VERSION ""

NS_ :

BS_:

BU_: ETH

BO_ 832 VCFRONT_alertMatrix: 8 Vector__XXX
 SG_ VCFRONT_matrixIndex M : 0|4@1+ (1,0) [0|0] "" Vector__XXX
 SG_ VCFRONT_a001_WatchdogReset m0 : 4|1@1+ (1,0) [0|0] "" Vector__XXX
 SG_ VCFRONT_a061_XCPConnected m1 : 4|1@1+ (1,0) [0|0] "" Vector__XXX
 SG_ VCFRONT_a121_pumpBatICLatchFault m2 : 4|1@1+ (1,0) [0|0] "" Vector__XXX
 SG_ VCFRONT_a181_homelinkMIA m3 : 4|1@1+ (1,0) [0|0] "" Vector__XXX
 SG_ VCFRONT_a301_wipersFactoryDisabled m5 : 4|1@1+ (1,0) [0|0] "" Vector__XXX
 SG_ VCFRONT_a361_washerFluidLowMomentary m6 : 4|1@1+ (1,0) [0|0] "" Vector__XXX
 SG_ VCFRONT_a421_leftHeadlampUartCondition m7 : 4|1@1+ (1,0) [0|0] "" Vector__XXX
 SG_ VCFRONT_a481_vnf1048SelfTestFailure m8 : 4|1@1+ (1,0) [0|0] "" Vector__XXX
 SG_ VCFRONT_a541_LVBatteryChargeOCLevel1 m9 : 4|1@1+ (1,0) [0|0] "" Vector__XXX
 SG_ VCFRONT_a601_autopilotAirPurgeLimitReached m10 : 4|1@1+ (1,0) [0|0] "" Vector__XXX
 SG_ VCFRONT_a661_mculessLeftHeadlampCurrentAlertDbg m11 : 4|1@1+ (1,0) [0|0] "" Vector__XXX
 SG_ VCFRONT_a002_PowerLossReset m0 : 5|1@1+ (1,0) [0|0] "" Vector__XXX
 SG_ VCFRONT_a062_XCPWasConnected m1 : 5|1@1+ (1,0) [0|0] "" Vector__XXX
 SG_ VCFRONT_a122_pumpBatICWarning m2 : 5|1@1+ (1,0) [0|0] "" Vector__XXX
 SG_ VCFRONT_a182_replaceLVBattery m3 : 5|1@1+ (1,0) [0|0] "" Vector__XXX
 SG_ VCFRONT_a242_drveBlckdVltgeTooLow m4 : 5|1@1+ (1,0) [0|0] "" Vector__XXX
 SG_ VCFRONT_a302_wiperCommError m5 : 5|1@1+ (1,0) [0|0] "" Vector__XXX
 SG_ VCFRONT_a362_TLVBMS_AllSocCorrectionTimeout m6 : 5|1@1+ (1,0) [0|0] "" Vector__XXX
 SG_ VCFRONT_a482_rightHeadlampMigrationDebug m8 : 5|1@1+ (1,0) [0|0] "" Vector__XXX
 SG_ VCFRONT_a542_refrigerantReclaim m9 : 5|1@1+ (1,0) [0|0] "" Vector__XXX
 SG_ VCFRONT_a662_mculessRightHeadlampCurrentAlertDbg m11 : 5|1@1+ (1,0) [0|0] "" Vector__XXX
 SG_ VCFRONT_a003_SWAssertion m0 : 6|1@1+ (1,0) [0|0] "" Vector__XXX
 SG_ VCFRONT_a063_SwitchFault m1 : 6|1@1+ (1,0) [0|0] "" Vector__XXX
 SG_ VCFRONT_a123_pumpPtICLatchFault m2 : 6|1@1+ (1,0) [0|0] "" Vector__XXX
 SG_ VCFRONT_a183_replaceLVBattery2 m3 : 6|1@1+ (1,0) [0|0] "" Vector__XXX
 SG_ VCFRONT_a243_LVOverchargeInstc m4 : 6|1@1+ (1,0) [0|0] "" Vector__XXX
 SG_ VCFRONT_a303_frunkAccessPostActive m5 : 6|1@1+ (1,0) [0|0] "" Vector__XXX
 SG_ VCFRONT_a363_TLVBMS_BleedBasedWeakShort m6 : 6|1@1+ (1,0) [0|0] "" Vector__XXX
 SG_ VCFRONT_a423_TLVBMS_BrickUnderVoltageFault m7 : 6|1@1+ (1,0) [0|0] "" Vector__XXX
 SG_ VCFRONT_a483_leftHeadlampStepperMotorFault m8 : 6|1@1+ (1,0) [0|0] "" Vector__XXX
 SG_ VCFRONT_a543_compressorLowFlowDeliveryDetected m9 : 6|1@1+ (1,0) [0|0] "" Vector__XXX
 SG_ VCFRONT_a663_leftHeadlampUartWaterMarkWarning m11 : 6|1@1+ (1,0) [0|0] "" Vector__XXX
 SG_ VCFRONT_a004_adaptiveHeadlightsUnavailable m0 : 7|1@1+ (1,0) [0|0] "" Vector__XXX
 SG_ VCFRONT_a064_busSleepReqTimeout m1 : 7|1@1+ (1,0) [0|0] "" Vector__XXX
 SG_ VCFRONT_a124_pumpPtICWarning m2 : 7|1@1+ (1,0) [0|0] "" Vector__XXX
 SG_ VCFRONT_a184_cabinCoolingPerformanceAbnormal m3 : 7|1@1+ (1,0) [0|0] "" Vector__XXX
 SG_ VCFRONT_a244_sleepBypassFault m4 : 7|1@1+ (1,0) [0|0] "" Vector__XXX
 SG_ VCFRONT_a304_frunkReleaseFailed m5 : 7|1@1+ (1,0) [0|0] "" Vector__XXX
 SG_ VCFRONT_a364_heaterTypeEstimationChanged m6 : 7|1@1+ (1,0) [0|0] "" Vector__XXX
 SG_ VCFRONT_a424_TLVBMS_BrickUnderVoltageOcv m7 : 7|1@1+ (1,0) [0|0] "" Vector__XXX
 SG_ VCFRONT_a484_headlampLevelingRideHeightDebug m8 : 7|1@1+ (1,0) [0|0] "" Vector__XXX
 SG_ VCFRONT_a544_LVBatteryCommsBusTurnedOff m9 : 7|1@1+ (1,0) [0|0] "" Vector__XXX
 SG_ VCFRONT_a664_rightHeadlampUartWaterMarkWarning m11 : 7|1@1+ (1,0) [0|0] "" Vector__XXX
 SG_ VCFRONT_a005_CANTXError m0 : 8|1@1+ (1,0) [0|0] "" Vector__XXX
 SG_ VCFRONT_a125_thmlFanICLatchFault m2 : 8|1@1+ (1,0) [0|0] "" Vector__XXX
 SG_ VCFRONT_a185_washerFluidLow m3 : 8|1@1+ (1,0) [0|0] "" Vector__XXX
 SG_ VCFRONT_a245_pump1EFuseFault m4 : 8|1@1+ (1,0) [0|0] "" Vector__XXX
 SG_ VCFRONT_a305_frunkPriOverCurrent m5 : 8|1@1+ (1,0) [0|0] "" Vector__XXX
 SG_ VCFRONT_a365_burnInRoutineEntered m6 : 8|1@1+ (1,0) [0|0] "" Vector__XXX
 SG_ VCFRONT_a425_TLVBMS_BusVoltageTooHigh m7 : 8|1@1+ (1,0) [0|0] "" Vector__XXX
 SG_ VCFRONT_a485_leftHeadlampMigrationDebug m8 : 8|1@1+ (1,0) [0|0] "" Vector__XXX
 SG_ VCFRONT_a545_LVBatteryTypeUnknown m9 : 8|1@1+ (1,0) [0|0] "" Vector__XXX
 SG_ VCFRONT_a605_sleepBypassPowerOff m10 : 8|1@1+ (1,0) [0|0] "" Vector__XXX
 SG_ VCFRONT_a665_leftHeadlampRetryInfo m11 : 8|1@1+ (1,0) [0|0] "" Vector__XXX
 SG_ VCFRONT_a006_CANTX_cyclicError m0 : 9|1@1+ (1,0) [0|0] "" Vector__XXX
 SG_ VCFRONT_a126_thmlFanICWarning m2 : 9|1@1+ (1,0) [0|0] "" Vector__XXX
 SG_ VCFRONT_a186_noDriveChgCableCon m3 : 9|1@1+ (1,0) [0|0] "" Vector__XXX
 SG_ VCFRONT_a246_pump2EFuseFault m4 : 9|1@1+ (1,0) [0|0] "" Vector__XXX
 SG_ VCFRONT_a306_frunkPriUnderCurrent m5 : 9|1@1+ (1,0) [0|0] "" Vector__XXX
 SG_ VCFRONT_a366_burnInRoutineExited m6 : 9|1@1+ (1,0) [0|0] "" Vector__XXX
 SG_ VCFRONT_a426_TLVBMS_BusVoltageTooLow m7 : 9|1@1+ (1,0) [0|0] "" Vector__XXX
 SG_ VCFRONT_a486_mcuGraphicsEFuseFault m8 : 9|1@1+ (1,0) [0|0] "" Vector__XXX
 SG_ VCFRONT_a546_leftLowOrHighBeamLightCondition m9 : 9|1@1+ (1,0) [0|0] "" Vector__XXX
 SG_ VCFRONT_a606_chillerBattHeatingExit m10 : 9|1@1+ (1,0) [0|0] "" Vector__XXX
 SG_ VCFRONT_a666_rightHeadlampRetryInfo m11 : 9|1@1+ (1,0) [0|0] "" Vector__XXX
 SG_ VCFRONT_a127_vcleftEFuseTrip m2 : 10|1@1+ (1,0) [0|0] "" Vector__XXX
 SG_ VCFRONT_a187_busesNotSleeping m3 : 10|1@1+ (1,0) [0|0] "" Vector__XXX
 SG_ VCFRONT_a247_evapSolenoidFault m4 : 10|1@1+ (1,0) [0|0] "" Vector__XXX
 SG_ VCFRONT_a307_frunkSecOverCurrent m5 : 10|1@1+ (1,0) [0|0] "" Vector__XXX
 SG_ VCFRONT_a367_dischargeRoutineEntered m6 : 10|1@1+ (1,0) [0|0] "" Vector__XXX
 SG_ VCFRONT_a427_TLVBMS_CacChange m7 : 10|1@1+ (1,0) [0|0] "" Vector__XXX
 SG_ VCFRONT_a487_leftHeadlampLastPositionUpdate m8 : 10|1@1+ (1,0) [0|0] "" Vector__XXX
 SG_ VCFRONT_a547_postCrashLoadShed m9 : 10|1@1+ (1,0) [0|0] "" Vector__XXX
 SG_ VCFRONT_a607_sleepPowerDebug m10 : 10|1@1+ (1,0) [0|0] "" Vector__XXX
 SG_ VCFRONT_a667_leftHeadlampRegionOrSideMismatch m11 : 10|1@1+ (1,0) [0|0] "" Vector__XXX
 SG_ VCFRONT_a008_adaptiveHeadlightsUnavailableStalk m0 : 11|1@1+ (1,0) [0|0] "" Vector__XXX
 SG_ VCFRONT_a128_vcrightEFuseTrip m2 : 11|1@1+ (1,0) [0|0] "" Vector__XXX
 SG_ VCFRONT_a188_sleepFailed m3 : 11|1@1+ (1,0) [0|0] "" Vector__XXX
 SG_ VCFRONT_a248_voltageOutOfSpec m4 : 11|1@1+ (1,0) [0|0] "" Vector__XXX
 SG_ VCFRONT_a308_frunkSecUnderCurrent m5 : 11|1@1+ (1,0) [0|0] "" Vector__XXX
 SG_ VCFRONT_a368_dischargeRoutineExited m6 : 11|1@1+ (1,0) [0|0] "" Vector__XXX
 SG_ VCFRONT_a428_TLVBMS_CacImbalance m7 : 11|1@1+ (1,0) [0|0] "" Vector__XXX
 SG_ VCFRONT_a488_rightHeadlampStepperMotorFault m8 : 11|1@1+ (1,0) [0|0] "" Vector__XXX
 SG_ VCFRONT_a548_HVFaultLoadShed m9 : 11|1@1+ (1,0) [0|0] "" Vector__XXX
 SG_ VCFRONT_a608_TLVBMS_BleedFetFailure m10 : 11|1@1+ (1,0) [0|0] "" Vector__XXX
 SG_ VCFRONT_a668_rightHeadlampRegionOrSideMismatch m11 : 11|1@1+ (1,0) [0|0] "" Vector__XXX
 SG_ VCFRONT_a009_LCCPurgeAttempted m0 : 12|1@1+ (1,0) [0|0] "" Vector__XXX
 SG_ VCFRONT_a129_pcsEFuseTrip m2 : 12|1@1+ (1,0) [0|0] "" Vector__XXX
 SG_ VCFRONT_a189_IBSMIA m3 : 12|1@1+ (1,0) [0|0] "" Vector__XXX
 SG_ VCFRONT_a249_coolantValveBadMode m4 : 12|1@1+ (1,0) [0|0] "" Vector__XXX
 SG_ VCFRONT_a309_frunkEmergencyReleasePressed m5 : 12|1@1+ (1,0) [0|0] "" Vector__XXX
 SG_ VCFRONT_a369_reducedPowerDischarge m6 : 12|1@1+ (1,0) [0|0] "" Vector__XXX
 SG_ VCFRONT_a429_TLVBMS_CapacityTestResults m7 : 12|1@1+ (1,0) [0|0] "" Vector__XXX
 SG_ VCFRONT_a489_ValveStuckFlagged m8 : 12|1@1+ (1,0) [0|0] "" Vector__XXX
 SG_ VCFRONT_a609_autopilotDriveNotAuthed m10 : 12|1@1+ (1,0) [0|0] "" Vector__XXX
 SG_ VCFRONT_a669_thermalHVPowerBudgetActive m11 : 12|1@1+ (1,0) [0|0] "" Vector__XXX
 SG_ VCFRONT_a010_ExtSupplyVoltError m0 : 13|1@1+ (1,0) [0|0] "" Vector__XXX
 SG_ VCFRONT_a130_epas3pEFuseTrip m2 : 13|1@1+ (1,0) [0|0] "" Vector__XXX
 SG_ VCFRONT_a190_linSchedulingInfo m3 : 13|1@1+ (1,0) [0|0] "" Vector__XXX
 SG_ VCFRONT_a250_headlampsNotAimed m4 : 13|1@1+ (1,0) [0|0] "" Vector__XXX
 SG_ VCFRONT_a310_vcleftOvertempSlope m5 : 13|1@1+ (1,0) [0|0] "" Vector__XXX
 SG_ VCFRONT_a370_noLVSupportSocTooLow m6 : 13|1@1+ (1,0) [0|0] "" Vector__XXX
 SG_ VCFRONT_a430_TLVBMS_ChargeCurrentLimitExceeded m7 : 13|1@1+ (1,0) [0|0] "" Vector__XXX
 SG_ VCFRONT_a490_coolantPumpsNotIdentified m8 : 13|1@1+ (1,0) [0|0] "" Vector__XXX
 SG_ VCFRONT_a610_frunkOpenFailureMetricSet m10 : 13|1@1+ (1,0) [0|0] "" Vector__XXX
 SG_ VCFRONT_a670_TLVBMS_EfuseStateIrrational m11 : 13|1@1+ (1,0) [0|0] "" Vector__XXX
 SG_ VCFRONT_a131_epas3sEFuseTrip m2 : 14|1@1+ (1,0) [0|0] "" Vector__XXX
 SG_ VCFRONT_a191_exitDriveLowLVBusVoltage m3 : 14|1@1+ (1,0) [0|0] "" Vector__XXX
 SG_ VCFRONT_a251_UIWakeupTrigger m4 : 14|1@1+ (1,0) [0|0] "" Vector__XXX
 SG_ VCFRONT_a311_vcrightOvertempSlope m5 : 14|1@1+ (1,0) [0|0] "" Vector__XXX
 SG_ VCFRONT_a371_failureToPrechargeRisk m6 : 14|1@1+ (1,0) [0|0] "" Vector__XXX
 SG_ VCFRONT_a431_TLVBMS_ChargeOverCurrent m7 : 14|1@1+ (1,0) [0|0] "" Vector__XXX
 SG_ VCFRONT_a491_rightHeadlampLastPositionUpdate m8 : 14|1@1+ (1,0) [0|0] "" Vector__XXX
 SG_ VCFRONT_a551_leftHeadlampSoftShort m9 : 14|1@1+ (1,0) [0|0] "" Vector__XXX
 SG_ VCFRONT_a611_poorRadiatorHeatRejection m10 : 14|1@1+ (1,0) [0|0] "" Vector__XXX
 SG_ VCFRONT_a012_CPUReset m0 : 15|1@1+ (1,0) [0|0] "" Vector__XXX
 SG_ VCFRONT_a132_iBoosterEFuseTrip m2 : 15|1@1+ (1,0) [0|0] "" Vector__XXX
 SG_ VCFRONT_a192_vehicleLoadShed m3 : 15|1@1+ (1,0) [0|0] "" Vector__XXX
 SG_ VCFRONT_a252_controllerWakeup m4 : 15|1@1+ (1,0) [0|0] "" Vector__XXX
 SG_ VCFRONT_a312_pcsOvertempSlope m5 : 15|1@1+ (1,0) [0|0] "" Vector__XXX
 SG_ VCFRONT_a372_TLVBMS_BmbHwOverVoltageFault m6 : 15|1@1+ (1,0) [0|0] "" Vector__XXX
 SG_ VCFRONT_a432_TLVBMS_ChargeRegulationFault m7 : 15|1@1+ (1,0) [0|0] "" Vector__XXX
 SG_ VCFRONT_a492_TLVBMS_SocImbalance m8 : 15|1@1+ (1,0) [0|0] "" Vector__XXX
 SG_ VCFRONT_a552_eFuseSelfTestFailure m9 : 15|1@1+ (1,0) [0|0] "" Vector__XXX
 SG_ VCFRONT_a612_LVUnhealthyLoadShed m10 : 15|1@1+ (1,0) [0|0] "" Vector__XXX
 SG_ VCFRONT_a013_AlertManagerFault m0 : 16|1@1+ (1,0) [0|0] "" Vector__XXX
 SG_ VCFRONT_a133_espEFuseTrip m2 : 16|1@1+ (1,0) [0|0] "" Vector__XXX
 SG_ VCFRONT_a193_mcuAudioRetry m3 : 16|1@1+ (1,0) [0|0] "" Vector__XXX
 SG_ VCFRONT_a253_maxChrgeSssionTmeout m4 : 16|1@1+ (1,0) [0|0] "" Vector__XXX
 SG_ VCFRONT_a313_epas3pOvertempSlope m5 : 16|1@1+ (1,0) [0|0] "" Vector__XXX
 SG_ VCFRONT_a373_chillerControlFlooding m6 : 16|1@1+ (1,0) [0|0] "" Vector__XXX
 SG_ VCFRONT_a433_TLVBMS_ConfigFromBmbModIdFailed m7 : 16|1@1+ (1,0) [0|0] "" Vector__XXX
 SG_ VCFRONT_a493_TLVBMS_SocImbalanceWarning m8 : 16|1@1+ (1,0) [0|0] "" Vector__XXX
 SG_ VCFRONT_a553_rightHeadlampSoftShort m9 : 16|1@1+ (1,0) [0|0] "" Vector__XXX
 SG_ VCFRONT_a613_selfTestsBlockingDrive m10 : 16|1@1+ (1,0) [0|0] "" Vector__XXX
 SG_ VCFRONT_a134_fusedHighEFuseTrip m2 : 17|1@1+ (1,0) [0|0] "" Vector__XXX
 SG_ VCFRONT_a194_iBoosterRetry m3 : 17|1@1+ (1,0) [0|0] "" Vector__XXX
 SG_ VCFRONT_a254_pumpBatStopped m4 : 17|1@1+ (1,0) [0|0] "" Vector__XXX
 SG_ VCFRONT_a314_epas3sOvertempSlope m5 : 17|1@1+ (1,0) [0|0] "" Vector__XXX
 SG_ VCFRONT_a374_lccInletSolenoidFault m6 : 17|1@1+ (1,0) [0|0] "" Vector__XXX
 SG_ VCFRONT_a434_TLVBMS_ConfigInitFailed m7 : 17|1@1+ (1,0) [0|0] "" Vector__XXX
 SG_ VCFRONT_a494_LVBatteryTempBlockingOTA m8 : 17|1@1+ (1,0) [0|0] "" Vector__XXX
 SG_ VCFRONT_a614_coolantSysDriverlessSelfTest m10 : 17|1@1+ (1,0) [0|0] "" Vector__XXX
 SG_ VCFRONT_a015_NVMMError m0 : 18|1@1+ (1,0) [0|0] "" Vector__XXX
 SG_ VCFRONT_a135_coolantLevelLow m2 : 18|1@1+ (1,0) [0|0] "" Vector__XXX
 SG_ VCFRONT_a195_drveBlckdVltgeTooHgh m3 : 18|1@1+ (1,0) [0|0] "" Vector__XXX
 SG_ VCFRONT_a255_pumpPtStopped m4 : 18|1@1+ (1,0) [0|0] "" Vector__XXX
 SG_ VCFRONT_a315_iboosterOvertempSlope m5 : 18|1@1+ (1,0) [0|0] "" Vector__XXX
 SG_ VCFRONT_a375_refVoltageOutOfSpec m6 : 18|1@1+ (1,0) [0|0] "" Vector__XXX
 SG_ VCFRONT_a435_TLVBMS_DchgCurrentLimitExceeded m7 : 18|1@1+ (1,0) [0|0] "" Vector__XXX
 SG_ VCFRONT_a495_LVBatteryRecoveryBlocked m8 : 18|1@1+ (1,0) [0|0] "" Vector__XXX
 SG_ VCFRONT_a555_LVBatteryCellRebalancing m9 : 18|1@1+ (1,0) [0|0] "" Vector__XXX
 SG_ VCFRONT_a615_TLVBMS_BatteryHeaterFault m10 : 18|1@1+ (1,0) [0|0] "" Vector__XXX
 SG_ VCFRONT_a016_NVMMRecordError m0 : 19|1@1+ (1,0) [0|0] "" Vector__XXX
 SG_ VCFRONT_a136_refrigDischTempSns m2 : 19|1@1+ (1,0) [0|0] "" Vector__XXX
 SG_ VCFRONT_a196_discnctdLVBattery m3 : 19|1@1+ (1,0) [0|0] "" Vector__XXX
 SG_ VCFRONT_a256_compTornShaftSeal m4 : 19|1@1+ (1,0) [0|0] "" Vector__XXX
 SG_ VCFRONT_a316_espOvertempSlope m5 : 19|1@1+ (1,0) [0|0] "" Vector__XXX
 SG_ VCFRONT_a376_controllerWakeupDebug m6 : 19|1@1+ (1,0) [0|0] "" Vector__XXX
 SG_ VCFRONT_a436_TLVBMS_DischargeOverCurrent m7 : 19|1@1+ (1,0) [0|0] "" Vector__XXX
 SG_ VCFRONT_a496_LVBatteryExitDriveWarning m8 : 19|1@1+ (1,0) [0|0] "" Vector__XXX
 SG_ VCFRONT_a556_falseTriggerOfDiscnctdBatteryTest m9 : 19|1@1+ (1,0) [0|0] "" Vector__XXX
 SG_ VCFRONT_a017_NVMMStatusDbg m0 : 20|1@1+ (1,0) [0|0] "" Vector__XXX
 SG_ VCFRONT_a137_refrigDischPresSns m2 : 20|1@1+ (1,0) [0|0] "" Vector__XXX
 SG_ VCFRONT_a197_prechargeDCRData3 m3 : 20|1@1+ (1,0) [0|0] "" Vector__XXX
 SG_ VCFRONT_a257_portExpanderVOR m4 : 20|1@1+ (1,0) [0|0] "" Vector__XXX
 SG_ VCFRONT_a317_vbatFusedOvertempSlope m5 : 20|1@1+ (1,0) [0|0] "" Vector__XXX
 SG_ VCFRONT_a377_wiperParkFault m6 : 20|1@1+ (1,0) [0|0] "" Vector__XXX
 SG_ VCFRONT_a437_TLVBMS_NvmRegistrationError m7 : 20|1@1+ (1,0) [0|0] "" Vector__XXX
 SG_ VCFRONT_a497_LVBatteryWarnDisconnect m8 : 20|1@1+ (1,0) [0|0] "" Vector__XXX
 SG_ VCFRONT_a138_refrigSuctTempSns m2 : 21|1@1+ (1,0) [0|0] "" Vector__XXX
 SG_ VCFRONT_a198_PRVCANOverterminate m3 : 21|1@1+ (1,0) [0|0] "" Vector__XXX
 SG_ VCFRONT_a258_resistanceEstimationRun m4 : 21|1@1+ (1,0) [0|0] "" Vector__XXX
 SG_ VCFRONT_a318_vcleftOvertempMax m5 : 21|1@1+ (1,0) [0|0] "" Vector__XXX
 SG_ VCFRONT_a378_wiperECUDebug m6 : 21|1@1+ (1,0) [0|0] "" Vector__XXX
 SG_ VCFRONT_a438_TLVBMS_PackOverTemperatureFault m7 : 21|1@1+ (1,0) [0|0] "" Vector__XXX
 SG_ VCFRONT_a498_TLVBMS_ImpedanceTestResults m8 : 21|1@1+ (1,0) [0|0] "" Vector__XXX
 SG_ VCFRONT_a558_rightHeadlampAimingDebug m9 : 21|1@1+ (1,0) [0|0] "" Vector__XXX
 SG_ VCFRONT_a618_cabinCoolingCapacityLimited m10 : 21|1@1+ (1,0) [0|0] "" Vector__XXX
 SG_ VCFRONT_a139_refrigSuctPresSns m2 : 22|1@1+ (1,0) [0|0] "" Vector__XXX
 SG_ VCFRONT_a199_PRVCANUndertrminate m3 : 22|1@1+ (1,0) [0|0] "" Vector__XXX
 SG_ VCFRONT_a259_LVVoltageDropOnHighLoadCurrent m4 : 22|1@1+ (1,0) [0|0] "" Vector__XXX
 SG_ VCFRONT_a319_vcrightOvertempMax m5 : 22|1@1+ (1,0) [0|0] "" Vector__XXX
 SG_ VCFRONT_a379_shortedCellTestRunDebug m6 : 22|1@1+ (1,0) [0|0] "" Vector__XXX
 SG_ VCFRONT_a439_TLVBMS_PackOverTemperatureWarning m7 : 22|1@1+ (1,0) [0|0] "" Vector__XXX
 SG_ VCFRONT_a499_loadShedPumpFlowRequest m8 : 22|1@1+ (1,0) [0|0] "" Vector__XXX
 SG_ VCFRONT_a559_LVBatteryLowSOC m9 : 22|1@1+ (1,0) [0|0] "" Vector__XXX
 SG_ VCFRONT_a619_frunkSwitchReleaseTimeDBG m10 : 22|1@1+ (1,0) [0|0] "" Vector__XXX
 SG_ VCFRONT_a140_coolantTempPtSns m2 : 23|1@1+ (1,0) [0|0] "" Vector__XXX
 SG_ VCFRONT_a200_vcleftSelfTestFail m3 : 23|1@1+ (1,0) [0|0] "" Vector__XXX
 SG_ VCFRONT_a260_deadLVBattery m4 : 23|1@1+ (1,0) [0|0] "" Vector__XXX
 SG_ VCFRONT_a320_pcsOvertempMax m5 : 23|1@1+ (1,0) [0|0] "" Vector__XXX
 SG_ VCFRONT_a380_chillerExvWarning m6 : 23|1@1+ (1,0) [0|0] "" Vector__XXX
 SG_ VCFRONT_a440_TLVBMS_PackSNInvalidForNvm m7 : 23|1@1+ (1,0) [0|0] "" Vector__XXX
 SG_ VCFRONT_a500_eFuseASICStateMismatch m8 : 23|1@1+ (1,0) [0|0] "" Vector__XXX
 SG_ VCFRONT_a560_compressorHighSuperheat m9 : 23|1@1+ (1,0) [0|0] "" Vector__XXX
 SG_ VCFRONT_a021_TaskSchedulerError m0 : 24|1@1+ (1,0) [0|0] "" Vector__XXX
 SG_ VCFRONT_a141_coolantTempBatSns m2 : 24|1@1+ (1,0) [0|0] "" Vector__XXX
 SG_ VCFRONT_a201_vcrightSelfTestFail m3 : 24|1@1+ (1,0) [0|0] "" Vector__XXX
 SG_ VCFRONT_a261_vcleftVoltageMismatch m4 : 24|1@1+ (1,0) [0|0] "" Vector__XXX
 SG_ VCFRONT_a321_epas3pOvertempMax m5 : 24|1@1+ (1,0) [0|0] "" Vector__XXX
 SG_ VCFRONT_a381_evaporatorExvWarning m6 : 24|1@1+ (1,0) [0|0] "" Vector__XXX
 SG_ VCFRONT_a441_TLVBMS_ResetNeededForNvmPackSwap m7 : 24|1@1+ (1,0) [0|0] "" Vector__XXX
 SG_ VCFRONT_a501_vnf1048ConfigurationMismatch m8 : 24|1@1+ (1,0) [0|0] "" Vector__XXX
 SG_ VCFRONT_a561_LVBMSEFuseOvertemperature m9 : 24|1@1+ (1,0) [0|0] "" Vector__XXX
 SG_ VCFRONT_a022_TaskInitError m0 : 25|1@1+ (1,0) [0|0] "" Vector__XXX
 SG_ VCFRONT_a082_VCRIGHT_IPC_MIA m1 : 25|1@1+ (1,0) [0|0] "" Vector__XXX
 SG_ VCFRONT_a142_exvMotorFault m2 : 25|1@1+ (1,0) [0|0] "" Vector__XXX
 SG_ VCFRONT_a202_pcsSelfTestFail m3 : 25|1@1+ (1,0) [0|0] "" Vector__XXX
 SG_ VCFRONT_a262_vcrightVoltageMismatch m4 : 25|1@1+ (1,0) [0|0] "" Vector__XXX
 SG_ VCFRONT_a322_epas3sOvertempMax m5 : 25|1@1+ (1,0) [0|0] "" Vector__XXX
 SG_ VCFRONT_a382_recircExvWarning m6 : 25|1@1+ (1,0) [0|0] "" Vector__XXX
 SG_ VCFRONT_a442_TLVBMS_SocChange m7 : 25|1@1+ (1,0) [0|0] "" Vector__XXX
 SG_ VCFRONT_a502_TLVBMS_WeakShortImpedance m8 : 25|1@1+ (1,0) [0|0] "" Vector__XXX
 SG_ VCFRONT_a562_LVBMSModuleOvertemperature m9 : 25|1@1+ (1,0) [0|0] "" Vector__XXX
 SG_ VCFRONT_a083_VCLEFT_IPC_MIA m1 : 26|1@1+ (1,0) [0|0] "" Vector__XXX
 SG_ VCFRONT_a143_pumpBatICTransFault m2 : 26|1@1+ (1,0) [0|0] "" Vector__XXX
 SG_ VCFRONT_a203_epas3pSelfTestFail m3 : 26|1@1+ (1,0) [0|0] "" Vector__XXX
 SG_ VCFRONT_a263_pcsVoltageMismatch m4 : 26|1@1+ (1,0) [0|0] "" Vector__XXX
 SG_ VCFRONT_a323_iboosterOvertempMax m5 : 26|1@1+ (1,0) [0|0] "" Vector__XXX
 SG_ VCFRONT_a383_lccExvWarning m6 : 26|1@1+ (1,0) [0|0] "" Vector__XXX
 SG_ VCFRONT_a443_TLVBMS_BmbDieOverTemperature m7 : 26|1@1+ (1,0) [0|0] "" Vector__XXX
 SG_ VCFRONT_a503_TLVBMS_BrickExtendedOvFault m8 : 26|1@1+ (1,0) [0|0] "" Vector__XXX
 SG_ VCFRONT_a563_chargePortDoorOpenBlockedByBrake m9 : 26|1@1+ (1,0) [0|0] "" Vector__XXX
 SG_ VCFRONT_a623_LVUnhealthy m10 : 26|1@1+ (1,0) [0|0] "" Vector__XXX
 SG_ VCFRONT_a084_TPMS_MIA m1 : 27|1@1+ (1,0) [0|0] "" Vector__XXX
 SG_ VCFRONT_a144_pumpPtICTransFault m2 : 27|1@1+ (1,0) [0|0] "" Vector__XXX
 SG_ VCFRONT_a204_epas3sSelfTestFail m3 : 27|1@1+ (1,0) [0|0] "" Vector__XXX
 SG_ VCFRONT_a264_iBoosterVoltageMismatch m4 : 27|1@1+ (1,0) [0|0] "" Vector__XXX
 SG_ VCFRONT_a324_espOvertempMax m5 : 27|1@1+ (1,0) [0|0] "" Vector__XXX
 SG_ VCFRONT_a384_ccLeftExvWarning m6 : 27|1@1+ (1,0) [0|0] "" Vector__XXX
 SG_ VCFRONT_a444_drv8703Fault m7 : 27|1@1+ (1,0) [0|0] "" Vector__XXX
 SG_ VCFRONT_a504_airInRefrigerantDetected m8 : 27|1@1+ (1,0) [0|0] "" Vector__XXX
 SG_ VCFRONT_a564_leftHeadlampAimingDebug m9 : 27|1@1+ (1,0) [0|0] "" Vector__XXX
 SG_ VCFRONT_a085_CCCM_MIA m1 : 28|1@1+ (1,0) [0|0] "" Vector__XXX
 SG_ VCFRONT_a145_thmlFanICTransFault m2 : 28|1@1+ (1,0) [0|0] "" Vector__XXX
 SG_ VCFRONT_a205_iBoosterSelfTestFail m3 : 28|1@1+ (1,0) [0|0] "" Vector__XXX
 SG_ VCFRONT_a265_ESPVoltageMismatch m4 : 28|1@1+ (1,0) [0|0] "" Vector__XXX
 SG_ VCFRONT_a325_vbatFusedOvertempMax m5 : 28|1@1+ (1,0) [0|0] "" Vector__XXX
 SG_ VCFRONT_a385_ccRightExvWarning m6 : 28|1@1+ (1,0) [0|0] "" Vector__XXX
 SG_ VCFRONT_a445_drv8703SpiFaultDBG m7 : 28|1@1+ (1,0) [0|0] "" Vector__XXX
 SG_ VCFRONT_a505_BLEFrontUnderVoltage m8 : 28|1@1+ (1,0) [0|0] "" Vector__XXX
 SG_ VCFRONT_a565_userPresenceDisplayStateMismatch m9 : 28|1@1+ (1,0) [0|0] "" Vector__XXX
 SG_ VCFRONT_a086_VCBATT_MIA m1 : 29|1@1+ (1,0) [0|0] "" Vector__XXX
 SG_ VCFRONT_a146_pumpBatSoftStall m2 : 29|1@1+ (1,0) [0|0] "" Vector__XXX
 SG_ VCFRONT_a206_espSelfTestFail m3 : 29|1@1+ (1,0) [0|0] "" Vector__XXX
 SG_ VCFRONT_a266_EPAS3pVoltageMismatch m4 : 29|1@1+ (1,0) [0|0] "" Vector__XXX
 SG_ VCFRONT_a326_vcleftSlowTripOC m5 : 29|1@1+ (1,0) [0|0] "" Vector__XXX
 SG_ VCFRONT_a386_exvMotorWarning m6 : 29|1@1+ (1,0) [0|0] "" Vector__XXX
 SG_ VCFRONT_a446_cabinHVACUnavailableContext m7 : 29|1@1+ (1,0) [0|0] "" Vector__XXX
 SG_ VCFRONT_a506_invalidRefrigerantSystemConfig m8 : 29|1@1+ (1,0) [0|0] "" Vector__XXX
 SG_ VCFRONT_a566_leftFrontTurnLightFault m9 : 29|1@1+ (1,0) [0|0] "" Vector__XXX
 SG_ VCFRONT_a626_LVBatteryResistanceIncrease m10 : 29|1@1+ (1,0) [0|0] "" Vector__XXX
 SG_ VCFRONT_a087_DIREL_MIA m1 : 30|1@1+ (1,0) [0|0] "" Vector__XXX
 SG_ VCFRONT_a147_pumpPtSoftStall m2 : 30|1@1+ (1,0) [0|0] "" Vector__XXX
 SG_ VCFRONT_a207_vbatFusdSelfTestFail m3 : 30|1@1+ (1,0) [0|0] "" Vector__XXX
 SG_ VCFRONT_a267_EPAS3sVoltageMismatch m4 : 30|1@1+ (1,0) [0|0] "" Vector__XXX
 SG_ VCFRONT_a327_vcrightSlowTripOC m5 : 30|1@1+ (1,0) [0|0] "" Vector__XXX
 SG_ VCFRONT_a387_shortedCellInstc m6 : 30|1@1+ (1,0) [0|0] "" Vector__XXX
 SG_ VCFRONT_a447_cabinHVACUnavailable m7 : 30|1@1+ (1,0) [0|0] "" Vector__XXX
 SG_ VCFRONT_a507_leftHeadlampAimingFault m8 : 30|1@1+ (1,0) [0|0] "" Vector__XXX
 SG_ VCFRONT_a567_rightFrontTurnLightFault m9 : 30|1@1+ (1,0) [0|0] "" Vector__XXX
 SG_ VCFRONT_a627_LVBatteryUnrecoverableByAnyDevice m10 : 30|1@1+ (1,0) [0|0] "" Vector__XXX
 SG_ VCFRONT_a088_DIRER_MIA m1 : 31|1@1+ (1,0) [0|0] "" Vector__XXX
 SG_ VCFRONT_a148_thmlFanSoftStall m2 : 31|1@1+ (1,0) [0|0] "" Vector__XXX
 SG_ VCFRONT_a208_brakeFluidLow m3 : 31|1@1+ (1,0) [0|0] "" Vector__XXX
 SG_ VCFRONT_a268_vbatFusedVoltageMismatch m4 : 31|1@1+ (1,0) [0|0] "" Vector__XXX
 SG_ VCFRONT_a328_pcsSlowTripOC m5 : 31|1@1+ (1,0) [0|0] "" Vector__XXX
 SG_ VCFRONT_a388_shortedCell m6 : 31|1@1+ (1,0) [0|0] "" Vector__XXX
 SG_ VCFRONT_a448_gtwSteeringBtnReset m7 : 31|1@1+ (1,0) [0|0] "" Vector__XXX
 SG_ VCFRONT_a508_TLVBMS_ImpedanceGrowth m8 : 31|1@1+ (1,0) [0|0] "" Vector__XXX
 SG_ VCFRONT_a568_leftDaytimeRunningLightFault m9 : 31|1@1+ (1,0) [0|0] "" Vector__XXX
 SG_ VCFRONT_a628_TLVBMS_BmbThermistorFault m10 : 31|1@1+ (1,0) [0|0] "" Vector__XXX
 SG_ VCFRONT_a029_CoreDump m0 : 32|1@1+ (1,0) [0|0] "" Vector__XXX
 SG_ VCFRONT_a089_IBST_MIA m1 : 32|1@1+ (1,0) [0|0] "" Vector__XXX
 SG_ VCFRONT_a149_BLEFrontPowerCycled m2 : 32|1@1+ (1,0) [0|0] "" Vector__XXX
 SG_ VCFRONT_a209_brakeFluidSNA m3 : 32|1@1+ (1,0) [0|0] "" Vector__XXX
 SG_ VCFRONT_a269_drveBlckdVltgeTooLow2 m4 : 32|1@1+ (1,0) [0|0] "" Vector__XXX
 SG_ VCFRONT_a329_epas3pSlowTripOC m5 : 32|1@1+ (1,0) [0|0] "" Vector__XXX
 SG_ VCFRONT_a389_frunkInhibitingReleaseAtSpeed m6 : 32|1@1+ (1,0) [0|0] "" Vector__XXX
 SG_ VCFRONT_a449_hornSwitchStuckOn m7 : 32|1@1+ (1,0) [0|0] "" Vector__XXX
 SG_ VCFRONT_a509_vcrightEFuseLoadShed m8 : 32|1@1+ (1,0) [0|0] "" Vector__XXX
 SG_ VCFRONT_a569_rightDaytimeRunningLightFault m9 : 32|1@1+ (1,0) [0|0] "" Vector__XXX
 SG_ VCFRONT_a629_TLVBMS_PackTemperatureIrrational m10 : 32|1@1+ (1,0) [0|0] "" Vector__XXX
 SG_ VCFRONT_a030_ECULogUploadRequest m0 : 33|1@1+ (1,0) [0|0] "" Vector__XXX
 SG_ VCFRONT_a090_APS_MIA m1 : 33|1@1+ (1,0) [0|0] "" Vector__XXX
 SG_ VCFRONT_a150_pumpBatLowRPMCBang m2 : 33|1@1+ (1,0) [0|0] "" Vector__XXX
 SG_ VCFRONT_a210_coolantValveCalib m3 : 33|1@1+ (1,0) [0|0] "" Vector__XXX
 SG_ VCFRONT_a330_epas3sSlowTripOC m5 : 33|1@1+ (1,0) [0|0] "" Vector__XXX
 SG_ VCFRONT_a390_heatPumpModeConvergence m6 : 33|1@1+ (1,0) [0|0] "" Vector__XXX
 SG_ VCFRONT_a450_hornSwitchNotPressedFactory m7 : 33|1@1+ (1,0) [0|0] "" Vector__XXX
 SG_ VCFRONT_a510_LVBatteryRecoveryTimeout m8 : 33|1@1+ (1,0) [0|0] "" Vector__XXX
 SG_ VCFRONT_a570_headlampsAdaptedToLeftHandTraffic m9 : 33|1@1+ (1,0) [0|0] "" Vector__XXX
 SG_ VCFRONT_a630_leftHeadlampFactoryFault m10 : 33|1@1+ (1,0) [0|0] "" Vector__XXX
 SG_ VCFRONT_a031_UDSActive m0 : 34|1@1+ (1,0) [0|0] "" Vector__XXX
 SG_ VCFRONT_a091_CMPD_MIA m1 : 34|1@1+ (1,0) [0|0] "" Vector__XXX
 SG_ VCFRONT_a151_pumpPtLowRPMCBang m2 : 34|1@1+ (1,0) [0|0] "" Vector__XXX
 SG_ VCFRONT_a211_I2CFault m3 : 34|1@1+ (1,0) [0|0] "" Vector__XXX
 SG_ VCFRONT_a271_LVBatteryPermSupported m4 : 34|1@1+ (1,0) [0|0] "" Vector__XXX
 SG_ VCFRONT_a331_iboosterSlowTripOC m5 : 34|1@1+ (1,0) [0|0] "" Vector__XXX
 SG_ VCFRONT_a391_frunkLatchSwitchFault m6 : 34|1@1+ (1,0) [0|0] "" Vector__XXX
 SG_ VCFRONT_a451_refrigerantNotCommissioned m7 : 34|1@1+ (1,0) [0|0] "" Vector__XXX
 SG_ VCFRONT_a511_DCDCSaturationLoadShed m8 : 34|1@1+ (1,0) [0|0] "" Vector__XXX
 SG_ VCFRONT_a571_headlampsAdaptedToRightHandTraffic m9 : 34|1@1+ (1,0) [0|0] "" Vector__XXX
 SG_ VCFRONT_a631_rightHeadlampFactoryFault m10 : 34|1@1+ (1,0) [0|0] "" Vector__XXX
 SG_ VCFRONT_a032_ipcWatchdogExpired m0 : 35|1@1+ (1,0) [0|0] "" Vector__XXX
 SG_ VCFRONT_a092_VCSEATD_MIA m1 : 35|1@1+ (1,0) [0|0] "" Vector__XXX
 SG_ VCFRONT_a152_thmlFanLowRPMCBang m2 : 35|1@1+ (1,0) [0|0] "" Vector__XXX
 SG_ VCFRONT_a212_IBSOverTemp m3 : 35|1@1+ (1,0) [0|0] "" Vector__XXX
 SG_ VCFRONT_a332_espSlowTripOC m5 : 35|1@1+ (1,0) [0|0] "" Vector__XXX
 SG_ VCFRONT_a392_TLVBMS_BmbHwUnderVoltageFault m6 : 35|1@1+ (1,0) [0|0] "" Vector__XXX
 SG_ VCFRONT_a452_dischargePresSensIntermittent m7 : 35|1@1+ (1,0) [0|0] "" Vector__XXX
 SG_ VCFRONT_a512_LVBMSFault_MOS_Open_hardwareOC m8 : 35|1@1+ (1,0) [0|0] "" Vector__XXX
 SG_ VCFRONT_a572_hvacCompressorEFuseTrip m9 : 35|1@1+ (1,0) [0|0] "" Vector__XXX
 SG_ VCFRONT_a033_eccNonCorrectableError m0 : 36|1@1+ (1,0) [0|0] "" Vector__XXX
 SG_ VCFRONT_a093_VCSEATP_MIA m1 : 36|1@1+ (1,0) [0|0] "" Vector__XXX
 SG_ VCFRONT_a153_userPresenceDisplayMismatchClrd m2 : 36|1@1+ (1,0) [0|0] "" Vector__XXX
 SG_ VCFRONT_a213_LVOvercharge m3 : 36|1@1+ (1,0) [0|0] "" Vector__XXX
 SG_ VCFRONT_a273_wiperFrictionModelFault m4 : 36|1@1+ (1,0) [0|0] "" Vector__XXX
 SG_ VCFRONT_a333_vbatFusedSlowTripOC m5 : 36|1@1+ (1,0) [0|0] "" Vector__XXX
 SG_ VCFRONT_a393_ambientTempNetworkSna m6 : 36|1@1+ (1,0) [0|0] "" Vector__XXX
 SG_ VCFRONT_a453_dischargeTempSensIntermittent m7 : 36|1@1+ (1,0) [0|0] "" Vector__XXX
 SG_ VCFRONT_a513_LVBMSFault_MOS_Open_chgOC m8 : 36|1@1+ (1,0) [0|0] "" Vector__XXX
 SG_ VCFRONT_a573_radarEFuseTrip m9 : 36|1@1+ (1,0) [0|0] "" Vector__XXX
 SG_ VCFRONT_a094_EPAS3P_MIA m1 : 37|1@1+ (1,0) [0|0] "" Vector__XXX
 SG_ VCFRONT_a154_prechargeDCRData1 m2 : 37|1@1+ (1,0) [0|0] "" Vector__XXX
 SG_ VCFRONT_a274_failureToPrechargeRisk2 m4 : 37|1@1+ (1,0) [0|0] "" Vector__XXX
 SG_ VCFRONT_a334_vcleftFastTripOCMax m5 : 37|1@1+ (1,0) [0|0] "" Vector__XXX
 SG_ VCFRONT_a394_pressureSensorCheckFault m6 : 37|1@1+ (1,0) [0|0] "" Vector__XXX
 SG_ VCFRONT_a454_suctionPresSensIntermittent m7 : 37|1@1+ (1,0) [0|0] "" Vector__XXX
 SG_ VCFRONT_a514_LVBMSFault_MOS_Open_cellUV m8 : 37|1@1+ (1,0) [0|0] "" Vector__XXX
 SG_ VCFRONT_a574_frontDriveInverterEFuseTrip m9 : 37|1@1+ (1,0) [0|0] "" Vector__XXX
 SG_ VCFRONT_a634_indeterminateSwitchTransitionDetectedDbg m10 : 37|1@1+ (1,0) [0|0] "" Vector__XXX
 SG_ VCFRONT_a095_CHG_MIA m1 : 38|1@1+ (1,0) [0|0] "" Vector__XXX
 SG_ VCFRONT_a155_prechargeDCRData2 m2 : 38|1@1+ (1,0) [0|0] "" Vector__XXX
 SG_ VCFRONT_a275_TLVBMS_BmbCommunication m4 : 38|1@1+ (1,0) [0|0] "" Vector__XXX
 SG_ VCFRONT_a335_vcrightFastTripOCMax m5 : 38|1@1+ (1,0) [0|0] "" Vector__XXX
 SG_ VCFRONT_a395_pressureSensorCheckInconclusive m6 : 38|1@1+ (1,0) [0|0] "" Vector__XXX
 SG_ VCFRONT_a455_suctionTempSensIntermittent m7 : 38|1@1+ (1,0) [0|0] "" Vector__XXX
 SG_ VCFRONT_a515_LVBMSFault_MOS_Open_cellOV m8 : 38|1@1+ (1,0) [0|0] "" Vector__XXX
 SG_ VCFRONT_a575_frontOilPumpEFuseTrip m9 : 38|1@1+ (1,0) [0|0] "" Vector__XXX
 SG_ VCFRONT_a635_rtosSleepFailed m10 : 38|1@1+ (1,0) [0|0] "" Vector__XXX
 SG_ VCFRONT_a096_OCS1P_MIA m1 : 39|1@1+ (1,0) [0|0] "" Vector__XXX
 SG_ VCFRONT_a156_louverBlockage m2 : 39|1@1+ (1,0) [0|0] "" Vector__XXX
 SG_ VCFRONT_a216_powerCutoffImminent m3 : 39|1@1+ (1,0) [0|0] "" Vector__XXX
 SG_ VCFRONT_a276_TLVBMS_BmbDataIntegrityLoss m4 : 39|1@1+ (1,0) [0|0] "" Vector__XXX
 SG_ VCFRONT_a336_pcsFastTripOCMax m5 : 39|1@1+ (1,0) [0|0] "" Vector__XXX
 SG_ VCFRONT_a396_coolantLevelLowUserFacing m6 : 39|1@1+ (1,0) [0|0] "" Vector__XXX
 SG_ VCFRONT_a456_liquidPresSensIntermittent m7 : 39|1@1+ (1,0) [0|0] "" Vector__XXX
 SG_ VCFRONT_a516_hibernationActive m8 : 39|1@1+ (1,0) [0|0] "" Vector__XXX
 SG_ VCFRONT_a576_mcuLogicEFuseTrip m9 : 39|1@1+ (1,0) [0|0] "" Vector__XXX
 SG_ VCFRONT_d636_ptCoolantPumpDetectsAirInSystem m10 : 39|1@1+ (1,0) [0|0] "" Vector__XXX
 SG_ VCFRONT_a097_CMP_MIA m1 : 40|1@1+ (1,0) [0|0] "" Vector__XXX
 SG_ VCFRONT_a157_louverBreakage m2 : 40|1@1+ (1,0) [0|0] "" Vector__XXX
 SG_ VCFRONT_a277_TLVBMS_BmbStatusRegError m4 : 40|1@1+ (1,0) [0|0] "" Vector__XXX
 SG_ VCFRONT_a337_epas3pFastTripOCMax m5 : 40|1@1+ (1,0) [0|0] "" Vector__XXX
 SG_ VCFRONT_a397_temperatureSensorCheckFault m6 : 40|1@1+ (1,0) [0|0] "" Vector__XXX
 SG_ VCFRONT_a457_liquidTempSensIntermittent m7 : 40|1@1+ (1,0) [0|0] "" Vector__XXX
 SG_ VCFRONT_a517_hibernationRecovery m8 : 40|1@1+ (1,0) [0|0] "" Vector__XXX
 SG_ VCFRONT_a577_tasEFuseTrip m9 : 40|1@1+ (1,0) [0|0] "" Vector__XXX
 SG_ VCFRONT_a697_leftHeadlampNotAimed m11 : 40|1@1+ (1,0) [0|0] "" Vector__XXX
 SG_ VCFRONT_d637_battCoolantPumpDetectsAirInSystem m10 : 40|1@1+ (1,0) [0|0] "" Vector__XXX
 SG_ VCFRONT_a038_ProtFaultInfo m0 : 41|1@1+ (1,0) [0|0] "" Vector__XXX
 SG_ VCFRONT_a098_DIR_MIA m1 : 41|1@1+ (1,0) [0|0] "" Vector__XXX
 SG_ VCFRONT_a158_louverDisconnected m2 : 41|1@1+ (1,0) [0|0] "" Vector__XXX
 SG_ VCFRONT_a218_socMonitorDetectedThresholdSoc m3 : 41|1@1+ (1,0) [0|0] "" Vector__XXX
 SG_ VCFRONT_a278_TLVBMS_BmbHwOverCurrentFault m4 : 41|1@1+ (1,0) [0|0] "" Vector__XXX
 SG_ VCFRONT_a338_epas3sFastTripOCMax m5 : 41|1@1+ (1,0) [0|0] "" Vector__XXX
 SG_ VCFRONT_a398_tempSensorCheckInconclusive m6 : 41|1@1+ (1,0) [0|0] "" Vector__XXX
 SG_ VCFRONT_a458_grosslyLowRefrigerant m7 : 41|1@1+ (1,0) [0|0] "" Vector__XXX
 SG_ VCFRONT_a518_LVBMSFault_MOS_Open_packOV m8 : 41|1@1+ (1,0) [0|0] "" Vector__XXX
 SG_ VCFRONT_a578_vbatFusedLowCurrentFeedEFuseTrip m9 : 41|1@1+ (1,0) [0|0] "" Vector__XXX
 SG_ VCFRONT_a698_rightHeadlampNotAimed m11 : 41|1@1+ (1,0) [0|0] "" Vector__XXX
 SG_ VCFRONT_d638_ptCoolantTempSensorIssue m10 : 41|1@1+ (1,0) [0|0] "" Vector__XXX
 SG_ VCFRONT_a039_ProtFaultAddress m0 : 42|1@1+ (1,0) [0|0] "" Vector__XXX
 SG_ VCFRONT_a099_PARK_MIA m1 : 42|1@1+ (1,0) [0|0] "" Vector__XXX
 SG_ VCFRONT_a159_coolantValveFault m2 : 42|1@1+ (1,0) [0|0] "" Vector__XXX
 SG_ VCFRONT_a219_LVVoltFloorRchd m3 : 42|1@1+ (1,0) [0|0] "" Vector__XXX
 SG_ VCFRONT_a279_refrigLiquidTempSns m4 : 42|1@1+ (1,0) [0|0] "" Vector__XXX
 SG_ VCFRONT_a339_iboosterFastTripOCMax m5 : 42|1@1+ (1,0) [0|0] "" Vector__XXX
 SG_ VCFRONT_a399_frunkNeverReportedOpen m6 : 42|1@1+ (1,0) [0|0] "" Vector__XXX
 SG_ VCFRONT_a459_thermalFillAndDrive m7 : 42|1@1+ (1,0) [0|0] "" Vector__XXX
 SG_ VCFRONT_a579_leftHeadlightEFuseTrip m9 : 42|1@1+ (1,0) [0|0] "" Vector__XXX
 SG_ VCFRONT_d639_batteryCoolantTempSensorIssue m10 : 42|1@1+ (1,0) [0|0] "" Vector__XXX
 SG_ VCFRONT_a040_Backtrace m0 : 43|1@1+ (1,0) [0|0] "" Vector__XXX
 SG_ VCFRONT_a100_CANbus_MIA m1 : 43|1@1+ (1,0) [0|0] "" Vector__XXX
 SG_ VCFRONT_a160_compressorInhibited m2 : 43|1@1+ (1,0) [0|0] "" Vector__XXX
 SG_ VCFRONT_a220_reverseBatteryFault m3 : 43|1@1+ (1,0) [0|0] "" Vector__XXX
 SG_ VCFRONT_a280_refrigLiquidPresSns m4 : 43|1@1+ (1,0) [0|0] "" Vector__XXX
 SG_ VCFRONT_a340_espFastTripOCMax m5 : 43|1@1+ (1,0) [0|0] "" Vector__XXX
 SG_ VCFRONT_a400_TLVBMS_BmbVrefBad m6 : 43|1@1+ (1,0) [0|0] "" Vector__XXX
 SG_ VCFRONT_a460_hardIsentropicTdFailed m7 : 43|1@1+ (1,0) [0|0] "" Vector__XXX
 SG_ VCFRONT_a580_rightHeadlightEFuseTrip m9 : 43|1@1+ (1,0) [0|0] "" Vector__XXX
 SG_ VCFRONT_d640_firmwareVersionMismatch m10 : 43|1@1+ (1,0) [0|0] "" Vector__XXX
 SG_ VCFRONT_a041_HighCPULoad m0 : 44|1@1+ (1,0) [0|0] "" Vector__XXX
 SG_ VCFRONT_a101_PM_MIA m1 : 44|1@1+ (1,0) [0|0] "" Vector__XXX
 SG_ VCFRONT_a161_compressorSelfFault m2 : 44|1@1+ (1,0) [0|0] "" Vector__XXX
 SG_ VCFRONT_a221_leftTurnLightFault m3 : 44|1@1+ (1,0) [0|0] "" Vector__XXX
 SG_ VCFRONT_a281_alcoholInterlockBlockingDrive m4 : 44|1@1+ (1,0) [0|0] "" Vector__XXX
 SG_ VCFRONT_a341_vbatFusedFastTripOCMax m5 : 44|1@1+ (1,0) [0|0] "" Vector__XXX
 SG_ VCFRONT_a401_deadLVMinimalAhDischarged m6 : 44|1@1+ (1,0) [0|0] "" Vector__XXX
 SG_ VCFRONT_a461_TLVBMS_SocHighAhError m7 : 44|1@1+ (1,0) [0|0] "" Vector__XXX
 SG_ VCFRONT_a521_vcleftEFuseLoadShed m8 : 44|1@1+ (1,0) [0|0] "" Vector__XXX
 SG_ VCFRONT_a581_windshieldWiperEFuseTrip m9 : 44|1@1+ (1,0) [0|0] "" Vector__XXX
 SG_ VCFRONT_d641_ptCoolantPumpCircuitOpen m10 : 44|1@1+ (1,0) [0|0] "" Vector__XXX
 SG_ VCFRONT_a042_HighStackUsage m0 : 45|1@1+ (1,0) [0|0] "" Vector__XXX
 SG_ VCFRONT_a102_PTC_MIA m1 : 45|1@1+ (1,0) [0|0] "" Vector__XXX
 SG_ VCFRONT_a162_compressorInhibitedContext m2 : 45|1@1+ (1,0) [0|0] "" Vector__XXX
 SG_ VCFRONT_a222_rightTurnLightFault m3 : 45|1@1+ (1,0) [0|0] "" Vector__XXX
 SG_ VCFRONT_a282_coolantLevelSensorFault m4 : 45|1@1+ (1,0) [0|0] "" Vector__XXX
 SG_ VCFRONT_a342_vcleftFastTripSlope m5 : 45|1@1+ (1,0) [0|0] "" Vector__XXX
 SG_ VCFRONT_a402_LVBatteryCannotSupportVehicle m6 : 45|1@1+ (1,0) [0|0] "" Vector__XXX
 SG_ VCFRONT_a462_LVBMSFault m7 : 45|1@1+ (1,0) [0|0] "" Vector__XXX
 SG_ VCFRONT_a522_hibernationActiveLogCapture m8 : 45|1@1+ (1,0) [0|0] "" Vector__XXX
 SG_ VCFRONT_a582_goodForPCSPowerCycle m9 : 45|1@1+ (1,0) [0|0] "" Vector__XXX
 SG_ VCFRONT_d642_batteryCoolantPumpCircuitOpen m10 : 45|1@1+ (1,0) [0|0] "" Vector__XXX
 SG_ VCFRONT_a043_Task1msError m0 : 46|1@1+ (1,0) [0|0] "" Vector__XXX
 SG_ VCFRONT_a103_CP_MIA m1 : 46|1@1+ (1,0) [0|0] "" Vector__XXX
 SG_ VCFRONT_a163_compressorDisabledFSR m2 : 46|1@1+ (1,0) [0|0] "" Vector__XXX
 SG_ VCFRONT_a223_12VTempSensDiscnect m3 : 46|1@1+ (1,0) [0|0] "" Vector__XXX
 SG_ VCFRONT_a283_thmlFanLimitedByCurrent m4 : 46|1@1+ (1,0) [0|0] "" Vector__XXX
 SG_ VCFRONT_a343_vcrightFastTripSlope m5 : 46|1@1+ (1,0) [0|0] "" Vector__XXX
 SG_ VCFRONT_a403_chargeExitHardCurrentLimit m6 : 46|1@1+ (1,0) [0|0] "" Vector__XXX
 SG_ VCFRONT_a463_frunkSensorService m7 : 46|1@1+ (1,0) [0|0] "" Vector__XXX
 SG_ VCFRONT_a523_eFuseThresholdsIncorrect m8 : 46|1@1+ (1,0) [0|0] "" Vector__XXX
 SG_ VCFRONT_a583_frunkSwitchGroupDisagreementDebug m9 : 46|1@1+ (1,0) [0|0] "" Vector__XXX
 SG_ VCFRONT_a643_rightHeadlampUartCondition m10 : 46|1@1+ (1,0) [0|0] "" Vector__XXX
 SG_ VCFRONT_a044_Task10msError m0 : 47|1@1+ (1,0) [0|0] "" Vector__XXX
 SG_ VCFRONT_a104_DAS_MIA m1 : 47|1@1+ (1,0) [0|0] "" Vector__XXX
 SG_ VCFRONT_a164_eFuseLckoutMissing m2 : 47|1@1+ (1,0) [0|0] "" Vector__XXX
 SG_ VCFRONT_a224_revBatChrgPmpFault m3 : 47|1@1+ (1,0) [0|0] "" Vector__XXX
 SG_ VCFRONT_a284_chillerExvFault m4 : 47|1@1+ (1,0) [0|0] "" Vector__XXX
 SG_ VCFRONT_a344_pcsFastTripSlope m5 : 47|1@1+ (1,0) [0|0] "" Vector__XXX
 SG_ VCFRONT_a404_resistanceEstimationHardFailure m6 : 47|1@1+ (1,0) [0|0] "" Vector__XXX
 SG_ VCFRONT_a464_highFlowIndexHighSubcoolFlagged m7 : 47|1@1+ (1,0) [0|0] "" Vector__XXX
 SG_ VCFRONT_a524_rightHeadlampAimingFault m8 : 47|1@1+ (1,0) [0|0] "" Vector__XXX
 SG_ VCFRONT_a584_frunkSwitchGroupDebug m9 : 47|1@1+ (1,0) [0|0] "" Vector__XXX
 SG_ VCFRONT_a644_washPumpHealthCalculationDbg0 m10 : 47|1@1+ (1,0) [0|0] "" Vector__XXX
 SG_ VCFRONT_a045_Task100msError m0 : 48|1@1+ (1,0) [0|0] "" Vector__XXX
 SG_ VCFRONT_a105_TAS_MIA m1 : 48|1@1+ (1,0) [0|0] "" Vector__XXX
 SG_ VCFRONT_a165_unxpctdEFuseLckout m2 : 48|1@1+ (1,0) [0|0] "" Vector__XXX
 SG_ VCFRONT_a225_driveBlckdByShowroom m3 : 48|1@1+ (1,0) [0|0] "" Vector__XXX
 SG_ VCFRONT_a285_evaporatorExvFault m4 : 48|1@1+ (1,0) [0|0] "" Vector__XXX
 SG_ VCFRONT_a345_epas3pFastTripSlope m5 : 48|1@1+ (1,0) [0|0] "" Vector__XXX
 SG_ VCFRONT_a405_dcrData1 m6 : 48|1@1+ (1,0) [0|0] "" Vector__XXX
 SG_ VCFRONT_a465_lowFlowIndexHighSubcoolFlagged m7 : 48|1@1+ (1,0) [0|0] "" Vector__XXX
 SG_ VCFRONT_a525_LVBatterySWMisconfiguration m8 : 48|1@1+ (1,0) [0|0] "" Vector__XXX
 SG_ VCFRONT_a585_bothHeadlampsInternalError m9 : 48|1@1+ (1,0) [0|0] "" Vector__XXX
 SG_ VCFRONT_a645_washPumpHealthCalculationDbg1 m10 : 48|1@1+ (1,0) [0|0] "" Vector__XXX
 SG_ VCFRONT_a046_Task1000msError m0 : 49|1@1+ (1,0) [0|0] "" Vector__XXX
 SG_ VCFRONT_a106_PCS_MIA m1 : 49|1@1+ (1,0) [0|0] "" Vector__XXX
 SG_ VCFRONT_a166_rightHCMMIA m2 : 49|1@1+ (1,0) [0|0] "" Vector__XXX
 SG_ VCFRONT_a286_recircExvFault m4 : 49|1@1+ (1,0) [0|0] "" Vector__XXX
 SG_ VCFRONT_a346_epas3sFastTripSlope m5 : 49|1@1+ (1,0) [0|0] "" Vector__XXX
 SG_ VCFRONT_a406_dcrData2 m6 : 49|1@1+ (1,0) [0|0] "" Vector__XXX
 SG_ VCFRONT_a466_highFlowIndexLowSubcoolFlagged m7 : 49|1@1+ (1,0) [0|0] "" Vector__XXX
 SG_ VCFRONT_a586_rightLowOrHighBeamLightCondition m9 : 49|1@1+ (1,0) [0|0] "" Vector__XXX
 SG_ VCFRONT_a646_washPumpHealthCalculationDbg2 m10 : 49|1@1+ (1,0) [0|0] "" Vector__XXX
 SG_ VCFRONT_a047_resetReason m0 : 50|1@1+ (1,0) [0|0] "" Vector__XXX
 SG_ VCFRONT_a107_BMS_MIA m1 : 50|1@1+ (1,0) [0|0] "" Vector__XXX
 SG_ VCFRONT_a167_leftHCMMIA m2 : 50|1@1+ (1,0) [0|0] "" Vector__XXX
 SG_ VCFRONT_a287_lccExvFault m4 : 50|1@1+ (1,0) [0|0] "" Vector__XXX
 SG_ VCFRONT_a347_iboosterFastTripSlope m5 : 50|1@1+ (1,0) [0|0] "" Vector__XXX
 SG_ VCFRONT_a407_dcrMilliOhmsAboveThreshold m6 : 50|1@1+ (1,0) [0|0] "" Vector__XXX
 SG_ VCFRONT_a467_lowPowerIndexFlagged m7 : 50|1@1+ (1,0) [0|0] "" Vector__XXX
 SG_ VCFRONT_a527_LVBatteryCellImbalance m8 : 50|1@1+ (1,0) [0|0] "" Vector__XXX
 SG_ VCFRONT_a587_externalLVPowerSupply m9 : 50|1@1+ (1,0) [0|0] "" Vector__XXX
 SG_ VCFRONT_d647_louverCommLost m10 : 50|1@1+ (1,0) [0|0] "" Vector__XXX
 SG_ VCFRONT_a108_DIF_MIA m1 : 51|1@1+ (1,0) [0|0] "" Vector__XXX
 SG_ VCFRONT_a168_hcmShortToVBAT m2 : 51|1@1+ (1,0) [0|0] "" Vector__XXX
 SG_ VCFRONT_a228_pumpBatFbkSanity m3 : 51|1@1+ (1,0) [0|0] "" Vector__XXX
 SG_ VCFRONT_a288_ccLeftExvFault m4 : 51|1@1+ (1,0) [0|0] "" Vector__XXX
 SG_ VCFRONT_a348_espFastTripSlope m5 : 51|1@1+ (1,0) [0|0] "" Vector__XXX
 SG_ VCFRONT_a408_standbyChargeProfileHardExit m6 : 51|1@1+ (1,0) [0|0] "" Vector__XXX
 SG_ VCFRONT_a468_highPowerIndexFlagged m7 : 51|1@1+ (1,0) [0|0] "" Vector__XXX
 SG_ VCFRONT_a528_LVBatteryCommsDiscnctd m8 : 51|1@1+ (1,0) [0|0] "" Vector__XXX
 SG_ VCFRONT_a588_vcleftPwrRationalityCurve m9 : 51|1@1+ (1,0) [0|0] "" Vector__XXX
 SG_ VCFRONT_d648_louverBlocked m10 : 51|1@1+ (1,0) [0|0] "" Vector__XXX
 SG_ VCFRONT_a109_RCM_MIA m1 : 52|1@1+ (1,0) [0|0] "" Vector__XXX
 SG_ VCFRONT_a169_hcmPhaseEnableFail m2 : 52|1@1+ (1,0) [0|0] "" Vector__XXX
 SG_ VCFRONT_a229_pumpPtFbkSanity m3 : 52|1@1+ (1,0) [0|0] "" Vector__XXX
 SG_ VCFRONT_a289_ccRightExvFault m4 : 52|1@1+ (1,0) [0|0] "" Vector__XXX
 SG_ VCFRONT_a349_vbatFusedFastTripSlope m5 : 52|1@1+ (1,0) [0|0] "" Vector__XXX
 SG_ VCFRONT_a409_invalidConfiguration m6 : 52|1@1+ (1,0) [0|0] "" Vector__XXX
 SG_ VCFRONT_a469_prvPopDetected m7 : 52|1@1+ (1,0) [0|0] "" Vector__XXX
 SG_ VCFRONT_a529_discnctdBatteryStateUnknown m8 : 52|1@1+ (1,0) [0|0] "" Vector__XXX
 SG_ VCFRONT_a589_vcleftFastBlowDetection m9 : 52|1@1+ (1,0) [0|0] "" Vector__XXX
 SG_ VCFRONT_a649_persistAccPortPowerReqOverridden m10 : 52|1@1+ (1,0) [0|0] "" Vector__XXX
 SG_ VCFRONT_a110_GTW_MIA m1 : 53|1@1+ (1,0) [0|0] "" Vector__XXX
 SG_ VCFRONT_a170_hcmUnderVoltage m2 : 53|1@1+ (1,0) [0|0] "" Vector__XXX
 SG_ VCFRONT_a230_thmlFanFbkSanity m3 : 53|1@1+ (1,0) [0|0] "" Vector__XXX
 SG_ VCFRONT_a290_leftFogLightFault m4 : 53|1@1+ (1,0) [0|0] "" Vector__XXX
 SG_ VCFRONT_a350_espValveCurrentSenseSaturated m5 : 53|1@1+ (1,0) [0|0] "" Vector__XXX
 SG_ VCFRONT_a410_LVBatteryDataCollection1 m6 : 53|1@1+ (1,0) [0|0] "" Vector__XXX
 SG_ VCFRONT_a470_implausiblePdPlDetected m7 : 53|1@1+ (1,0) [0|0] "" Vector__XXX
 SG_ VCFRONT_a530_sharpCurrentRise m8 : 53|1@1+ (1,0) [0|0] "" Vector__XXX
 SG_ VCFRONT_a590_vcrightPwrRationalityCurve m9 : 53|1@1+ (1,0) [0|0] "" Vector__XXX
 SG_ VCFRONT_d650_lowCoolantLevel m10 : 53|1@1+ (1,0) [0|0] "" Vector__XXX
 SG_ VCFRONT_a111_EPBR_MIA m1 : 54|1@1+ (1,0) [0|0] "" Vector__XXX
 SG_ VCFRONT_a171_driveBlckdByMsmtch m2 : 54|1@1+ (1,0) [0|0] "" Vector__XXX
 SG_ VCFRONT_a231_12VTempSensShort m3 : 54|1@1+ (1,0) [0|0] "" Vector__XXX
 SG_ VCFRONT_a291_rightFogLightFault m4 : 54|1@1+ (1,0) [0|0] "" Vector__XXX
 SG_ VCFRONT_a351_emergencyFrunkButtonPressIgnored m5 : 54|1@1+ (1,0) [0|0] "" Vector__XXX
 SG_ VCFRONT_a411_LVBatteryDataCollection2 m6 : 54|1@1+ (1,0) [0|0] "" Vector__XXX
 SG_ VCFRONT_a531_lowPowerIndexFlaggedUserFacing m8 : 54|1@1+ (1,0) [0|0] "" Vector__XXX
 SG_ VCFRONT_a591_vcrightFastBlowDetection m9 : 54|1@1+ (1,0) [0|0] "" Vector__XXX
 SG_ VCFRONT_d651_ptCoolantPumpStall m10 : 54|1@1+ (1,0) [0|0] "" Vector__XXX
 SG_ VCFRONT_a112_EPBL_MIA m1 : 55|1@1+ (1,0) [0|0] "" Vector__XXX
 SG_ VCFRONT_a172_wsteHtBlckdByMsmtch m2 : 55|1@1+ (1,0) [0|0] "" Vector__XXX
 SG_ VCFRONT_a232_lowSideControllerHighFdbk m3 : 55|1@1+ (1,0) [0|0] "" Vector__XXX
 SG_ VCFRONT_a292_sideMarkerLightPipeFault m4 : 55|1@1+ (1,0) [0|0] "" Vector__XXX
 SG_ VCFRONT_a352_audioCurrentSpikeData m5 : 55|1@1+ (1,0) [0|0] "" Vector__XXX
 SG_ VCFRONT_a412_dcrData3 m6 : 55|1@1+ (1,0) [0|0] "" Vector__XXX
 SG_ VCFRONT_a472_leftHeadlampRangeUpdate m7 : 55|1@1+ (1,0) [0|0] "" Vector__XXX
 SG_ VCFRONT_a532_gtwMIAInDrive m8 : 55|1@1+ (1,0) [0|0] "" Vector__XXX
 SG_ VCFRONT_a592_vcleftCurvePowerCutoff m9 : 55|1@1+ (1,0) [0|0] "" Vector__XXX
 SG_ VCFRONT_d652_ptCoolantPumpCircuitIssue m10 : 55|1@1+ (1,0) [0|0] "" Vector__XXX
 SG_ VCFRONT_a053_wiperCommErrorUser m0 : 56|1@1+ (1,0) [0|0] "" Vector__XXX
 SG_ VCFRONT_a113_UI_MIA m1 : 56|1@1+ (1,0) [0|0] "" Vector__XXX
 SG_ VCFRONT_a173_HVBlckdByMsmtch m2 : 56|1@1+ (1,0) [0|0] "" Vector__XXX
 SG_ VCFRONT_a233_autopilot1EFuseFault m3 : 56|1@1+ (1,0) [0|0] "" Vector__XXX
 SG_ VCFRONT_a293_interiorFrunkLightFault m4 : 56|1@1+ (1,0) [0|0] "" Vector__XXX
 SG_ VCFRONT_a353_wiperHeaterUndercurrent m5 : 56|1@1+ (1,0) [0|0] "" Vector__XXX
 SG_ VCFRONT_a413_TLVBMS_BmbVrefWarning m6 : 56|1@1+ (1,0) [0|0] "" Vector__XXX
 SG_ VCFRONT_a473_rightHeadlampRangeUpdate m7 : 56|1@1+ (1,0) [0|0] "" Vector__XXX
 SG_ VCFRONT_a533_TLVBMS_MosfetOverTemperatureFault m8 : 56|1@1+ (1,0) [0|0] "" Vector__XXX
 SG_ VCFRONT_a593_vcleftFastBlowPowerCutoff m9 : 56|1@1+ (1,0) [0|0] "" Vector__XXX
 SG_ VCFRONT_d653_ptCoolantPumpCommLost m10 : 56|1@1+ (1,0) [0|0] "" Vector__XXX
 SG_ VCFRONT_a054_compressorLowFlowUserFacing m0 : 57|1@1+ (1,0) [0|0] "" Vector__XXX
 SG_ VCFRONT_a114_ESP_MIA m1 : 57|1@1+ (1,0) [0|0] "" Vector__XXX
 SG_ VCFRONT_a174_driveNotAuthed m2 : 57|1@1+ (1,0) [0|0] "" Vector__XXX
 SG_ VCFRONT_a234_autopilot2EFuseFault m3 : 57|1@1+ (1,0) [0|0] "" Vector__XXX
 SG_ VCFRONT_a294_leftSideRepeaterLightFault m4 : 57|1@1+ (1,0) [0|0] "" Vector__XXX
 SG_ VCFRONT_a354_windshieldCameraHeaterUndercurrent m5 : 57|1@1+ (1,0) [0|0] "" Vector__XXX
 SG_ VCFRONT_a414_prechargeLVLoadReduction m6 : 57|1@1+ (1,0) [0|0] "" Vector__XXX
 SG_ VCFRONT_a474_leftHeadlampInternalError m7 : 57|1@1+ (1,0) [0|0] "" Vector__XXX
 SG_ VCFRONT_a534_chillerExvCalibInitDebug m8 : 57|1@1+ (1,0) [0|0] "" Vector__XXX
 SG_ VCFRONT_a594_virtualPitchConversionDebug m9 : 57|1@1+ (1,0) [0|0] "" Vector__XXX
 SG_ VCFRONT_d654_batteryCoolantPumpStall m10 : 57|1@1+ (1,0) [0|0] "" Vector__XXX
 SG_ VCFRONT_a115_VCSEC_MIA m1 : 58|1@1+ (1,0) [0|0] "" Vector__XXX
 SG_ VCFRONT_a175_ambientTempSns m2 : 58|1@1+ (1,0) [0|0] "" Vector__XXX
 SG_ VCFRONT_a235_ptTempSnsIrrational m3 : 58|1@1+ (1,0) [0|0] "" Vector__XXX
 SG_ VCFRONT_a295_rightSideRepeaterLightFault m4 : 58|1@1+ (1,0) [0|0] "" Vector__XXX
 SG_ VCFRONT_a355_coolantSysLockout m5 : 58|1@1+ (1,0) [0|0] "" Vector__XXX
 SG_ VCFRONT_a415_prechargeLVLoadReduction2 m6 : 58|1@1+ (1,0) [0|0] "" Vector__XXX
 SG_ VCFRONT_a475_rightHeadlampInternalError m7 : 58|1@1+ (1,0) [0|0] "" Vector__XXX
 SG_ VCFRONT_a535_evapExvCalibInitDebug m8 : 58|1@1+ (1,0) [0|0] "" Vector__XXX
 SG_ VCFRONT_a595_voltageSensorMismatch m9 : 58|1@1+ (1,0) [0|0] "" Vector__XXX
 SG_ VCFRONT_d655_batteryCoolantPumpCircuitIssue m10 : 58|1@1+ (1,0) [0|0] "" Vector__XXX
 SG_ VCFRONT_a116_VCRIGHT_MIA m1 : 59|1@1+ (1,0) [0|0] "" Vector__XXX
 SG_ VCFRONT_a176_vehicleInSelfTest m2 : 59|1@1+ (1,0) [0|0] "" Vector__XXX
 SG_ VCFRONT_a236_batTempSnsIrrational m3 : 59|1@1+ (1,0) [0|0] "" Vector__XXX
 SG_ VCFRONT_a296_turnSignalIssue m4 : 59|1@1+ (1,0) [0|0] "" Vector__XXX
 SG_ VCFRONT_a356_refrigSysLockout m5 : 59|1@1+ (1,0) [0|0] "" Vector__XXX
 SG_ VCFRONT_a416_TLVBMS_BrickOverDischarged m6 : 59|1@1+ (1,0) [0|0] "" Vector__XXX
 SG_ VCFRONT_a476_LVBMSMIA m7 : 59|1@1+ (1,0) [0|0] "" Vector__XXX
 SG_ VCFRONT_a536_recircExvCalibInitDebug m8 : 59|1@1+ (1,0) [0|0] "" Vector__XXX
 SG_ VCFRONT_a596_vcrightCurvePowerCutoff m9 : 59|1@1+ (1,0) [0|0] "" Vector__XXX
 SG_ VCFRONT_d656_batteryCoolantPumpCommLost m10 : 59|1@1+ (1,0) [0|0] "" Vector__XXX
 SG_ VCFRONT_a057_HVP_MIA m0 : 60|1@1+ (1,0) [0|0] "" Vector__XXX
 SG_ VCFRONT_a117_VCLEFT_MIA m1 : 60|1@1+ (1,0) [0|0] "" Vector__XXX
 SG_ VCFRONT_a177_mcuAudioEFuseFault m2 : 60|1@1+ (1,0) [0|0] "" Vector__XXX
 SG_ VCFRONT_a237_pumpBatChipComms m3 : 60|1@1+ (1,0) [0|0] "" Vector__XXX
 SG_ VCFRONT_a297_TLVBMS_BmbHwOverTemperatureFault m4 : 60|1@1+ (1,0) [0|0] "" Vector__XXX
 SG_ VCFRONT_a357_hornUndercurrent m5 : 60|1@1+ (1,0) [0|0] "" Vector__XXX
 SG_ VCFRONT_a417_TLVBMS_BrickOverVoltageFault m6 : 60|1@1+ (1,0) [0|0] "" Vector__XXX
 SG_ VCFRONT_a477_LVBatteryUnrecoverableByVehicle m7 : 60|1@1+ (1,0) [0|0] "" Vector__XXX
 SG_ VCFRONT_a537_lccExvCalibInitDebug m8 : 60|1@1+ (1,0) [0|0] "" Vector__XXX
 SG_ VCFRONT_a597_vcrightFastBlowPowerCutoff m9 : 60|1@1+ (1,0) [0|0] "" Vector__XXX
 SG_ VCFRONT_d657_radiatorFanOperationIssue m10 : 60|1@1+ (1,0) [0|0] "" Vector__XXX
 SG_ VCFRONT_a058_inputRHighSyncDebug m0 : 61|1@1+ (1,0) [0|0] "" Vector__XXX
 SG_ VCFRONT_a118_VCFRONT_MIA m1 : 61|1@1+ (1,0) [0|0] "" Vector__XXX
 SG_ VCFRONT_a178_compLiquidPumpOut m2 : 61|1@1+ (1,0) [0|0] "" Vector__XXX
 SG_ VCFRONT_a238_pumpPtChipComms m3 : 61|1@1+ (1,0) [0|0] "" Vector__XXX
 SG_ VCFRONT_a298_radiatorLowAirFlowDetected m4 : 61|1@1+ (1,0) [0|0] "" Vector__XXX
 SG_ VCFRONT_a358_hornOvercurrent m5 : 61|1@1+ (1,0) [0|0] "" Vector__XXX
 SG_ VCFRONT_a418_TLVBMS_BrickOverVoltageWarning m6 : 61|1@1+ (1,0) [0|0] "" Vector__XXX
 SG_ VCFRONT_a478_LVBMS_MOSFET_Open m7 : 61|1@1+ (1,0) [0|0] "" Vector__XXX
 SG_ VCFRONT_a538_cclExvCalibInitDebug m8 : 61|1@1+ (1,0) [0|0] "" Vector__XXX
 SG_ VCFRONT_a598_eFuseSelfTestFailureService m9 : 61|1@1+ (1,0) [0|0] "" Vector__XXX
 SG_ VCFRONT_d658_radiatorFanCircuitIssue m10 : 61|1@1+ (1,0) [0|0] "" Vector__XXX
 SG_ VCFRONT_a059_inputResistanceHigh m0 : 62|1@1+ (1,0) [0|0] "" Vector__XXX
 SG_ VCFRONT_a119_SCCM_MIA m1 : 62|1@1+ (1,0) [0|0] "" Vector__XXX
 SG_ VCFRONT_a179_highLVAmpsIntoPCS m2 : 62|1@1+ (1,0) [0|0] "" Vector__XXX
 SG_ VCFRONT_a239_thmlFanChipComms m3 : 62|1@1+ (1,0) [0|0] "" Vector__XXX
 SG_ VCFRONT_a299_homelinkConfigurationFailed m4 : 62|1@1+ (1,0) [0|0] "" Vector__XXX
 SG_ VCFRONT_a359_postPORExcessiveAh m5 : 62|1@1+ (1,0) [0|0] "" Vector__XXX
 SG_ VCFRONT_a419_TLVBMS_BrickSocLow m6 : 62|1@1+ (1,0) [0|0] "" Vector__XXX
 SG_ VCFRONT_a479_LVBMS_ECPA_NotClosed m7 : 62|1@1+ (1,0) [0|0] "" Vector__XXX
 SG_ VCFRONT_a539_ccrExvCalibInitDebug m8 : 62|1@1+ (1,0) [0|0] "" Vector__XXX
 SG_ VCFRONT_a599_LVBatteryTypeUnsupported m9 : 62|1@1+ (1,0) [0|0] "" Vector__XXX
 SG_ VCFRONT_d659_radiatorFanCommLost m10 : 62|1@1+ (1,0) [0|0] "" Vector__XXX
 SG_ VCFRONT_a060_engineeringBuild m0 : 63|1@1+ (1,0) [0|0] "" Vector__XXX
 SG_ VCFRONT_a120_DI_DRIVE_MIA m1 : 63|1@1+ (1,0) [0|0] "" Vector__XXX
 SG_ VCFRONT_a180_DCDCNotSupportingLVBus m2 : 63|1@1+ (1,0) [0|0] "" Vector__XXX
 SG_ VCFRONT_a240_lowSideCompromised m3 : 63|1@1+ (1,0) [0|0] "" Vector__XXX
 SG_ VCFRONT_a300_louverActuatorSwapDetected m4 : 63|1@1+ (1,0) [0|0] "" Vector__XXX
 SG_ VCFRONT_a360_ungracefulAccPlusExit m5 : 63|1@1+ (1,0) [0|0] "" Vector__XXX
 SG_ VCFRONT_a420_holidayParty m6 : 63|1@1+ (1,0) [0|0] "" Vector__XXX
 SG_ VCFRONT_a480_vnf1048Fault m7 : 63|1@1+ (1,0) [0|0] "" Vector__XXX
 SG_ VCFRONT_a540_radiatorSteamDetected m8 : 63|1@1+ (1,0) [0|0] "" Vector__XXX
 SG_ VCFRONT_a600_currentSensorMismatch m9 : 63|1@1+ (1,0) [0|0] "" Vector__XXX
 SG_ VCFRONT_d660_coolantValveCircuitIssue m10 : 63|1@1+ (1,0) [0|0] "" Vector__XXX

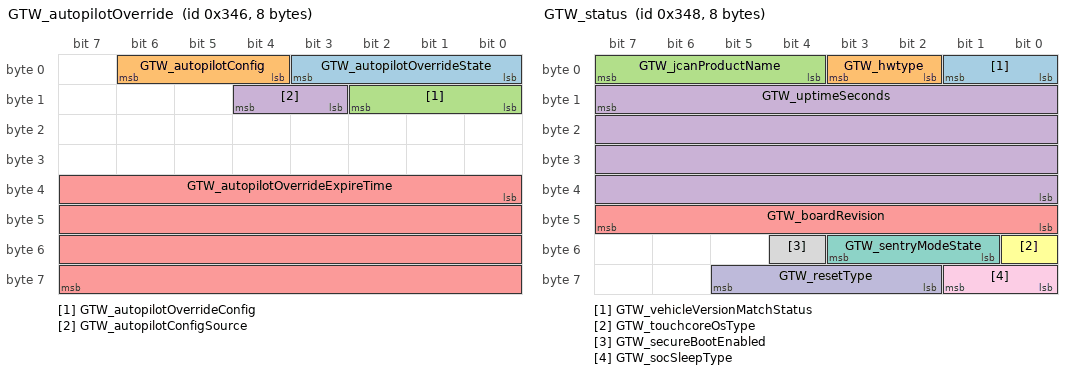
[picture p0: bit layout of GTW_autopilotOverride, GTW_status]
BO_ 838 GTW_autopilotOverride: 8 Vector__XXX
 SG_ GTW_autopilotOverrideState : 0|4@1+ (1,0) [0|0] "" Vector__XXX
 SG_ GTW_autopilotConfig : 4|3@1+ (1,0) [0|0] "" Vector__XXX
 SG_ GTW_autopilotOverrideConfig : 8|3@1+ (1,0) [0|0] "" Vector__XXX
 SG_ GTW_autopilotConfigSource : 11|2@1+ (1,0) [0|0] "" Vector__XXX
 SG_ GTW_autopilotOverrideExpireTime : 32|32@1+ (1,0) [0|0] "" Vector__XXX

BO_ 840 GTW_status: 8 Vector__XXX
 SG_ GTW_vehicleVersionMatchStatus : 0|2@1+ (1,0) [0|0] "" Vector__XXX
 SG_ GTW_hwtype : 2|2@1+ (1,0) [0|0] "" Vector__XXX
 SG_ GTW_jcanProductName : 4|4@1+ (1,0) [0|0] "" Vector__XXX
 SG_ GTW_uptimeSeconds : 15|32@0+ (1,0) [0|0] "" Vector__XXX
 SG_ GTW_boardRevision : 40|8@1+ (1,0) [0|0] "" Vector__XXX
 SG_ GTW_touchcoreOsType : 48|1@1+ (1,0) [0|0] "" Vector__XXX
 SG_ GTW_sentryModeState : 49|3@1+ (1,0) [0|0] "" Vector__XXX
 SG_ GTW_secureBootEnabled : 52|1@1+ (1,0) [0|0] "" Vector__XXX
 SG_ GTW_socSleepType : 56|2@1+ (1,0) [0|0] "" Vector__XXX
 SG_ GTW_resetType : 58|4@1+ (1,0) [0|0] "" Vector__XXX

BO_ 841 DAS_warningMatrix2: 8 Vector__XXX
 SG_ DAS_w129_mainCamExtNotCal : 0|1@1+ (1,0) [0|0] "" Vector__XXX
 SG_ DAS_w130_narrowCamExtNotCal : 1|1@1+ (1,0) [0|0] "" Vector__XXX
 SG_ DAS_w131_mainCamCalSaved : 2|1@1+ (1,0) [0|0] "" Vector__XXX
 SG_ DAS_w132_narrowCamCalSaved : 3|1@1+ (1,0) [0|0] "" Vector__XXX
 SG_ DAS_w133_mainCamInitFault : 4|1@1+ (1,0) [0|0] "" Vector__XXX
 SG_ DAS_w134_narrowCamInitFault : 5|1@1+ (1,0) [0|0] "" Vector__XXX
 SG_ DAS_w135_fisheyeCamInitFault : 6|1@1+ (1,0) [0|0] "" Vector__XXX
 SG_ DAS_w136_lPillarCamInitFault : 7|1@1+ (1,0) [0|0] "" Vector__XXX
 SG_ DAS_w137_rPillarCamInitFault : 8|1@1+ (1,0) [0|0] "" Vector__XXX
 SG_ DAS_w138_lRepeatCamInitFault : 9|1@1+ (1,0) [0|0] "" Vector__XXX
 SG_ DAS_w139_rRepeatCamInitFault : 10|1@1+ (1,0) [0|0] "" Vector__XXX
 SG_ DAS_w140_backupCamInitFault : 11|1@1+ (1,0) [0|0] "" Vector__XXX
 SG_ DAS_w141_ECU_Thermal_Issue : 12|1@1+ (1,0) [0|0] "" Vector__XXX
 SG_ DAS_w142_fwdCamPitchProblem : 13|1@1+ (1,0) [0|0] "" Vector__XXX
 SG_ DAS_w143_IDF_event : 14|1@1+ (1,0) [0|0] "" Vector__XXX
 SG_ DAS_w144_selfieCamInitFault : 15|1@1+ (1,0) [0|0] "" Vector__XXX
 SG_ DAS_w171_fisheyeCamExtNotCal : 42|1@1+ (1,0) [0|0] "" Vector__XXX
 SG_ DAS_w172_lPillarCamExtNotCal : 43|1@1+ (1,0) [0|0] "" Vector__XXX
 SG_ DAS_w173_rPillarCamExtNotCal : 44|1@1+ (1,0) [0|0] "" Vector__XXX
 SG_ DAS_w174_lRepeatCamExtNotCal : 45|1@1+ (1,0) [0|0] "" Vector__XXX
 SG_ DAS_w175_rRepeatCamExtNotCal : 46|1@1+ (1,0) [0|0] "" Vector__XXX
 SG_ DAS_w177_fisheyeCamCalSaved : 48|1@1+ (1,0) [0|0] "" Vector__XXX
 SG_ DAS_w178_lPillarCamCalSaved : 49|1@1+ (1,0) [0|0] "" Vector__XXX
 SG_ DAS_w179_rPillarCamCalSaved : 50|1@1+ (1,0) [0|0] "" Vector__XXX
 SG_ DAS_w180_lRepeatCamCalSaved : 51|1@1+ (1,0) [0|0] "" Vector__XXX
 SG_ DAS_w181_rRepeatCamCalSaved : 52|1@1+ (1,0) [0|0] "" Vector__XXX

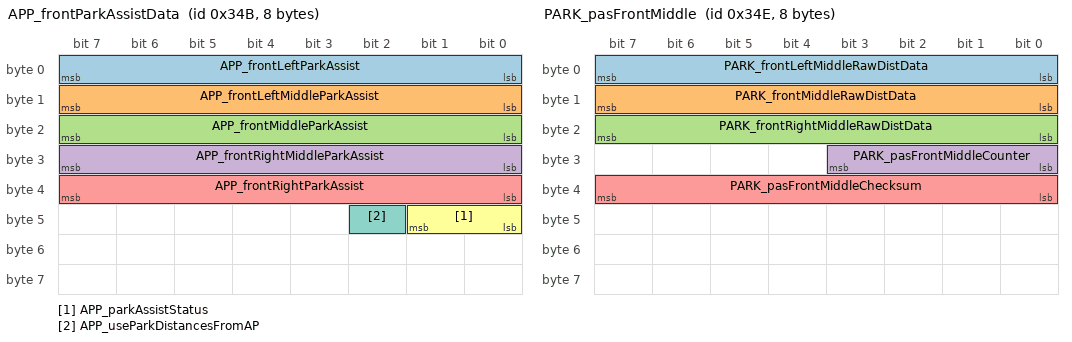
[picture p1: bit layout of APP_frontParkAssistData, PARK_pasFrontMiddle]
BO_ 843 APP_frontParkAssistData: 8 Vector__XXX
 SG_ APP_frontLeftParkAssist : 0|8@1+ (1,0) [0|0] "" Vector__XXX
 SG_ APP_frontLeftMiddleParkAssist : 8|8@1+ (1,0) [0|0] "" Vector__XXX
 SG_ APP_frontMiddleParkAssist : 16|8@1+ (1,0) [0|0] "" Vector__XXX
 SG_ APP_frontRightMiddleParkAssist : 24|8@1+ (1,0) [0|0] "" Vector__XXX
 SG_ APP_frontRightParkAssist : 32|8@1+ (1,0) [0|0] "" Vector__XXX
 SG_ APP_parkAssistStatus : 40|2@1+ (1,0) [0|0] "" Vector__XXX
 SG_ APP_useParkDistancesFromAP : 42|1@1+ (1,0) [0|0] "" Vector__XXX

BO_ 846 PARK_pasFrontMiddle: 8 Vector__XXX
 SG_ PARK_frontLeftMiddleRawDistData : 0|8@1+ (1,0) [0|0] "" Vector__XXX
 SG_ PARK_frontMiddleRawDistData : 8|8@1+ (1,0) [0|0] "" Vector__XXX
 SG_ PARK_frontRightMiddleRawDistData : 16|8@1+ (1,0) [0|0] "" Vector__XXX
 SG_ PARK_pasFrontMiddleCounter : 24|4@1+ (1,0) [0|0] "" Vector__XXX
 SG_ PARK_pasFrontMiddleChecksum : 32|8@1+ (1,0) [0|0] "" Vector__XXX

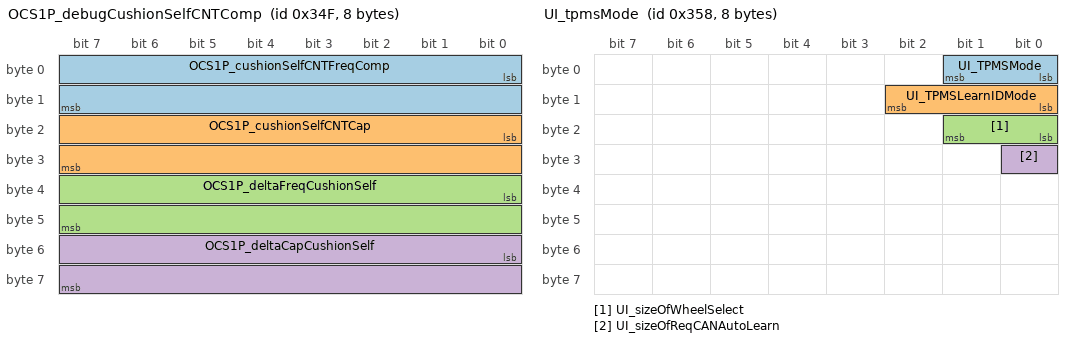
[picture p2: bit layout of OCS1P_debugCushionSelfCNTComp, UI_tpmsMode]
BO_ 847 OCS1P_debugCushionSelfCNTComp: 8 Vector__XXX
 SG_ OCS1P_cushionSelfCNTFreqComp : 0|16@1+ (1,0) [0|0] "" Vector__XXX
 SG_ OCS1P_cushionSelfCNTCap : 16|16@1+ (0.005,0) [0|0] "" Vector__XXX
 SG_ OCS1P_deltaFreqCushionSelf : 32|16@1- (1,0) [0|0] "" Vector__XXX
 SG_ OCS1P_deltaCapCushionSelf : 48|16@1- (0.0025,0) [0|0] "" Vector__XXX

BO_ 848 APS_warningMatrix3: 8 Vector__XXX
 SG_ APS_w193_camWindshieldUnclean : 0|1@1+ (1,0) [0|0] "" Vector__XXX
 SG_ APS_w194_accDriverResumeRqrd : 1|1@1+ (1,0) [0|0] "" Vector__XXX
 SG_ APS_w195_scwUnavailable : 2|1@1+ (1,0) [0|0] "" Vector__XXX
 SG_ APS_w196_stopSignWarning : 3|1@1+ (1,0) [0|0] "" Vector__XXX
 SG_ APS_w197_redLightWarning : 4|1@1+ (1,0) [0|0] "" Vector__XXX
 SG_ APS_w198_tsrUnavailable : 5|1@1+ (1,0) [0|0] "" Vector__XXX
 SG_ APS_w199_apcAbort : 6|1@1+ (1,0) [0|0] "" Vector__XXX
 SG_ APS_w200_lcSlowdown : 7|1@1+ (1,0) [0|0] "" Vector__XXX
 SG_ APS_w201_lcAborting : 8|1@1+ (1,0) [0|0] "" Vector__XXX
 SG_ APS_w202_scwNoisyEnvironment : 9|1@1+ (1,0) [0|0] "" Vector__XXX
 SG_ APS_w203_apcActivation : 10|1@1+ (1,0) [0|0] "" Vector__XXX
 SG_ APS_w204_apcFinalFront : 11|1@1+ (1,0) [0|0] "" Vector__XXX
 SG_ APS_w205_apcFinalRear : 12|1@1+ (1,0) [0|0] "" Vector__XXX
 SG_ APS_w206_autosteerNotEnabled : 13|1@1+ (1,0) [0|0] "" Vector__XXX
 SG_ APS_w207_autosteerUnavailable : 14|1@1+ (1,0) [0|0] "" Vector__XXX
 SG_ APS_w208_rackDetected : 15|1@1+ (1,0) [0|0] "" Vector__XXX
 SG_ APS_w209_autoSummonRequest : 16|1@1+ (1,0) [0|0] "" Vector__XXX
 SG_ APS_w210_camObstrcted : 17|1@1+ (1,0) [0|0] "" Vector__XXX
 SG_ APS_w211_accNoSeatBelt : 18|1@1+ (1,0) [0|0] "" Vector__XXX
 SG_ APS_w212_lcUnavailableStrikeOut : 19|1@1+ (1,0) [0|0] "" Vector__XXX
 SG_ APS_w213_autosteerStruckOut : 20|1@1+ (1,0) [0|0] "" Vector__XXX
 SG_ APS_w214_driverNotIntracting : 21|1@1+ (1,0) [0|0] "" Vector__XXX
 SG_ APS_w215_contDriverNotIntracting : 22|1@1+ (1,0) [0|0] "" Vector__XXX
 SG_ APS_w216_driverOverriding : 23|1@1+ (1,0) [0|0] "" Vector__XXX
 SG_ APS_w217_lcUnavailableSpeeding : 24|1@1+ (1,0) [0|0] "" Vector__XXX
 SG_ APS_w218_lcSpeedExceededLimit : 25|1@1+ (1,0) [0|0] "" Vector__XXX
 SG_ APS_w219_lcTempUnavailableSpeed : 26|1@1+ (1,0) [0|0] "" Vector__XXX
 SG_ APS_w220_lcTempUnavailableRoad : 27|1@1+ (1,0) [0|0] "" Vector__XXX
 SG_ APS_w221_accRadarBlind : 28|1@1+ (1,0) [0|0] "" Vector__XXX
 SG_ APS_w222_accCameraBlind : 29|1@1+ (1,0) [0|0] "" Vector__XXX
 SG_ APS_w223_accObjectInPath : 30|1@1+ (1,0) [0|0] "" Vector__XXX
 SG_ APS_w224_accCameraCalibration : 31|1@1+ (1,0) [0|0] "" Vector__XXX
 SG_ APS_w225_lcDegradedVisSpeedLmt : 32|1@1+ (1,0) [0|0] "" Vector__XXX
 SG_ APS_w226_lcCamCalNeededSpeedLmt : 33|1@1+ (1,0) [0|0] "" Vector__XXX
 SG_ APS_w227_virtualWallBlocked : 34|1@1+ (1,0) [0|0] "" Vector__XXX
 SG_ APS_w228_DEPRECATED : 35|1@1+ (1,0) [0|0] "" Vector__XXX
 SG_ APS_w229_alcUltrasoundDamaged : 36|1@1+ (1,0) [0|0] "" Vector__XXX
 SG_ APS_w230_alcUltrasoundBlocked : 37|1@1+ (1,0) [0|0] "" Vector__XXX
 SG_ APS_w231_idfEvent : 38|1@1+ (1,0) [0|0] "" Vector__XXX
 SG_ APS_w232_laneChangeRequested : 39|1@1+ (1,0) [0|0] "" Vector__XXX
 SG_ APS_w235_a72LoopDetected : 42|1@1+ (1,0) [0|0] "" Vector__XXX
 SG_ APS_w236_canSharedMemError : 43|1@1+ (1,0) [0|0] "" Vector__XXX
 SG_ APS_w237_faultMgrEventDetected : 44|1@1+ (1,0) [0|0] "" Vector__XXX
 SG_ APS_w238_resetReason : 45|1@1+ (1,0) [0|0] "" Vector__XXX
 SG_ APS_w241_ddrInitFailures : 48|1@1+ (1,0) [0|0] "" Vector__XXX
 SG_ APS_w242_tripMBISTFailure : 49|1@1+ (1,0) [0|0] "" Vector__XXX
 SG_ APS_w243_tripHWErrorStatus : 50|1@1+ (1,0) [0|0] "" Vector__XXX
 SG_ APS_w244_gpuHWFaultStatus : 51|1@1+ (1,0) [0|0] "" Vector__XXX
 SG_ APS_w245_eloopRxFromUnexpectedSourceMAC : 52|1@1+ (1,0) [0|0] "" Vector__XXX
 SG_ APS_w246_ethloopSwitchPortLinkDown : 53|1@1+ (1,0) [0|0] "" Vector__XXX
 SG_ APS_w247_ethernetFrameError : 54|1@1+ (1,0) [0|0] "" Vector__XXX
 SG_ APS_w248_ethloopSwitchPoorSqi : 55|1@1+ (1,0) [0|0] "" Vector__XXX
 SG_ APS_w249_ufsFailures : 56|1@1+ (1,0) [0|0] "" Vector__XXX
 SG_ APS_w250_ethloopSwitchMemUsageTooHighPort2 : 57|1@1+ (1,0) [0|0] "" Vector__XXX
 SG_ APS_w251_ethloopSwitchMemUsageTooHighPort3 : 58|1@1+ (1,0) [0|0] "" Vector__XXX
 SG_ APS_w252_ethSwitchPortLinkDown : 59|1@1+ (1,0) [0|0] "" Vector__XXX
 SG_ APS_w253_powerStateTimeout : 60|1@1+ (1,0) [0|0] "" Vector__XXX
 SG_ APS_w254_sleepStateTimeout : 61|1@1+ (1,0) [0|0] "" Vector__XXX
 SG_ APS_w255_bootHealth : 62|1@1+ (1,0) [0|0] "" Vector__XXX

BO_ 849 RCM_info: 8 Vector__XXX
 SG_ RCM_infoIndex M : 0|8@1+ (1,0) [0|0] "" Vector__XXX
 SG_ RCM_infoAlgoCalID m22 : 8|8@1+ (1,0) [0|0] "" Vector__XXX
 SG_ RCM_infoBootUdsProtoVersion m20 : 8|8@1+ (1,0) [0|0] "" Vector__XXX
 SG_ RCM_infoBuildType m10 : 8|8@1+ (1,0) [0|0] "" Vector__XXX
 SG_ RCM_infoPcbaID m11 : 16|8@1+ (1,0) [0|0] "" Vector__XXX
 SG_ RCM_infoAssemblyID m11 : 24|8@1+ (1,0) [0|0] "" Vector__XXX
 SG_ RCM_infoApplicationCRC m13 : 32|32@1+ (1,0) [0|0] "" Vector__XXX
 SG_ RCM_infoBootloaderCRC m20 : 32|32@1+ (1,0) [0|0] "" Vector__XXX
 SG_ RCM_infoUsageID m11 : 32|16@1+ (1,0) [0|0] "" Vector__XXX
 SG_ RCM_infoVariantCRC m22 : 32|32@1+ (1,0) [0|0] "" Vector__XXX
 SG_ RCM_infoComponentID m10 : 48|16@1+ (1,0) [0|0] "" Vector__XXX

BO_ 850 TRCM_info: 8 Vector__XXX
 SG_ TRCM_infoIndex M : 0|8@1+ (1,0) [0|0] "" Vector__XXX
 SG_ TRCM_infoAppCrc m13 : 8|32@1+ (1,0) [0|0] "" Vector__XXX
 SG_ TRCM_infoAppGitHash m17 : 8|56@1+ (1,0) [0|0] "" Vector__XXX
 SG_ TRCM_infoBootGitHash m18 : 8|56@1+ (1,0) [0|0] "" Vector__XXX
 SG_ TRCM_infoBootUdsProtoVersion m20 : 8|8@1+ (1,0) [0|0] "" Vector__XXX
 SG_ TRCM_infoBuildType m10 : 8|8@1+ (1,0) [0|0] "" Vector__XXX
 SG_ TRCM_infoPcbaId m11 : 8|8@1+ (1,0) [0|0] "" Vector__XXX
 SG_ TRCM_infoPlatformType m19 : 8|8@1+ (1,0) [0|0] "" Vector__XXX
 SG_ TRCM_infoAssemblyId m11 : 16|8@1+ (1,0) [0|0] "" Vector__XXX
 SG_ TRCM_infoBuildConfigId m10 : 16|16@1+ (1,0) [0|0] "" Vector__XXX
 SG_ TRCM_infoBootCrc m20 : 24|32@1+ (1,0) [0|0] "" Vector__XXX
 SG_ TRCM_infoUsageId m11 : 24|16@1+ (1,0) [0|0] "" Vector__XXX
 SG_ TRCM_infoHardwareId m10 : 32|16@1+ (1,0) [0|0] "" Vector__XXX
 SG_ TRCM_infoSubUsageId m11 : 40|16@1+ (1,0) [0|0] "" Vector__XXX
 SG_ TRCM_infoComponentId m10 : 48|16@1+ (1,0) [0|0] "" Vector__XXX

BO_ 851 UI_status: 8 Vector__XXX
 SG_ UI_touchActive : 0|1@1+ (1,0) [0|0] "" Vector__XXX
 SG_ UI_audioActive : 1|1@1+ (1,0) [0|0] "" Vector__XXX
 SG_ UI_bluetoothActive : 2|1@1+ (1,0) [0|0] "" Vector__XXX
 SG_ UI_cellActive : 3|1@1+ (1,0) [0|0] "" Vector__XXX
 SG_ UI_displayReady : 4|1@1+ (1,0) [0|0] "" Vector__XXX
 SG_ UI_displayOn : 5|1@1+ (1,0) [0|0] "" Vector__XXX
 SG_ UI_wifiActive : 6|1@1+ (1,0) [0|0] "" Vector__XXX
 SG_ UI_wifiConnected : 7|1@1+ (1,0) [0|0] "" Vector__XXX
 SG_ UI_systemActive : 8|1@1+ (1,0) [0|0] "" Vector__XXX
 SG_ UI_readyForDrive : 9|1@1+ (1,0) [0|0] "" Vector__XXX
 SG_ UI_cellConnected : 10|1@1+ (1,0) [0|0] "" Vector__XXX
 SG_ UI_vpnActive : 11|1@1+ (1,0) [0|0] "" Vector__XXX
 SG_ UI_autopilotTrial : 12|2@1+ (1,0) [0|0] "" Vector__XXX
 SG_ UI_factoryReset : 14|2@1+ (1,0) [0|0] "" Vector__XXX
 SG_ UI_gpsActive : 16|1@1+ (1,0) [0|0] "" Vector__XXX
 SG_ UI_screenshotActive : 17|1@1+ (1,0) [0|0] "" Vector__XXX
 SG_ UI_radioActive : 18|1@1+ (1,0) [0|0] "" Vector__XXX
 SG_ UI_cellNetworkTechnology : 19|4@1+ (1,0) [0|0] "" Vector__XXX
 SG_ UI_cellReceiverPower : 24|8@1+ (1,-128) [0|0] "" Vector__XXX
 SG_ UI_falseTouchCounter : 32|8@1+ (1,0) [0|0] "" Vector__XXX
 SG_ UI_developmentCar : 40|1@1+ (1,0) [0|0] "" Vector__XXX
 SG_ UI_cameraActive : 41|1@1+ (1,0) [0|0] "" Vector__XXX
 SG_ UI_cellSignalBars : 42|3@1+ (1,0) [0|0] "" Vector__XXX
 SG_ UI_trailerModeTelltale : 45|2@1+ (1,0) [0|0] "" Vector__XXX
 SG_ UI_pcbTemperature : 48|8@1- (1,40) [0|0] "" Vector__XXX
 SG_ UI_cpuTemperature : 56|8@1- (1,40) [0|0] "" Vector__XXX

BO_ 852 UI_uiHealthStatus: 8 Vector__XXX
 SG_ UI_centerDisplayRunning : 0|1@1+ (1,0) [0|0] "" Vector__XXX
 SG_ UI_centerDisplaySM : 1|3@1+ (1,0) [0|0] "" Vector__XXX
 SG_ UI_centerDisplayPowerOn : 4|1@1+ (1,0) [0|0] "" Vector__XXX
 SG_ UI_centerDisplayCrtcOk : 5|1@1+ (1,0) [0|0] "" Vector__XXX
 SG_ UI_centerDisplayHardwareOk : 6|1@1+ (1,0) [0|0] "" Vector__XXX
 SG_ UI_centerDisplayWindowManagerOk : 7|1@1+ (1,0) [0|0] "" Vector__XXX
 SG_ UI_centerDisplayCompositorOk : 8|1@1+ (1,0) [0|0] "" Vector__XXX
 SG_ UI_apVisualizationOk : 9|1@1+ (1,0) [0|0] "" Vector__XXX
 SG_ UI_autonomyCenterDispStatus : 10|2@1+ (1,0) [0|0] "" Vector__XXX
 SG_ UI_autonomyRearDispStatus : 12|2@1+ (1,0) [0|0] "" Vector__XXX
 SG_ UI_autonomyConnectivityStatus : 14|2@1+ (1,0) [0|0] "" Vector__XXX
 SG_ UI_autonomyConnectivtyHWOk : 16|1@1+ (1,0) [0|0] "" Vector__XXX
 SG_ UI_autonomyQtCarStatus : 17|2@1+ (1,0) [0|0] "" Vector__XXX
 SG_ UI_autonomyQtCarRearStatus : 19|2@1+ (1,0) [0|0] "" Vector__XXX
 SG_ UI_autonomyDASServerStatus : 21|2@1+ (1,0) [0|0] "" Vector__XXX
 SG_ UI_rearDisplayRunning : 23|1@1+ (1,0) [0|0] "" Vector__XXX
 SG_ UI_rearDisplayPowerOn : 24|1@1+ (1,0) [0|0] "" Vector__XXX
 SG_ UI_rearDisplaySM : 25|3@1+ (1,0) [0|0] "" Vector__XXX
 SG_ UI_rearDisplayCrtcOk : 28|1@1+ (1,0) [0|0] "" Vector__XXX
 SG_ UI_rearDisplayHardwareOk : 29|1@1+ (1,0) [0|0] "" Vector__XXX
 SG_ UI_rearDisplayWindowManagerOk : 30|1@1+ (1,0) [0|0] "" Vector__XXX
 SG_ UI_rearDisplayCompositorOk : 31|1@1+ (1,0) [0|0] "" Vector__XXX

BO_ 856 UI_tpmsMode: 8 Vector__XXX
 SG_ UI_TPMSMode : 0|2@1+ (1,0) [0|0] "" Vector__XXX
 SG_ UI_TPMSLearnIDMode : 8|3@1+ (1,0) [0|0] "" Vector__XXX
 SG_ UI_sizeOfWheelSelect : 16|2@1+ (1,0) [0|0] "" Vector__XXX
 SG_ UI_sizeOfReqCANAutoLearn : 24|1@1+ (1,0) [0|0] "" Vector__XXX

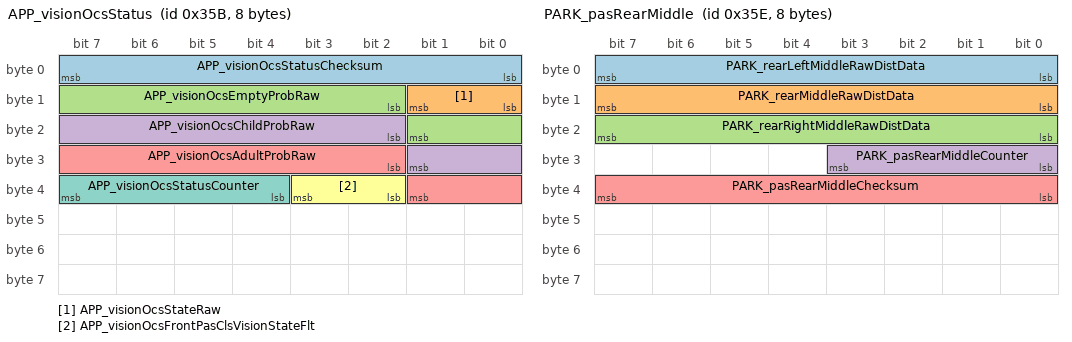
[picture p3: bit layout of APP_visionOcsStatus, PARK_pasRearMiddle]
BO_ 859 APP_visionOcsStatus: 8 Vector__XXX
 SG_ APP_visionOcsStatusChecksum : 0|8@1+ (1,0) [0|0] "" Vector__XXX
 SG_ APP_visionOcsStateRaw : 8|2@1+ (1,0) [0|0] "" Vector__XXX
 SG_ APP_visionOcsEmptyProbRaw : 10|8@1+ (0.004,0) [0|0] "" Vector__XXX
 SG_ APP_visionOcsChildProbRaw : 18|8@1+ (0.004,0) [0|0] "" Vector__XXX
 SG_ APP_visionOcsAdultProbRaw : 26|8@1+ (0.004,0) [0|0] "" Vector__XXX
 SG_ APP_visionOcsFrontPasClsVisionStateFlt : 34|2@1+ (1,0) [0|0] "" Vector__XXX
 SG_ APP_visionOcsStatusCounter : 36|4@1+ (1,0) [0|0] "" Vector__XXX

BO_ 861 IBST_alertMatrix: 8 Vector__XXX
 SG_ IBST_matrixIndex M : 0|4@1+ (1,0) [0|0] "" Vector__XXX
 SG_ IBST_a001_microSupplyError m0 : 4|1@1+ (1,0) [0|0] "" Vector__XXX
 SG_ IBST_a061_AswSystemTimeOut m1 : 4|1@1+ (1,0) [0|0] "" Vector__XXX
 SG_ IBST_a121_RPSVectorRangeLow m2 : 4|1@1+ (1,0) [0|0] "" Vector__XXX
 SG_ IBST_a181_DIchassisControlDLC m3 : 4|1@1+ (1,0) [0|0] "" Vector__XXX
 SG_ IBST_a002_HWBISTError m0 : 5|1@1+ (1,0) [0|0] "" Vector__XXX
 SG_ IBST_a062_MICB6TransferError m1 : 5|1@1+ (1,0) [0|0] "" Vector__XXX
 SG_ IBST_a122_RPSVectorOscillating m2 : 5|1@1+ (1,0) [0|0] "" Vector__XXX
 SG_ IBST_a182_DIchassisControlTimeout m3 : 5|1@1+ (1,0) [0|0] "" Vector__XXX
 SG_ IBST_a003_RAMFault m0 : 6|1@1+ (1,0) [0|0] "" Vector__XXX
 SG_ IBST_a063_tempSens2ShortToSupply m1 : 6|1@1+ (1,0) [0|0] "" Vector__XXX
 SG_ IBST_a123_bridgeDriverUnavail m2 : 6|1@1+ (1,0) [0|0] "" Vector__XXX
 SG_ IBST_a183_DIchassisControlChecksum m3 : 6|1@1+ (1,0) [0|0] "" Vector__XXX
 SG_ IBST_a004_flashFault m0 : 7|1@1+ (1,0) [0|0] "" Vector__XXX
 SG_ IBST_a064_tempSens1ShortToGround m1 : 7|1@1+ (1,0) [0|0] "" Vector__XXX
 SG_ IBST_a124_OBDCurrent1OORHigh m2 : 7|1@1+ (1,0) [0|0] "" Vector__XXX
 SG_ IBST_a184_DIchassisControlCounter m3 : 7|1@1+ (1,0) [0|0] "" Vector__XXX
 SG_ IBST_a005_microSafetyFault m0 : 8|1@1+ (1,0) [0|0] "" Vector__XXX
 SG_ IBST_a065_tempSens2ShortToGround m1 : 8|1@1+ (1,0) [0|0] "" Vector__XXX
 SG_ IBST_a125_OBDCurrent2OORHigh m2 : 8|1@1+ (1,0) [0|0] "" Vector__XXX
 SG_ IBST_a185_rightBusOff m3 : 8|1@1+ (1,0) [0|0] "" Vector__XXX
 SG_ IBST_a006_microSafetyLogicFault m0 : 9|1@1+ (1,0) [0|0] "" Vector__XXX
 SG_ IBST_a066_tempSens1ShortToSupply m1 : 9|1@1+ (1,0) [0|0] "" Vector__XXX
 SG_ IBST_a126_OBDCurrent1OORLow m2 : 9|1@1+ (1,0) [0|0] "" Vector__XXX
 SG_ IBST_a186_rightBusPassive m3 : 9|1@1+ (1,0) [0|0] "" Vector__XXX
 SG_ IBST_a007_RBCPUException m0 : 10|1@1+ (1,0) [0|0] "" Vector__XXX
 SG_ IBST_a067_tempSensImplausVoltage m1 : 10|1@1+ (1,0) [0|0] "" Vector__XXX
 SG_ IBST_a127_OBDCurrent2OORLow m2 : 10|1@1+ (1,0) [0|0] "" Vector__XXX
 SG_ IBST_a187_brakeBusOff m3 : 10|1@1+ (1,0) [0|0] "" Vector__XXX
 SG_ IBST_a008_stackOverUnderFlow m0 : 11|1@1+ (1,0) [0|0] "" Vector__XXX
 SG_ IBST_a068_chargePumpUndervoltage m1 : 11|1@1+ (1,0) [0|0] "" Vector__XXX
 SG_ IBST_a128_BLMMuxerTimeoutError m2 : 11|1@1+ (1,0) [0|0] "" Vector__XXX
 SG_ IBST_a188_brakeBusPassive m3 : 11|1@1+ (1,0) [0|0] "" Vector__XXX
 SG_ IBST_a009_systemErrorHook m0 : 12|1@1+ (1,0) [0|0] "" Vector__XXX
 SG_ IBST_a069_greasingRoutineFault m1 : 12|1@1+ (1,0) [0|0] "" Vector__XXX
 SG_ IBST_a129_loadDumpOnFSLTest m2 : 12|1@1+ (1,0) [0|0] "" Vector__XXX
 SG_ IBST_a189_rightVCLVPowerStateTimeout m3 : 12|1@1+ (1,0) [0|0] "" Vector__XXX
 SG_ IBST_a010_OSErrorHook m0 : 13|1@1+ (1,0) [0|0] "" Vector__XXX
 SG_ IBST_a070_notShutDownNvMWrite m1 : 13|1@1+ (1,0) [0|0] "" Vector__XXX
 SG_ IBST_a130_DTSFunctionalRangeLow m2 : 13|1@1+ (1,0) [0|0] "" Vector__XXX
 SG_ IBST_a190_rightVCLVPowerStateDLC m3 : 13|1@1+ (1,0) [0|0] "" Vector__XXX
 SG_ IBST_a011_systemTaskOverRun m0 : 14|1@1+ (1,0) [0|0] "" Vector__XXX
 SG_ IBST_a071_notShutDownNvMRead m1 : 14|1@1+ (1,0) [0|0] "" Vector__XXX
 SG_ IBST_a131_DTSFunctionalRangeHigh m2 : 14|1@1+ (1,0) [0|0] "" Vector__XXX
 SG_ IBST_a191_rightVCLVPowerStateChecksum m3 : 14|1@1+ (1,0) [0|0] "" Vector__XXX
 SG_ IBST_a012_OSTaskSchemeError m0 : 15|1@1+ (1,0) [0|0] "" Vector__XXX
 SG_ IBST_a072_notShutDownRight m1 : 15|1@1+ (1,0) [0|0] "" Vector__XXX
 SG_ IBST_a132_DTSPlausiCheck1vs2 m2 : 15|1@1+ (1,0) [0|0] "" Vector__XXX
 SG_ IBST_a192_rightVCLVPowerStateCounter m3 : 15|1@1+ (1,0) [0|0] "" Vector__XXX
 SG_ IBST_a013_systemTaskJitter m0 : 16|1@1+ (1,0) [0|0] "" Vector__XXX
 SG_ IBST_a073_jumpInAdjustNvMRead m1 : 16|1@1+ (1,0) [0|0] "" Vector__XXX
 SG_ IBST_a133_DTSOffsetTooLow m2 : 16|1@1+ (1,0) [0|0] "" Vector__XXX
 SG_ IBST_a193_leftVCLVPowerStateTimeout m3 : 16|1@1+ (1,0) [0|0] "" Vector__XXX
 SG_ IBST_a014_DMATransferError m0 : 17|1@1+ (1,0) [0|0] "" Vector__XXX
 SG_ IBST_a074_FindIdleDataNvMWrite m1 : 17|1@1+ (1,0) [0|0] "" Vector__XXX
 SG_ IBST_a134_DTSOffsetTooHigh m2 : 17|1@1+ (1,0) [0|0] "" Vector__XXX
 SG_ IBST_a194_leftVCLVPowerStateChecksum m3 : 17|1@1+ (1,0) [0|0] "" Vector__XXX
 SG_ IBST_a015_asicOscillatorError m0 : 18|1@1+ (1,0) [0|0] "" Vector__XXX
 SG_ IBST_a075_FindIdleRoutineFault m1 : 18|1@1+ (1,0) [0|0] "" Vector__XXX
 SG_ IBST_a135_ESPparty1DLC m2 : 18|1@1+ (1,0) [0|0] "" Vector__XXX
 SG_ IBST_a195_leftVCLVPowerStateDLC m3 : 18|1@1+ (1,0) [0|0] "" Vector__XXX
 SG_ IBST_a016_RBBLMShaftShiftError m0 : 19|1@1+ (1,0) [0|0] "" Vector__XXX
 SG_ IBST_a076_masterCylLengthRead m1 : 19|1@1+ (1,0) [0|0] "" Vector__XXX
 SG_ IBST_a136_ESPparty1Timeout m2 : 19|1@1+ (1,0) [0|0] "" Vector__XXX
 SG_ IBST_a196_leftVCLVPowerStateCounter m3 : 19|1@1+ (1,0) [0|0] "" Vector__XXX
 SG_ IBST_a017_assertionFault m0 : 20|1@1+ (1,0) [0|0] "" Vector__XXX
 SG_ IBST_a077_runOutMotorSaturated m1 : 20|1@1+ (1,0) [0|0] "" Vector__XXX
 SG_ IBST_a137_ESPparty1Checksum m2 : 20|1@1+ (1,0) [0|0] "" Vector__XXX
 SG_ IBST_a197_brakeLatencyReductionActive m3 : 20|1@1+ (1,0) [0|0] "" Vector__XXX
 SG_ IBST_a018_unsupportedHW m0 : 21|1@1+ (1,0) [0|0] "" Vector__XXX
 SG_ IBST_a078_wearOffsetCompNVMRead m1 : 21|1@1+ (1,0) [0|0] "" Vector__XXX
 SG_ IBST_a138_ESPparty1Counter m2 : 21|1@1+ (1,0) [0|0] "" Vector__XXX
 SG_ IBST_a198_aesActive m3 : 21|1@1+ (1,0) [0|0] "" Vector__XXX
 SG_ IBST_a019_supplyASICInitFault m0 : 22|1@1+ (1,0) [0|0] "" Vector__XXX
 SG_ IBST_a079_motorTempHighLevel1 m1 : 22|1@1+ (1,0) [0|0] "" Vector__XXX
 SG_ IBST_a139_ESPparty2DLC m2 : 22|1@1+ (1,0) [0|0] "" Vector__XXX
 SG_ IBST_a199_undefinedAlertDetected m3 : 22|1@1+ (1,0) [0|0] "" Vector__XXX
 SG_ IBST_a020_VPREU5VOutOfRange m0 : 23|1@1+ (1,0) [0|0] "" Vector__XXX
 SG_ IBST_a080_motorTempHighLevel2 m1 : 23|1@1+ (1,0) [0|0] "" Vector__XXX
 SG_ IBST_a140_ESPparty2Timeout m2 : 23|1@1+ (1,0) [0|0] "" Vector__XXX
 SG_ IBST_a200_aesFault m3 : 23|1@1+ (1,0) [0|0] "" Vector__XXX
 SG_ IBST_a021_IREFOutOfRange m0 : 24|1@1+ (1,0) [0|0] "" Vector__XXX
 SG_ IBST_a081_travelDeviation m1 : 24|1@1+ (1,0) [0|0] "" Vector__XXX
 SG_ IBST_a141_ESPparty2Checksum m2 : 24|1@1+ (1,0) [0|0] "" Vector__XXX
 SG_ IBST_a201_EGGREAR1wheelSpeedsRearTimeOut m3 : 24|1@1+ (1,0) [0|0] "" Vector__XXX
 SG_ IBST_a022_U5VTestFault m0 : 25|1@1+ (1,0) [0|0] "" Vector__XXX
 SG_ IBST_a082_motorSpeedDeviation m1 : 25|1@1+ (1,0) [0|0] "" Vector__XXX
 SG_ IBST_a142_ESPparty2Counter m2 : 25|1@1+ (1,0) [0|0] "" Vector__XXX
 SG_ IBST_a202_EGGREAR1wheelSpeedsRearChecksum m3 : 25|1@1+ (1,0) [0|0] "" Vector__XXX
 SG_ IBST_a023_U5VOutOfRange m0 : 26|1@1+ (1,0) [0|0] "" Vector__XXX
 SG_ IBST_a083_spindlePositionTooHigh m1 : 26|1@1+ (1,0) [0|0] "" Vector__XXX
 SG_ IBST_a143_ESPparty3DLC m2 : 26|1@1+ (1,0) [0|0] "" Vector__XXX
 SG_ IBST_a203_EGGREAR1wheelSpeedsRearDLC m3 : 26|1@1+ (1,0) [0|0] "" Vector__XXX
 SG_ IBST_a024_chargePumpFault m0 : 27|1@1+ (1,0) [0|0] "" Vector__XXX
 SG_ IBST_a084_CANTransceiverHWFault m1 : 27|1@1+ (1,0) [0|0] "" Vector__XXX
 SG_ IBST_a144_ESPparty3Timeout m2 : 27|1@1+ (1,0) [0|0] "" Vector__XXX
 SG_ IBST_a204_EGGREAR1wheelSpeedsRearCounter m3 : 27|1@1+ (1,0) [0|0] "" Vector__XXX
 SG_ IBST_a025_ecuClockTestFault m0 : 28|1@1+ (1,0) [0|0] "" Vector__XXX
 SG_ IBST_a085_supplyUndervoltageLvl3 m1 : 28|1@1+ (1,0) [0|0] "" Vector__XXX
 SG_ IBST_a145_ESPparty3Checksum m2 : 28|1@1+ (1,0) [0|0] "" Vector__XXX
 SG_ IBST_a205_EGGRIGHT1wheelSpeedsFrontTimeOut m3 : 28|1@1+ (1,0) [0|0] "" Vector__XXX
 SG_ IBST_a026_ecuBistCmdTestFault m0 : 29|1@1+ (1,0) [0|0] "" Vector__XXX
 SG_ IBST_a086_supplyOvervoltageLvl3 m1 : 29|1@1+ (1,0) [0|0] "" Vector__XXX
 SG_ IBST_a146_ESPparty3Counter m2 : 29|1@1+ (1,0) [0|0] "" Vector__XXX
 SG_ IBST_a206_EGGRIGHT1wheelSpeedsFrontChecksum m3 : 29|1@1+ (1,0) [0|0] "" Vector__XXX
 SG_ IBST_a027_ecuFastWdTestFault m0 : 30|1@1+ (1,0) [0|0] "" Vector__XXX
 SG_ IBST_a087_rotorSinOutOfRangeLow m1 : 30|1@1+ (1,0) [0|0] "" Vector__XXX
 SG_ IBST_a147_PSCMotorSizeReadFault m2 : 30|1@1+ (1,0) [0|0] "" Vector__XXX
 SG_ IBST_a207_EGGRIGHT1wheelSpeedsFrontDLC m3 : 30|1@1+ (1,0) [0|0] "" Vector__XXX
 SG_ IBST_a028_ecuBistFaultCtrFault m0 : 31|1@1+ (1,0) [0|0] "" Vector__XXX
 SG_ IBST_a088_rotorCosOutOfRangeLow m1 : 31|1@1+ (1,0) [0|0] "" Vector__XXX
 SG_ IBST_a148_MLIGainMechReadFault m2 : 31|1@1+ (1,0) [0|0] "" Vector__XXX
 SG_ IBST_a208_EGGRIGHT1wheelSpeedsFrontCounter m3 : 31|1@1+ (1,0) [0|0] "" Vector__XXX
 SG_ IBST_a029_ecuErrpinCounterFault m0 : 32|1@1+ (1,0) [0|0] "" Vector__XXX
 SG_ IBST_a089_rotorSinOutOfRangeHigh m1 : 32|1@1+ (1,0) [0|0] "" Vector__XXX
 SG_ IBST_a149_MLITMCAreaReadFault m2 : 32|1@1+ (1,0) [0|0] "" Vector__XXX
 SG_ IBST_a209_reducedBrakePowerActive m3 : 32|1@1+ (1,0) [0|0] "" Vector__XXX
 SG_ IBST_a030_ecuEnableElLowFault m0 : 33|1@1+ (1,0) [0|0] "" Vector__XXX
 SG_ IBST_a090_rotorCosOutOfRangeHigh m1 : 33|1@1+ (1,0) [0|0] "" Vector__XXX
 SG_ IBST_a150_motorTestFault m2 : 33|1@1+ (1,0) [0|0] "" Vector__XXX
 SG_ IBST_a210_reducedBrakePowerNotAvailable m3 : 33|1@1+ (1,0) [0|0] "" Vector__XXX
 SG_ IBST_a031_decoupleBitTestFault m0 : 34|1@1+ (1,0) [0|0] "" Vector__XXX
 SG_ IBST_a091_SMMOneRequestsInit m1 : 34|1@1+ (1,0) [0|0] "" Vector__XXX
 SG_ IBST_a151_PSCGearRatioReadFault m2 : 34|1@1+ (1,0) [0|0] "" Vector__XXX
 SG_ IBST_a211_DETReportError m3 : 34|1@1+ (1,0) [0|0] "" Vector__XXX
 SG_ IBST_a032_ecuEnableElHighFault m0 : 35|1@1+ (1,0) [0|0] "" Vector__XXX
 SG_ IBST_a092_systemStartTimeOut m1 : 35|1@1+ (1,0) [0|0] "" Vector__XXX
 SG_ IBST_a152_PSCVoltageImplausible m2 : 35|1@1+ (1,0) [0|0] "" Vector__XXX
 SG_ IBST_a212_infoFailureWrongCUBASHandlingDetected m3 : 35|1@1+ (1,0) [0|0] "" Vector__XXX
 SG_ IBST_a033_ecuWdStartuptestFault m0 : 36|1@1+ (1,0) [0|0] "" Vector__XXX
 SG_ IBST_a093_UEXSOvertemperature m1 : 36|1@1+ (1,0) [0|0] "" Vector__XXX
 SG_ IBST_a153_unused m2 : 36|1@1+ (1,0) [0|0] "" Vector__XXX
 SG_ IBST_a213_PDURouterinitializationFailed m3 : 36|1@1+ (1,0) [0|0] "" Vector__XXX
 SG_ IBST_a034_ecuEnableHyHighFault m0 : 37|1@1+ (1,0) [0|0] "" Vector__XXX
 SG_ IBST_a094_XPASSEchoTimeDeviation m1 : 37|1@1+ (1,0) [0|0] "" Vector__XXX
 SG_ IBST_a154_unused m2 : 37|1@1+ (1,0) [0|0] "" Vector__XXX
 SG_ IBST_a214_LossOfPDUInstanceDetected m3 : 37|1@1+ (1,0) [0|0] "" Vector__XXX
 SG_ IBST_a035_ecuEnableHyLowFault m0 : 38|1@1+ (1,0) [0|0] "" Vector__XXX
 SG_ IBST_a095_XPASSTimeOut m1 : 38|1@1+ (1,0) [0|0] "" Vector__XXX
 SG_ IBST_a155_supplyUndervoltageLvl1 m2 : 38|1@1+ (1,0) [0|0] "" Vector__XXX
 SG_ IBST_a215_UnsupportedSeriesHWDetected m3 : 38|1@1+ (1,0) [0|0] "" Vector__XXX
 SG_ IBST_a036_MRGPathTestFault m0 : 39|1@1+ (1,0) [0|0] "" Vector__XXX
 SG_ IBST_a096_bridgeDriverMonError m1 : 39|1@1+ (1,0) [0|0] "" Vector__XXX
 SG_ IBST_a156_supplyOvervoltageLvl1 m2 : 39|1@1+ (1,0) [0|0] "" Vector__XXX
 SG_ IBST_a216_AsicMalfunctionDetected m3 : 39|1@1+ (1,0) [0|0] "" Vector__XXX
 SG_ IBST_a037_ecuWdSContinuousError m0 : 40|1@1+ (1,0) [0|0] "" Vector__XXX
 SG_ IBST_a097_bridgeDriverError m1 : 40|1@1+ (1,0) [0|0] "" Vector__XXX
 SG_ IBST_a157_masterCylPressInvalid m2 : 40|1@1+ (1,0) [0|0] "" Vector__XXX
 SG_ IBST_a217_AsicTrimmingNotCompleted m3 : 40|1@1+ (1,0) [0|0] "" Vector__XXX
 SG_ IBST_a038_ecuEnContinuousError m0 : 41|1@1+ (1,0) [0|0] "" Vector__XXX
 SG_ IBST_a098_bridgeShortedPhase m1 : 41|1@1+ (1,0) [0|0] "" Vector__XXX
 SG_ IBST_a158_DTSOffsHighSuspicious m2 : 41|1@1+ (1,0) [0|0] "" Vector__XXX
 SG_ IBST_a218_uCSafetyNotificationGRAM m3 : 41|1@1+ (1,0) [0|0] "" Vector__XXX
 SG_ IBST_a039_GTMRefFrequencyError m0 : 42|1@1+ (1,0) [0|0] "" Vector__XXX
 SG_ IBST_a099_bridgeSwitchInitError m1 : 42|1@1+ (1,0) [0|0] "" Vector__XXX
 SG_ IBST_a159_FindIdleNvMReadError m2 : 42|1@1+ (1,0) [0|0] "" Vector__XXX
 SG_ IBST_a219_uCSafetyNotification m3 : 42|1@1+ (1,0) [0|0] "" Vector__XXX
 SG_ IBST_a040_GTMTbuMonError m0 : 43|1@1+ (1,0) [0|0] "" Vector__XXX
 SG_ IBST_a100_current2OffsetHigh m1 : 43|1@1+ (1,0) [0|0] "" Vector__XXX
 SG_ IBST_a160_DTSIDTimeOut m2 : 43|1@1+ (1,0) [0|0] "" Vector__XXX
 SG_ IBST_a220_ASICOvercurrentOnGPIO250_2 m3 : 43|1@1+ (1,0) [0|0] "" Vector__XXX
 SG_ IBST_a041_micAsicClkInError m0 : 44|1@1+ (1,0) [0|0] "" Vector__XXX
 SG_ IBST_a101_current2OffsetLow m1 : 44|1@1+ (1,0) [0|0] "" Vector__XXX
 SG_ IBST_a161_powerPackMismatch m2 : 44|1@1+ (1,0) [0|0] "" Vector__XXX
 SG_ IBST_a221_ASICOvercurrentOnGPIO250_1 m3 : 44|1@1+ (1,0) [0|0] "" Vector__XXX
 SG_ IBST_a042_micAsicInitTestError m0 : 45|1@1+ (1,0) [0|0] "" Vector__XXX
 SG_ IBST_a102_current1OffsetHigh m1 : 45|1@1+ (1,0) [0|0] "" Vector__XXX
 SG_ IBST_a162_idlePosNotDetected m2 : 45|1@1+ (1,0) [0|0] "" Vector__XXX
 SG_ IBST_a222_ASICOvercurrentOnGPIO50_4 m3 : 45|1@1+ (1,0) [0|0] "" Vector__XXX
 SG_ IBST_a043_micSpiTransferError m0 : 46|1@1+ (1,0) [0|0] "" Vector__XXX
 SG_ IBST_a103_current1OffsetLow m1 : 46|1@1+ (1,0) [0|0] "" Vector__XXX
 SG_ IBST_a163_ESPpEstMaxInvalid m2 : 46|1@1+ (1,0) [0|0] "" Vector__XXX
 SG_ IBST_a223_ASICOvercurrentOnGPIO50_3 m3 : 46|1@1+ (1,0) [0|0] "" Vector__XXX
 SG_ IBST_a044_NvMEepromWIP m0 : 47|1@1+ (1,0) [0|0] "" Vector__XXX
 SG_ IBST_a104_bridgeDriverShort m1 : 47|1@1+ (1,0) [0|0] "" Vector__XXX
 SG_ IBST_a164_ESPVehicleSpeedInvalid m2 : 47|1@1+ (1,0) [0|0] "" Vector__XXX
 SG_ IBST_a224_ASICOvercurrentOnGPIO50_2 m3 : 47|1@1+ (1,0) [0|0] "" Vector__XXX
 SG_ IBST_a045_WdhAsicWdErrorCntStuck m0 : 48|1@1+ (1,0) [0|0] "" Vector__XXX
 SG_ IBST_a105_LiPSUndervoltage m1 : 48|1@1+ (1,0) [0|0] "" Vector__XXX
 SG_ IBST_a165_ESPpForceBlendInvalid m2 : 48|1@1+ (1,0) [0|0] "" Vector__XXX
 SG_ IBST_a225_ASICOvercurrentOnGPIO50_1 m3 : 48|1@1+ (1,0) [0|0] "" Vector__XXX
 SG_ IBST_a046_WdhAsicWdErrorCntLimit m0 : 49|1@1+ (1,0) [0|0] "" Vector__XXX
 SG_ IBST_a106_LiPS5VSupply m1 : 49|1@1+ (1,0) [0|0] "" Vector__XXX
 SG_ IBST_a166_ESPpMcVirtualInvalid m2 : 49|1@1+ (1,0) [0|0] "" Vector__XXX
 SG_ IBST_a226_ASICOvercurrentOnWRHS m3 : 49|1@1+ (1,0) [0|0] "" Vector__XXX
 SG_ IBST_a047_WdhAsicWdCmdMissing m0 : 50|1@1+ (1,0) [0|0] "" Vector__XXX
 SG_ IBST_a107_LiPS2PwmLineHigh m1 : 50|1@1+ (1,0) [0|0] "" Vector__XXX
 SG_ IBST_a167_ESPqTargetExterInvalid m2 : 50|1@1+ (1,0) [0|0] "" Vector__XXX
 SG_ IBST_a227_wakeRequestMismatchDetected m3 : 50|1@1+ (1,0) [0|0] "" Vector__XXX
 SG_ IBST_a048_WdhSwBistConCnt m0 : 51|1@1+ (1,0) [0|0] "" Vector__XXX
 SG_ IBST_a108_LiPS2PwmLineLow m1 : 51|1@1+ (1,0) [0|0] "" Vector__XXX
 SG_ IBST_a168_CANOvervoltage m2 : 51|1@1+ (1,0) [0|0] "" Vector__XXX
 SG_ IBST_a228_BlockedPedalDetectedDuringHAD m3 : 51|1@1+ (1,0) [0|0] "" Vector__XXX
 SG_ IBST_a049_WdhTaskMonConCnt m0 : 52|1@1+ (1,0) [0|0] "" Vector__XXX
 SG_ IBST_a109_LiPS2PwmTransmission m1 : 52|1@1+ (1,0) [0|0] "" Vector__XXX
 SG_ IBST_a169_CANUndervoltage m2 : 52|1@1+ (1,0) [0|0] "" Vector__XXX
 SG_ IBST_a229_BlockedPedalDetected m3 : 52|1@1+ (1,0) [0|0] "" Vector__XXX
 SG_ IBST_a050_VPreExternalFeeding m0 : 53|1@1+ (1,0) [0|0] "" Vector__XXX
 SG_ IBST_a110_LiPS1SentLineHigh m1 : 53|1@1+ (1,0) [0|0] "" Vector__XXX
 SG_ IBST_a170_LVPowerStateTimeout m2 : 53|1@1+ (1,0) [0|0] "" Vector__XXX
 SG_ IBST_a230_DTS2FunctionalRangeLow m3 : 53|1@1+ (1,0) [0|0] "" Vector__XXX
 SG_ IBST_a051_ecuBandgap m0 : 54|1@1+ (1,0) [0|0] "" Vector__XXX
 SG_ IBST_a111_LiPS1SentLineLow m1 : 54|1@1+ (1,0) [0|0] "" Vector__XXX
 SG_ IBST_a171_LVPowerStateChecksum m2 : 54|1@1+ (1,0) [0|0] "" Vector__XXX
 SG_ IBST_a231_DTS2FunctionalRangeLow m3 : 54|1@1+ (1,0) [0|0] "" Vector__XXX
 SG_ IBST_a052_AdcPinTest m0 : 55|1@1+ (1,0) [0|0] "" Vector__XXX
 SG_ IBST_a112_LiPS1SentTransmission m1 : 55|1@1+ (1,0) [0|0] "" Vector__XXX
 SG_ IBST_a172_LVPowerStateDLC m2 : 55|1@1+ (1,0) [0|0] "" Vector__XXX
 SG_ IBST_a232_PostAssemblyRoutineFailed m3 : 55|1@1+ (1,0) [0|0] "" Vector__XXX
 SG_ IBST_a053_AdcSelftestC5P m0 : 56|1@1+ (1,0) [0|0] "" Vector__XXX
 SG_ IBST_a113_LiPS1SentSensor m1 : 56|1@1+ (1,0) [0|0] "" Vector__XXX
 SG_ IBST_a173_LVPowerStateCounter m2 : 56|1@1+ (1,0) [0|0] "" Vector__XXX
 SG_ IBST_a233_ReferenceRunAbortByECUReset m3 : 56|1@1+ (1,0) [0|0] "" Vector__XXX
 SG_ IBST_a054_AdcPeripheralFault m0 : 57|1@1+ (1,0) [0|0] "" Vector__XXX
 SG_ IBST_a114_partyBusOff m1 : 57|1@1+ (1,0) [0|0] "" Vector__XXX
 SG_ IBST_a174_LVOffStateInvalid m2 : 57|1@1+ (1,0) [0|0] "" Vector__XXX
 SG_ IBST_a234_LiPSOutOfRangeHigh m3 : 57|1@1+ (1,0) [0|0] "" Vector__XXX
 SG_ IBST_a055_UB6SupplyPathFault m0 : 58|1@1+ (1,0) [0|0] "" Vector__XXX
 SG_ IBST_a115_chassisBusOff m1 : 58|1@1+ (1,0) [0|0] "" Vector__XXX
 SG_ IBST_a175_LVGoingDownInvalid m2 : 58|1@1+ (1,0) [0|0] "" Vector__XXX
 SG_ IBST_a235_LiPSOutOfRangeLow m3 : 58|1@1+ (1,0) [0|0] "" Vector__XXX
 SG_ IBST_a056_UB6PlausiMonFault m0 : 59|1@1+ (1,0) [0|0] "" Vector__XXX
 SG_ IBST_a116_supplyUndervoltageLvl2 m1 : 59|1@1+ (1,0) [0|0] "" Vector__XXX
 SG_ IBST_a176_blockedPedalDetected m2 : 59|1@1+ (1,0) [0|0] "" Vector__XXX
 SG_ IBST_a057_microRegisterFault m0 : 60|1@1+ (1,0) [0|0] "" Vector__XXX
 SG_ IBST_a117_supplyOvervoltageLvl2 m1 : 60|1@1+ (1,0) [0|0] "" Vector__XXX
 SG_ IBST_a177_EPBLsystemStatusMIA m2 : 60|1@1+ (1,0) [0|0] "" Vector__XXX
 SG_ IBST_a058_NvMWriteCycleExceed m0 : 61|1@1+ (1,0) [0|0] "" Vector__XXX
 SG_ IBST_a118_RPSNvMReadFault m1 : 61|1@1+ (1,0) [0|0] "" Vector__XXX
 SG_ IBST_a178_EPBRsystemStatusMIA m2 : 61|1@1+ (1,0) [0|0] "" Vector__XXX
 SG_ IBST_a059_NvMEepromSize m0 : 62|1@1+ (1,0) [0|0] "" Vector__XXX
 SG_ IBST_a119_RPSWrongCalibData m1 : 62|1@1+ (1,0) [0|0] "" Vector__XXX
 SG_ IBST_a179_VCLEFTepbmStatusMIA m2 : 62|1@1+ (1,0) [0|0] "" Vector__XXX
 SG_ IBST_a060_NvMMigrationFault m0 : 63|1@1+ (1,0) [0|0] "" Vector__XXX
 SG_ IBST_a120_RPSVectorRangeHigh m1 : 63|1@1+ (1,0) [0|0] "" Vector__XXX
 SG_ IBST_a180_VCRIGHTepbmStatusMIA m2 : 63|1@1+ (1,0) [0|0] "" Vector__XXX

BO_ 862 PARK_pasRearMiddle: 8 Vector__XXX
 SG_ PARK_rearLeftMiddleRawDistData : 0|8@1+ (1,0) [0|0] "" Vector__XXX
 SG_ PARK_rearMiddleRawDistData : 8|8@1+ (1,0) [0|0] "" Vector__XXX
 SG_ PARK_rearRightMiddleRawDistData : 16|8@1+ (1,0) [0|0] "" Vector__XXX
 SG_ PARK_pasRearMiddleCounter : 24|4@1+ (1,0) [0|0] "" Vector__XXX
 SG_ PARK_pasRearMiddleChecksum : 32|8@1+ (1,0) [0|0] "" Vector__XXX

BO_ 873 APP_warningMatrix1: 8 Vector__XXX
 SG_ APP_w065_deserializerOvercurrent : 0|1@1+ (1,0) [0|0] "" Vector__XXX
 SG_ APP_w066_deserializerLockLost : 1|1@1+ (1,0) [0|0] "" Vector__XXX
 SG_ APP_w067_steeringAlignment : 2|1@1+ (1,0) [0|0] "" Vector__XXX
 SG_ APP_w068_vlInconsistency : 3|1@1+ (1,0) [0|0] "" Vector__XXX
 SG_ APP_w069_apcSpaceMasked : 4|1@1+ (1,0) [0|0] "" Vector__XXX
 SG_ APP_w070_apcIncompleteCal : 5|1@1+ (1,0) [0|0] "" Vector__XXX
 SG_ APP_w071_selfparkStarted : 6|1@1+ (1,0) [0|0] "" Vector__XXX
 SG_ APP_w072_selfparkComplete : 7|1@1+ (1,0) [0|0] "" Vector__XXX
 SG_ APP_w073_issueEscalatedLDW : 8|1@1+ (1,0) [0|0] "" Vector__XXX
 SG_ APP_w074_inPathStationaryObst : 9|1@1+ (1,0) [0|0] "" Vector__XXX
 SG_ APP_w075_scMia : 10|1@1+ (1,0) [0|0] "" Vector__XXX
 SG_ APP_w076_mobilEyeSetC : 11|1@1+ (1,0) [0|0] "" Vector__XXX
 SG_ APP_w077_pmmActive : 12|1@1+ (1,0) [0|0] "" Vector__XXX
 SG_ APP_w078_pmmActive2 : 13|1@1+ (1,0) [0|0] "" Vector__XXX
 SG_ APP_w079_edrAvailable : 14|1@1+ (1,0) [0|0] "" Vector__XXX
 SG_ APP_w080_accFailedActivation : 15|1@1+ (1,0) [0|0] "" Vector__XXX
 SG_ APP_w081_pmmActiveBraking : 16|1@1+ (1,0) [0|0] "" Vector__XXX
 SG_ APP_w082_inPathFSviolation : 17|1@1+ (1,0) [0|0] "" Vector__XXX
 SG_ APP_w083_inPathRADObject : 18|1@1+ (1,0) [0|0] "" Vector__XXX
 SG_ APP_w084_pmmIPSO : 19|1@1+ (1,0) [0|0] "" Vector__XXX
 SG_ APP_w085_pmmSteering : 20|1@1+ (1,0) [0|0] "" Vector__XXX
 SG_ APP_w086_robCollision : 21|1@1+ (1,0) [0|0] "" Vector__XXX
 SG_ APP_w087_DEPRECATED : 22|1@1+ (1,0) [0|0] "" Vector__XXX
 SG_ APP_w088_DEPRECATED : 23|1@1+ (1,0) [0|0] "" Vector__XXX
 SG_ APP_w089_DEPRECATED : 24|1@1+ (1,0) [0|0] "" Vector__XXX
 SG_ APP_w090_DEPRECATED : 25|1@1+ (1,0) [0|0] "" Vector__XXX
 SG_ APP_w091_DEPRECATED : 26|1@1+ (1,0) [0|0] "" Vector__XXX
 SG_ APP_w092_DEPRECATED : 27|1@1+ (1,0) [0|0] "" Vector__XXX
 SG_ APP_w093_DEPRECATED : 28|1@1+ (1,0) [0|0] "" Vector__XXX
 SG_ APP_w094_DEPRECATED : 29|1@1+ (1,0) [0|0] "" Vector__XXX
 SG_ APP_w095_DEPRECATED : 30|1@1+ (1,0) [0|0] "" Vector__XXX
 SG_ APP_w096_DEPRECATED : 31|1@1+ (1,0) [0|0] "" Vector__XXX
 SG_ APP_w097_DEPRECATED : 32|1@1+ (1,0) [0|0] "" Vector__XXX
 SG_ APP_w098_DEPRECATED : 33|1@1+ (1,0) [0|0] "" Vector__XXX
 SG_ APP_w099_DEPRECATED : 34|1@1+ (1,0) [0|0] "" Vector__XXX
 SG_ APP_w100_DEPRECATED : 35|1@1+ (1,0) [0|0] "" Vector__XXX
 SG_ APP_w101_DEPRECATED : 36|1@1+ (1,0) [0|0] "" Vector__XXX
 SG_ APP_w102_DEPRECATED : 37|1@1+ (1,0) [0|0] "" Vector__XXX
 SG_ APP_w103_robExperimentalAEB : 38|1@1+ (1,0) [0|0] "" Vector__XXX
 SG_ APP_w104_DEPRECATED : 39|1@1+ (1,0) [0|0] "" Vector__XXX
 SG_ APP_w105_DEPRECATED : 40|1@1+ (1,0) [0|0] "" Vector__XXX
 SG_ APP_w106_torsionBarOffset : 41|1@1+ (1,0) [0|0] "" Vector__XXX

BO_ 874 DAS_warningMatrix1: 8 Vector__XXX
 SG_ DAS_w065_deserializerOvercurrent : 0|1@1+ (1,0) [0|0] "" Vector__XXX
 SG_ DAS_w066_deserializerLockLost : 1|1@1+ (1,0) [0|0] "" Vector__XXX
 SG_ DAS_w067_steeringAlignment : 2|1@1+ (1,0) [0|0] "" Vector__XXX
 SG_ DAS_w068_vlInconsistency : 3|1@1+ (1,0) [0|0] "" Vector__XXX
 SG_ DAS_w069_apcSpaceMasked : 4|1@1+ (1,0) [0|0] "" Vector__XXX
 SG_ DAS_w070_apcIncompleteCal : 5|1@1+ (1,0) [0|0] "" Vector__XXX
 SG_ DAS_w071_selfparkStarted : 6|1@1+ (1,0) [0|0] "" Vector__XXX
 SG_ DAS_w072_selfparkComplete : 7|1@1+ (1,0) [0|0] "" Vector__XXX
 SG_ DAS_w073_issueEscalatedLDW : 8|1@1+ (1,0) [0|0] "" Vector__XXX
 SG_ DAS_w074_inPathStationaryObst : 9|1@1+ (1,0) [0|0] "" Vector__XXX
 SG_ DAS_w075_scMia : 10|1@1+ (1,0) [0|0] "" Vector__XXX
 SG_ DAS_w076_mobilEyeSetC : 11|1@1+ (1,0) [0|0] "" Vector__XXX
 SG_ DAS_w077_pmmActive : 12|1@1+ (1,0) [0|0] "" Vector__XXX
 SG_ DAS_w078_pmmActive2 : 13|1@1+ (1,0) [0|0] "" Vector__XXX
 SG_ DAS_w079_edrAvailable : 14|1@1+ (1,0) [0|0] "" Vector__XXX
 SG_ DAS_w080_accFailedActivation : 15|1@1+ (1,0) [0|0] "" Vector__XXX
 SG_ DAS_w081_pmmActiveBraking : 16|1@1+ (1,0) [0|0] "" Vector__XXX
 SG_ DAS_w082_inPathFSviolation : 17|1@1+ (1,0) [0|0] "" Vector__XXX
 SG_ DAS_w083_inPathRADObject : 18|1@1+ (1,0) [0|0] "" Vector__XXX
 SG_ DAS_w084_pmmIPSO : 19|1@1+ (1,0) [0|0] "" Vector__XXX
 SG_ DAS_w085_pmmSteering : 20|1@1+ (1,0) [0|0] "" Vector__XXX
 SG_ DAS_w086_robCollision : 21|1@1+ (1,0) [0|0] "" Vector__XXX
 SG_ DAS_w087_DEPRECATED : 22|1@1+ (1,0) [0|0] "" Vector__XXX
 SG_ DAS_w088_DEPRECATED : 23|1@1+ (1,0) [0|0] "" Vector__XXX
 SG_ DAS_w089_DEPRECATED : 24|1@1+ (1,0) [0|0] "" Vector__XXX
 SG_ DAS_w090_DEPRECATED : 25|1@1+ (1,0) [0|0] "" Vector__XXX
 SG_ DAS_w091_DEPRECATED : 26|1@1+ (1,0) [0|0] "" Vector__XXX
 SG_ DAS_w092_DEPRECATED : 27|1@1+ (1,0) [0|0] "" Vector__XXX
 SG_ DAS_w093_DEPRECATED : 28|1@1+ (1,0) [0|0] "" Vector__XXX
 SG_ DAS_w094_DEPRECATED : 29|1@1+ (1,0) [0|0] "" Vector__XXX
 SG_ DAS_w095_DEPRECATED : 30|1@1+ (1,0) [0|0] "" Vector__XXX
 SG_ DAS_w096_DEPRECATED : 31|1@1+ (1,0) [0|0] "" Vector__XXX
 SG_ DAS_w097_DEPRECATED : 32|1@1+ (1,0) [0|0] "" Vector__XXX
 SG_ DAS_w098_DEPRECATED : 33|1@1+ (1,0) [0|0] "" Vector__XXX
 SG_ DAS_w099_DEPRECATED : 34|1@1+ (1,0) [0|0] "" Vector__XXX
 SG_ DAS_w100_DEPRECATED : 35|1@1+ (1,0) [0|0] "" Vector__XXX
 SG_ DAS_w101_DEPRECATED : 36|1@1+ (1,0) [0|0] "" Vector__XXX
 SG_ DAS_w102_DEPRECATED : 37|1@1+ (1,0) [0|0] "" Vector__XXX
 SG_ DAS_w103_robExperimentalAEB : 38|1@1+ (1,0) [0|0] "" Vector__XXX
 SG_ DAS_w104_DEPRECATED : 39|1@1+ (1,0) [0|0] "" Vector__XXX
 SG_ DAS_w105_DEPRECATED : 40|1@1+ (1,0) [0|0] "" Vector__XXX
 SG_ DAS_w106_torsionBarCalibrated : 41|1@1+ (1,0) [0|0] "" Vector__XXX

BO_ 876 APS_warningMatrix1: 8 Vector__XXX
 SG_ APS_w065_deserializerOvercurrent : 0|1@1+ (1,0) [0|0] "" Vector__XXX
 SG_ APS_w066_deserializerLockLost : 1|1@1+ (1,0) [0|0] "" Vector__XXX
 SG_ APS_w067_steeringAlignment : 2|1@1+ (1,0) [0|0] "" Vector__XXX
 SG_ APS_w068_vlInconsistency : 3|1@1+ (1,0) [0|0] "" Vector__XXX
 SG_ APS_w069_apcSpaceMasked : 4|1@1+ (1,0) [0|0] "" Vector__XXX
 SG_ APS_w070_apcIncompleteCal : 5|1@1+ (1,0) [0|0] "" Vector__XXX
 SG_ APS_w071_selfparkStarted : 6|1@1+ (1,0) [0|0] "" Vector__XXX
 SG_ APS_w072_selfparkComplete : 7|1@1+ (1,0) [0|0] "" Vector__XXX
 SG_ APS_w073_issueEscalatedLDW : 8|1@1+ (1,0) [0|0] "" Vector__XXX
 SG_ APS_w074_inPathStationaryObst : 9|1@1+ (1,0) [0|0] "" Vector__XXX
 SG_ APS_w075_scMia : 10|1@1+ (1,0) [0|0] "" Vector__XXX
 SG_ APS_w076_mobilEyeSetC : 11|1@1+ (1,0) [0|0] "" Vector__XXX
 SG_ APS_w077_pmmActive : 12|1@1+ (1,0) [0|0] "" Vector__XXX
 SG_ APS_w078_pmmActive2 : 13|1@1+ (1,0) [0|0] "" Vector__XXX
 SG_ APS_w079_edrAvailable : 14|1@1+ (1,0) [0|0] "" Vector__XXX
 SG_ APS_w080_accFailedActivation : 15|1@1+ (1,0) [0|0] "" Vector__XXX
 SG_ APS_w081_pmmActiveBraking : 16|1@1+ (1,0) [0|0] "" Vector__XXX
 SG_ APS_w082_inPathFSviolation : 17|1@1+ (1,0) [0|0] "" Vector__XXX
 SG_ APS_w083_inPathRADObject : 18|1@1+ (1,0) [0|0] "" Vector__XXX
 SG_ APS_w084_pmmIPSO : 19|1@1+ (1,0) [0|0] "" Vector__XXX
 SG_ APS_w085_pmmSteering : 20|1@1+ (1,0) [0|0] "" Vector__XXX
 SG_ APS_w086_robCollision : 21|1@1+ (1,0) [0|0] "" Vector__XXX
 SG_ APS_w087_DEPRECATED : 22|1@1+ (1,0) [0|0] "" Vector__XXX
 SG_ APS_w088_DEPRECATED : 23|1@1+ (1,0) [0|0] "" Vector__XXX
 SG_ APS_w089_DEPRECATED : 24|1@1+ (1,0) [0|0] "" Vector__XXX
 SG_ APS_w090_DEPRECATED : 25|1@1+ (1,0) [0|0] "" Vector__XXX
 SG_ APS_w091_DEPRECATED : 26|1@1+ (1,0) [0|0] "" Vector__XXX
 SG_ APS_w092_DEPRECATED : 27|1@1+ (1,0) [0|0] "" Vector__XXX
 SG_ APS_w093_DEPRECATED : 28|1@1+ (1,0) [0|0] "" Vector__XXX
 SG_ APS_w094_DEPRECATED : 29|1@1+ (1,0) [0|0] "" Vector__XXX
 SG_ APS_w095_DEPRECATED : 30|1@1+ (1,0) [0|0] "" Vector__XXX
 SG_ APS_w096_DEPRECATED : 31|1@1+ (1,0) [0|0] "" Vector__XXX
 SG_ APS_w097_DEPRECATED : 32|1@1+ (1,0) [0|0] "" Vector__XXX
 SG_ APS_w098_DEPRECATED : 33|1@1+ (1,0) [0|0] "" Vector__XXX
 SG_ APS_w099_DEPRECATED : 34|1@1+ (1,0) [0|0] "" Vector__XXX
 SG_ APS_w100_DEPRECATED : 35|1@1+ (1,0) [0|0] "" Vector__XXX
 SG_ APS_w101_DEPRECATED : 36|1@1+ (1,0) [0|0] "" Vector__XXX
 SG_ APS_w102_DEPRECATED : 37|1@1+ (1,0) [0|0] "" Vector__XXX
 SG_ APS_w103_robExperimentalAEB : 38|1@1+ (1,0) [0|0] "" Vector__XXX
 SG_ APS_w104_DEPRECATED : 39|1@1+ (1,0) [0|0] "" Vector__XXX
 SG_ APS_w105_DEPRECATED : 40|1@1+ (1,0) [0|0] "" Vector__XXX
 SG_ APS_w106_torsionBarOffset : 41|1@1+ (1,0) [0|0] "" Vector__XXX

BO_ 879 TPMS_StatusC: 8 Vector__XXX
 SG_ TPMS_c_globalHardWarning : 0|1@1+ (1,0) [0|0] "" Vector__XXX
 SG_ TPMS_c_globalSoftWarning : 1|1@1+ (1,0) [0|0] "" Vector__XXX
 SG_ TPMS_systemMalfunction : 2|1@1+ (1,0) [0|0] "" Vector__XXX
 SG_ TPMS_WA_version : 3|1@1+ (1,0) [0|0] "" Vector__XXX
 SG_ TPMS_globalDeltaPressure : 4|1@1+ (1,0) [0|0] "" Vector__XXX
 SG_ TPMS_newSensorLearnt : 5|3@1+ (1,0) [0|0] "" Vector__XXX
 SG_ TPMS_softWarningRR : 8|1@1+ (1,0) [0|0] "" Vector__XXX
 SG_ TPMS_hardWarningRR : 9|1@1+ (1,0) [0|0] "" Vector__XXX
 SG_ TPMS_softWarningRL : 10|1@1+ (1,0) [0|0] "" Vector__XXX
 SG_ TPMS_hardWarningRL : 11|1@1+ (1,0) [0|0] "" Vector__XXX
 SG_ TPMS_softWarningFR : 12|1@1+ (1,0) [0|0] "" Vector__XXX
 SG_ TPMS_hardWarningFR : 13|1@1+ (1,0) [0|0] "" Vector__XXX
 SG_ TPMS_softWarningFL : 14|1@1+ (1,0) [0|0] "" Vector__XXX
 SG_ TPMS_hardWarningFL : 15|1@1+ (1,0) [0|0] "" Vector__XXX
 SG_ TPMS_learningStatus : 16|2@1+ (1,0) [0|0] "" Vector__XXX
 SG_ TPMS_localisationStatus : 18|2@1+ (1,0) [0|0] "" Vector__XXX
 SG_ TPMS_deltaPressWarningFL : 20|1@1+ (1,0) [0|0] "" Vector__XXX
 SG_ TPMS_deltaPressWarningFR : 21|1@1+ (1,0) [0|0] "" Vector__XXX
 SG_ TPMS_deltaPressWarningRL : 22|1@1+ (1,0) [0|0] "" Vector__XXX
 SG_ TPMS_deltaPressWarningRR : 23|1@1+ (1,0) [0|0] "" Vector__XXX
 SG_ TPMS_sensorNoResponseFL : 24|1@1+ (1,0) [0|0] "" Vector__XXX
 SG_ TPMS_sensorNoResponseFR : 25|1@1+ (1,0) [0|0] "" Vector__XXX
 SG_ TPMS_sensorNoResponseRL : 26|1@1+ (1,0) [0|0] "" Vector__XXX
 SG_ TPMS_sensorNoResponseRR : 27|1@1+ (1,0) [0|0] "" Vector__XXX
 SG_ TPMS_sensorThermShutdownFL : 28|1@1+ (1,0) [0|0] "" Vector__XXX
 SG_ TPMS_sensorThermShutdownFR : 29|1@1+ (1,0) [0|0] "" Vector__XXX
 SG_ TPMS_sensorThermShutdownRL : 30|1@1+ (1,0) [0|0] "" Vector__XXX
 SG_ TPMS_sensorThermShutdownRR : 31|1@1+ (1,0) [0|0] "" Vector__XXX
 SG_ TPMS_sensorBatteryLowFL : 32|1@1+ (1,0) [0|0] "" Vector__XXX
 SG_ TPMS_sensorBatteryLowFR : 33|1@1+ (1,0) [0|0] "" Vector__XXX
 SG_ TPMS_sensorBatteryLowRL : 34|1@1+ (1,0) [0|0] "" Vector__XXX
 SG_ TPMS_sensorBatteryLowRR : 35|1@1+ (1,0) [0|0] "" Vector__XXX
 SG_ TPMS_sensorDefectiveFL : 36|1@1+ (1,0) [0|0] "" Vector__XXX
 SG_ TPMS_sensorDefectiveFR : 37|1@1+ (1,0) [0|0] "" Vector__XXX
 SG_ TPMS_sensorDefectiveRL : 38|1@1+ (1,0) [0|0] "" Vector__XXX
 SG_ TPMS_sensorDefectiveRR : 39|1@1+ (1,0) [0|0] "" Vector__XXX
 SG_ TPMS_ecuUnderVoltage : 40|1@1+ (1,0) [0|0] "" Vector__XXX
 SG_ TPMS_ecuOverVoltage : 41|1@1+ (1,0) [0|0] "" Vector__XXX
 SG_ TPMS_ecuRamRomNvMFail : 42|1@1+ (1,0) [0|0] "" Vector__XXX
 SG_ TPMS_rfReceiverFail : 43|1@1+ (1,0) [0|0] "" Vector__XXX
 SG_ TPMS_wheelPulseMissing : 44|1@1+ (1,0) [0|0] "" Vector__XXX
 SG_ TPMS_vehicleSpeedFail : 45|1@1+ (1,0) [0|0] "" Vector__XXX
 SG_ TPMS_externalTemperatureFail : 46|1@1+ (1,0) [0|0] "" Vector__XXX
 SG_ TPMS_eolNotCompleted : 47|1@1+ (1,0) [0|0] "" Vector__XXX
 SG_ TPMS_rcpFront : 48|8@1+ (0.025,0) [0|0] "" Vector__XXX
 SG_ TPMS_rcpRear : 56|8@1+ (0.025,0) [0|0] "" Vector__XXX

BO_ 880 EPAS3S_sysStatus: 12 Vector__XXX
 SG_ EPAS3S_steeringRackForce : 1|10@0+ (50,-25575) [0|0] "" Vector__XXX
 SG_ EPAS3S_steeringFault : 2|1@0+ (1,0) [0|0] "" Vector__XXX
 SG_ EPAS3S_steeringReduced : 3|1@0+ (1,0) [0|0] "" Vector__XXX
 SG_ EPAS3S_internalSASQF : 4|1@0+ (1,0) [0|0] "" Vector__XXX
 SG_ EPAS3S_currentTuneMode : 7|3@0+ (1,0) [0|0] "" Vector__XXX
 SG_ EPAS3S_torsionBarTorque : 19|12@0+ (0.01,-20.5) [0|0] "" Vector__XXX
 SG_ EPAS3S_eacErrorCode : 23|4@0+ (1,0) [0|0] "" Vector__XXX
 SG_ EPAS3S_internalSAS : 37|14@0+ (0.1,-819.2) [0|0] "" Vector__XXX
 SG_ EPAS3S_handsOnLevel : 39|2@0+ (1,0) [0|0] "" Vector__XXX
 SG_ EPAS3S_sysStatusCounter : 51|4@0+ (1,0) [0|0] "" Vector__XXX
 SG_ EPAS3S_driverlessState : 52|1@0+ (1,0) [0|0] "" Vector__XXX
 SG_ EPAS3S_eacStatus : 55|3@0+ (1,0) [0|0] "" Vector__XXX
 SG_ EPAS3S_sysStatusChecksum : 63|8@0+ (1,0) [0|0] "" Vector__XXX

BO_ 881 RCM_alertMatrix: 8 Vector__XXX
 SG_ RCM_matrixIndex M : 0|4@1+ (1,0) [0|0] "" Vector__XXX
 SG_ RCM_a000_crashDetected m0 : 4|1@1+ (1,0) [0|0] "" Vector__XXX
 SG_ RCM_a060_stpsLeft m1 : 4|1@1+ (1,0) [0|0] "" Vector__XXX
 SG_ RCM_a001_nearDeploy m0 : 5|1@1+ (1,0) [0|0] "" Vector__XXX
 SG_ RCM_a061_stpsRight m1 : 5|1@1+ (1,0) [0|0] "" Vector__XXX
 SG_ RCM_a002_airbagsNotArmed m0 : 6|1@1+ (1,0) [0|0] "" Vector__XXX
 SG_ RCM_a062_alrSwitch m1 : 6|1@1+ (1,0) [0|0] "" Vector__XXX
 SG_ RCM_a003_warningIndicator m0 : 7|1@1+ (1,0) [0|0] "" Vector__XXX
 SG_ RCM_a063_sbsw2ndRowRight m1 : 7|1@1+ (1,0) [0|0] "" Vector__XXX
 SG_ RCM_a004_internalFault m0 : 8|1@1+ (1,0) [0|0] "" Vector__XXX
 SG_ RCM_a064_hardwareCodingPin1 m1 : 8|1@1+ (1,0) [0|0] "" Vector__XXX
 SG_ RCM_a005_crcError m0 : 9|1@1+ (1,0) [0|0] "" Vector__XXX
 SG_ RCM_a065_driverOrientConfigPin m1 : 9|1@1+ (1,0) [0|0] "" Vector__XXX
 SG_ RCM_a006_batteryVoltageRange m0 : 10|1@1+ (1,0) [0|0] "" Vector__XXX
 SG_ RCM_a066_seatBackSw2ndRowLeft m1 : 10|1@1+ (1,0) [0|0] "" Vector__XXX
 SG_ RCM_a007_powerSupplyExternal m0 : 11|1@1+ (1,0) [0|0] "" Vector__XXX
 SG_ RCM_a067_comCANInitFailure m1 : 11|1@1+ (1,0) [0|0] "" Vector__XXX
 SG_ RCM_a008_powerSupplyInternal m0 : 12|1@1+ (1,0) [0|0] "" Vector__XXX
 SG_ RCM_a068_comChassisBusOff m1 : 12|1@1+ (1,0) [0|0] "" Vector__XXX
 SG_ RCM_a009_reprogramLimit m0 : 13|1@1+ (1,0) [0|0] "" Vector__XXX
 SG_ RCM_a069_comCHCANPH7 m1 : 13|1@1+ (1,0) [0|0] "" Vector__XXX
 SG_ RCM_a010_scmDisabled m0 : 14|1@1+ (1,0) [0|0] "" Vector__XXX
 SG_ RCM_a070_comCHCANPH8 m1 : 14|1@1+ (1,0) [0|0] "" Vector__XXX
 SG_ RCM_a011_eepromDataLocked m0 : 15|1@1+ (1,0) [0|0] "" Vector__XXX
 SG_ RCM_a071_comCHCANPH9 m1 : 15|1@1+ (1,0) [0|0] "" Vector__XXX
 SG_ RCM_a012_vinStorage m0 : 16|1@1+ (1,0) [0|0] "" Vector__XXX
 SG_ RCM_a072_comUnused m1 : 16|1@1+ (1,0) [0|0] "" Vector__XXX
 SG_ RCM_a013_driverOrientation m0 : 17|1@1+ (1,0) [0|0] "" Vector__XXX
 SG_ RCM_a073_comCHCANPH4 m1 : 17|1@1+ (1,0) [0|0] "" Vector__XXX
 SG_ RCM_a014_driverABStage1 m0 : 18|1@1+ (1,0) [0|0] "" Vector__XXX
 SG_ RCM_a074_comCHCANPH5 m1 : 18|1@1+ (1,0) [0|0] "" Vector__XXX
 SG_ RCM_a015_driverABStage2 m0 : 19|1@1+ (1,0) [0|0] "" Vector__XXX
 SG_ RCM_a075_comCHCANPH6 m1 : 19|1@1+ (1,0) [0|0] "" Vector__XXX
 SG_ RCM_a016_passABStage1 m0 : 20|1@1+ (1,0) [0|0] "" Vector__XXX
 SG_ RCM_a076_comEPBLStatus m1 : 20|1@1+ (1,0) [0|0] "" Vector__XXX
 SG_ RCM_a017_passABStage2 m0 : 21|1@1+ (1,0) [0|0] "" Vector__XXX
 SG_ RCM_a077_comEPBRStatus m1 : 21|1@1+ (1,0) [0|0] "" Vector__XXX
 SG_ RCM_a018_passengerActiveVent m0 : 22|1@1+ (1,0) [0|0] "" Vector__XXX
 SG_ RCM_a078_comOCS1PStatus m1 : 22|1@1+ (1,0) [0|0] "" Vector__XXX
 SG_ RCM_a019_pretenShldrFrontLeft m0 : 23|1@1+ (1,0) [0|0] "" Vector__XXX
 SG_ RCM_a079_comOCS1DStatus m1 : 23|1@1+ (1,0) [0|0] "" Vector__XXX
 SG_ RCM_a020_pretenShldFrontRight m0 : 24|1@1+ (1,0) [0|0] "" Vector__XXX
 SG_ RCM_a080_comGTWACS m1 : 24|1@1+ (1,0) [0|0] "" Vector__XXX
 SG_ RCM_a021_pretenLapFrontLeft m0 : 25|1@1+ (1,0) [0|0] "" Vector__XXX
 SG_ RCM_a081_comVCFRONTLVPwr m1 : 25|1@1+ (1,0) [0|0] "" Vector__XXX
 SG_ RCM_a022_pretenLapFrontRight m0 : 26|1@1+ (1,0) [0|0] "" Vector__XXX
 SG_ RCM_a082_comUIodo m1 : 26|1@1+ (1,0) [0|0] "" Vector__XXX
 SG_ RCM_a023_loadLimiterLeftSide m0 : 27|1@1+ (1,0) [0|0] "" Vector__XXX
 SG_ RCM_a083_comGTWCarState m1 : 27|1@1+ (1,0) [0|0] "" Vector__XXX
 SG_ RCM_a024_loadLimiterRightSide m0 : 28|1@1+ (1,0) [0|0] "" Vector__XXX
 SG_ RCM_a084_comTPMSStatus m1 : 28|1@1+ (1,0) [0|0] "" Vector__XXX
 SG_ RCM_a025_kneeABDriver m0 : 29|1@1+ (1,0) [0|0] "" Vector__XXX
 SG_ RCM_a085_comGTWCarConfig m1 : 29|1@1+ (1,0) [0|0] "" Vector__XXX
 SG_ RCM_a026_kneeABFrontPassenger m0 : 30|1@1+ (1,0) [0|0] "" Vector__XXX
 SG_ RCM_a086_comVINMIA m1 : 30|1@1+ (1,0) [0|0] "" Vector__XXX
 SG_ RCM_a027_sideAB1stRowLeft m0 : 31|1@1+ (1,0) [0|0] "" Vector__XXX
 SG_ RCM_a087_comCANSilent m1 : 31|1@1+ (1,0) [0|0] "" Vector__XXX
 SG_ RCM_a028_sideAB1stRowRight m0 : 32|1@1+ (1,0) [0|0] "" Vector__XXX
 SG_ RCM_a088_comCHCANPH2 m1 : 32|1@1+ (1,0) [0|0] "" Vector__XXX
 SG_ RCM_a029_driverABActiveVent m0 : 33|1@1+ (1,0) [0|0] "" Vector__XXX
 SG_ RCM_a089_comCHCANPH3 m1 : 33|1@1+ (1,0) [0|0] "" Vector__XXX
 SG_ RCM_a030_farSideInboardAirbag m0 : 34|1@1+ (1,0) [0|0] "" Vector__XXX
 SG_ RCM_a090_comPartyBusOff m1 : 34|1@1+ (1,0) [0|0] "" Vector__XXX
 SG_ RCM_a031_frontCenterAirbag m0 : 35|1@1+ (1,0) [0|0] "" Vector__XXX
 SG_ RCM_a091_comEPAS3PsysStatus m1 : 35|1@1+ (1,0) [0|0] "" Vector__XXX
 SG_ RCM_a032_curtainABLeft m0 : 36|1@1+ (1,0) [0|0] "" Vector__XXX
 SG_ RCM_a092_comDASISF m1 : 36|1@1+ (1,0) [0|0] "" Vector__XXX
 SG_ RCM_a033_curtainABRight m0 : 37|1@1+ (1,0) [0|0] "" Vector__XXX
 SG_ RCM_a093_comVCLEFTStatus m1 : 37|1@1+ (1,0) [0|0] "" Vector__XXX
 SG_ RCM_a034_preten2ndRowLeft m0 : 38|1@1+ (1,0) [0|0] "" Vector__XXX
 SG_ RCM_a094_comVCRIGHTStatus m1 : 38|1@1+ (1,0) [0|0] "" Vector__XXX
 SG_ RCM_a035_preten2ndRowRight m0 : 39|1@1+ (1,0) [0|0] "" Vector__XXX
 SG_ RCM_a095_comESPstatus m1 : 39|1@1+ (1,0) [0|0] "" Vector__XXX
 SG_ RCM_a036_curAB2ndRowLeft m0 : 40|1@1+ (1,0) [0|0] "" Vector__XXX
 SG_ RCM_a096_comESPwheelSpeeds m1 : 40|1@1+ (1,0) [0|0] "" Vector__XXX
 SG_ RCM_a037_curAB2ndRowRight m0 : 41|1@1+ (1,0) [0|0] "" Vector__XXX
 SG_ RCM_a097_comDIspeed m1 : 41|1@1+ (1,0) [0|0] "" Vector__XXX
 SG_ RCM_a038_unusedA m0 : 42|1@1+ (1,0) [0|0] "" Vector__XXX
 SG_ RCM_a098_comDIchassisControl m1 : 42|1@1+ (1,0) [0|0] "" Vector__XXX
 SG_ RCM_a039_unusedB m0 : 43|1@1+ (1,0) [0|0] "" Vector__XXX
 SG_ RCM_a099_comDItorque m1 : 43|1@1+ (1,0) [0|0] "" Vector__XXX
 SG_ RCM_a040_hoodActuatorRight m0 : 44|1@1+ (1,0) [0|0] "" Vector__XXX
 SG_ RCM_a100_comDIsystemStatus m1 : 44|1@1+ (1,0) [0|0] "" Vector__XXX
 SG_ RCM_a041_hoodActuatorLeft m0 : 45|1@1+ (1,0) [0|0] "" Vector__XXX
 SG_ RCM_a101_idfSystem m1 : 45|1@1+ (1,0) [0|0] "" Vector__XXX
 SG_ RCM_a042_ens1Line m0 : 46|1@1+ (1,0) [0|0] "" Vector__XXX
 SG_ RCM_a102_imuYawR8OffstCompLim m1 : 46|1@1+ (1,0) [0|0] "" Vector__XXX
 SG_ RCM_a043_ens2Line m0 : 47|1@1+ (1,0) [0|0] "" Vector__XXX
 SG_ RCM_a103_imuPtchR8OffstCompLim m1 : 47|1@1+ (1,0) [0|0] "" Vector__XXX
 SG_ RCM_a044_upFrontSensorLeft m0 : 48|1@1+ (1,0) [0|0] "" Vector__XXX
 SG_ RCM_a104_imuRollR8OffstCompLim m1 : 48|1@1+ (1,0) [0|0] "" Vector__XXX
 SG_ RCM_a045_upFrontSensorRight m0 : 49|1@1+ (1,0) [0|0] "" Vector__XXX
 SG_ RCM_a105_imuLongAccOffstCompLim m1 : 49|1@1+ (1,0) [0|0] "" Vector__XXX
 SG_ RCM_a046_sideAccelBPillarLeft m0 : 50|1@1+ (1,0) [0|0] "" Vector__XXX
 SG_ RCM_a106_imuLatAccOffstCompLim m1 : 50|1@1+ (1,0) [0|0] "" Vector__XXX
 SG_ RCM_a047_sideAccelBPillarRight m0 : 51|1@1+ (1,0) [0|0] "" Vector__XXX
 SG_ RCM_a107_imuVertAccOffstCompLim m1 : 51|1@1+ (1,0) [0|0] "" Vector__XXX
 SG_ RCM_a048_sideAccelCPillarLeft m0 : 52|1@1+ (1,0) [0|0] "" Vector__XXX
 SG_ RCM_a108_crashAlgoWakeup m1 : 52|1@1+ (1,0) [0|0] "" Vector__XXX
 SG_ RCM_a049_sideAccelCPillarRight m0 : 53|1@1+ (1,0) [0|0] "" Vector__XXX
 SG_ RCM_a109_abuseImmunity m1 : 53|1@1+ (1,0) [0|0] "" Vector__XXX
 SG_ RCM_a050_upFrontSensorCenter m0 : 54|1@1+ (1,0) [0|0] "" Vector__XXX
 SG_ RCM_a110_factoryMode m1 : 54|1@1+ (1,0) [0|0] "" Vector__XXX
 SG_ RCM_a051_pressureFrontLftDoor m0 : 55|1@1+ (1,0) [0|0] "" Vector__XXX
 SG_ RCM_a111_diagnosticsEnabled m1 : 55|1@1+ (1,0) [0|0] "" Vector__XXX
 SG_ RCM_a052_pressureFrontRtDoor m0 : 56|1@1+ (1,0) [0|0] "" Vector__XXX
 SG_ RCM_a112_imuYawRate m1 : 56|1@1+ (1,0) [0|0] "" Vector__XXX
 SG_ RCM_a053_pressurePedProLeft m0 : 57|1@1+ (1,0) [0|0] "" Vector__XXX
 SG_ RCM_a113_imuPitchRate m1 : 57|1@1+ (1,0) [0|0] "" Vector__XXX
 SG_ RCM_a054_pressurePedProRight m0 : 58|1@1+ (1,0) [0|0] "" Vector__XXX
 SG_ RCM_a114_imuRollRate m1 : 58|1@1+ (1,0) [0|0] "" Vector__XXX
 SG_ RCM_a055_inertialMeasurement m0 : 59|1@1+ (1,0) [0|0] "" Vector__XXX
 SG_ RCM_a115_imuLinearAcceleration m1 : 59|1@1+ (1,0) [0|0] "" Vector__XXX
 SG_ RCM_a056_passengerFrontOCS m0 : 60|1@1+ (1,0) [0|0] "" Vector__XXX
 SG_ RCM_a116_imuLateralAcceleration m1 : 60|1@1+ (1,0) [0|0] "" Vector__XXX
 SG_ RCM_a057_driverOCS m0 : 61|1@1+ (1,0) [0|0] "" Vector__XXX
 SG_ RCM_a117_imuVerticalAcceleration m1 : 61|1@1+ (1,0) [0|0] "" Vector__XXX
 SG_ RCM_a058_buckle1stRowLeft m0 : 62|1@1+ (1,0) [0|0] "" Vector__XXX
 SG_ RCM_a118_imuInPlaneAcceleration m1 : 62|1@1+ (1,0) [0|0] "" Vector__XXX
 SG_ RCM_a059_buckle1stRowRight m0 : 63|1@1+ (1,0) [0|0] "" Vector__XXX

BO_ 882 TRCM_alertMatrix: 8 Vector__XXX
 SG_ TRCM_matrixIndex M : 0|4@1+ (1,0) [0|0] "" Vector__XXX
 SG_ TRCM_a001_airbagsDisabled m0 : 4|1@1+ (1,0) [0|0] "" Vector__XXX
 SG_ TRCM_a061_XCPConnected m1 : 4|1@1+ (1,0) [0|0] "" Vector__XXX
 SG_ TRCM_a301_passengerAirbagStage1Suppressed m5 : 4|1@1+ (1,0) [0|0] "" Vector__XXX
 SG_ TRCM_a421_hoodLifterRightIssue m7 : 4|1@1+ (1,0) [0|0] "" Vector__XXX
 SG_ TRCM_a601_loop0AsicStartupDiagnosticFailure m10 : 4|1@1+ (1,0) [0|0] "" Vector__XXX
 SG_ TRCM_a002_systemDisabled m0 : 5|1@1+ (1,0) [0|0] "" Vector__XXX
 SG_ TRCM_a062_XCPWasConnected m1 : 5|1@1+ (1,0) [0|0] "" Vector__XXX
 SG_ TRCM_a302_driverAirbagStage2Suppressed m5 : 5|1@1+ (1,0) [0|0] "" Vector__XXX
 SG_ TRCM_a422_seatbeltShoulderPretensionerRearLeftIssue m7 : 5|1@1+ (1,0) [0|0] "" Vector__XXX
 SG_ TRCM_a602_loop1AsicStartupDiagnosticFailure m10 : 5|1@1+ (1,0) [0|0] "" Vector__XXX
 SG_ TRCM_a003_SWAssertion m0 : 6|1@1+ (1,0) [0|0] "" Vector__XXX
 SG_ TRCM_a063_SwitchFault m1 : 6|1@1+ (1,0) [0|0] "" Vector__XXX
 SG_ TRCM_a303_driverAirbagActiveVentSuppressed m5 : 6|1@1+ (1,0) [0|0] "" Vector__XXX
 SG_ TRCM_a423_seatbeltShoulderPretensionerRearRightIssue m7 : 6|1@1+ (1,0) [0|0] "" Vector__XXX
 SG_ TRCM_a603_loop2AsicStartupDiagnosticFailure m10 : 6|1@1+ (1,0) [0|0] "" Vector__XXX
 SG_ TRCM_a004_internalFailure m0 : 7|1@1+ (1,0) [0|0] "" Vector__XXX
 SG_ TRCM_a064_busSleepReqTimeout m1 : 7|1@1+ (1,0) [0|0] "" Vector__XXX
 SG_ TRCM_a304_passengerAirbagStage2Suppressed m5 : 7|1@1+ (1,0) [0|0] "" Vector__XXX
 SG_ TRCM_a364_safingEngine0NoValidData m6 : 7|1@1+ (1,0) [0|0] "" Vector__XXX
 SG_ TRCM_a544_erCapDiagnosticsFailed m9 : 7|1@1+ (1,0) [0|0] "" Vector__XXX
 SG_ TRCM_a604_loop3AsicStartupDiagnosticFailure m10 : 7|1@1+ (1,0) [0|0] "" Vector__XXX
 SG_ TRCM_a005_CANTXError m0 : 8|1@1+ (1,0) [0|0] "" Vector__XXX
 SG_ TRCM_a065_vSafingFetUnderVoltage m1 : 8|1@1+ (1,0) [0|0] "" Vector__XXX
 SG_ TRCM_a305_passengerAirbagActiveVentSuppressed m5 : 8|1@1+ (1,0) [0|0] "" Vector__XXX
 SG_ TRCM_a365_safingEngine1NoValidData m6 : 8|1@1+ (1,0) [0|0] "" Vector__XXX
 SG_ TRCM_a545_erCapBelowAutarkyThreshold m9 : 8|1@1+ (1,0) [0|0] "" Vector__XXX
 SG_ TRCM_a605_loop4AsicStartupDiagnosticFailure m10 : 8|1@1+ (1,0) [0|0] "" Vector__XXX
 SG_ TRCM_a006_CANTX_cyclicError m0 : 9|1@1+ (1,0) [0|0] "" Vector__XXX
 SG_ TRCM_a066_leftPowerIssue m1 : 9|1@1+ (1,0) [0|0] "" Vector__XXX
 SG_ TRCM_a366_safingEngine2NoValidData m6 : 9|1@1+ (1,0) [0|0] "" Vector__XXX
 SG_ TRCM_a546_sensorValuesFaultedBySmart m9 : 9|1@1+ (1,0) [0|0] "" Vector__XXX
 SG_ TRCM_a606_loop5AsicStartupDiagnosticFailure m10 : 9|1@1+ (1,0) [0|0] "" Vector__XXX
 SG_ TRCM_a007_chassisChecksumError m0 : 10|1@1+ (1,0) [0|0] "" Vector__XXX
 SG_ TRCM_a067_rightPowerIssue m1 : 10|1@1+ (1,0) [0|0] "" Vector__XXX
 SG_ TRCM_a367_safingEngine3NoValidData m6 : 10|1@1+ (1,0) [0|0] "" Vector__XXX
 SG_ TRCM_a607_loop6AsicStartupDiagnosticFailure m10 : 10|1@1+ (1,0) [0|0] "" Vector__XXX
 SG_ TRCM_a008_chassisCounterError m0 : 11|1@1+ (1,0) [0|0] "" Vector__XXX
 SG_ TRCM_a068_vBusCUnderVoltage m1 : 11|1@1+ (1,0) [0|0] "" Vector__XXX
 SG_ TRCM_a308_kneeAirbagLeftSuppressed m5 : 11|1@1+ (1,0) [0|0] "" Vector__XXX
 SG_ TRCM_a368_safingEngine4NoValidData m6 : 11|1@1+ (1,0) [0|0] "" Vector__XXX
 SG_ TRCM_a608_loop7AsicStartupDiagnosticFailure m10 : 11|1@1+ (1,0) [0|0] "" Vector__XXX
 SG_ TRCM_a009_partyChecksumError m0 : 12|1@1+ (1,0) [0|0] "" Vector__XXX
 SG_ TRCM_a069_swAppBoot m1 : 12|1@1+ (1,0) [0|0] "" Vector__XXX
 SG_ TRCM_a309_kneeAirbagRightSuppressed m5 : 12|1@1+ (1,0) [0|0] "" Vector__XXX
 SG_ TRCM_a369_safingEngine5NoValidData m6 : 12|1@1+ (1,0) [0|0] "" Vector__XXX
 SG_ TRCM_a609_loop8AsicStartupDiagnosticFailure m10 : 12|1@1+ (1,0) [0|0] "" Vector__XXX
 SG_ TRCM_a010_partyCounterError m0 : 13|1@1+ (1,0) [0|0] "" Vector__XXX
 SG_ TRCM_a070_asm3StatusError m1 : 13|1@1+ (1,0) [0|0] "" Vector__XXX
 SG_ TRCM_a310_curtainAirbagLeftSuppressed m5 : 13|1@1+ (1,0) [0|0] "" Vector__XXX
 SG_ TRCM_a370_safingEngine6NoValidData m6 : 13|1@1+ (1,0) [0|0] "" Vector__XXX
 SG_ TRCM_a550_AlgoWake_RCM_WAKE_FRONT m9 : 13|1@1+ (1,0) [0|0] "" Vector__XXX
 SG_ TRCM_a610_loop9AsicStartupDiagnosticFailure m10 : 13|1@1+ (1,0) [0|0] "" Vector__XXX
 SG_ TRCM_a011_edrDataLocked m0 : 14|1@1+ (1,0) [0|0] "" Vector__XXX
 SG_ TRCM_a071_asm3DeviceFaulted m1 : 14|1@1+ (1,0) [0|0] "" Vector__XXX
 SG_ TRCM_a311_curtainAirbagRightSuppressed m5 : 14|1@1+ (1,0) [0|0] "" Vector__XXX
 SG_ TRCM_a371_safingEngine7NoValidData m6 : 14|1@1+ (1,0) [0|0] "" Vector__XXX
 SG_ TRCM_a551_AlgoWake_RCM_WAKE_REAR m9 : 14|1@1+ (1,0) [0|0] "" Vector__XXX
 SG_ TRCM_a611_loop10AsicStartupDiagnosticFailure m10 : 14|1@1+ (1,0) [0|0] "" Vector__XXX
 SG_ TRCM_a012_asm5TemperatureOutsideSignalRange m0 : 15|1@1+ (1,0) [0|0] "" Vector__XXX
 SG_ TRCM_a072_ais2120StatusError m1 : 15|1@1+ (1,0) [0|0] "" Vector__XXX
 SG_ TRCM_a312_seatbeltLoadLimiterFrontLeftSuppressed m5 : 15|1@1+ (1,0) [0|0] "" Vector__XXX
 SG_ TRCM_a372_safingEngine8NoValidData m6 : 15|1@1+ (1,0) [0|0] "" Vector__XXX
 SG_ TRCM_a432_driverAirbagStage1ConfigError m7 : 15|1@1+ (1,0) [0|0] "" Vector__XXX
 SG_ TRCM_a552_AlgoWake_RCM_WAKE_LEFT m9 : 15|1@1+ (1,0) [0|0] "" Vector__XXX
 SG_ TRCM_a612_loop11AsicStartupDiagnosticFailure m10 : 15|1@1+ (1,0) [0|0] "" Vector__XXX
 SG_ TRCM_a013_AlertManagerFault m0 : 16|1@1+ (1,0) [0|0] "" Vector__XXX
 SG_ TRCM_a073_ais2120DeviceFaulted m1 : 16|1@1+ (1,0) [0|0] "" Vector__XXX
 SG_ TRCM_a313_seatbeltLoadLimiterFrontRightSuppressed m5 : 16|1@1+ (1,0) [0|0] "" Vector__XXX
 SG_ TRCM_a373_safingEngine9NoValidData m6 : 16|1@1+ (1,0) [0|0] "" Vector__XXX
 SG_ TRCM_a433_passengerAirbagStage1ConfigError m7 : 16|1@1+ (1,0) [0|0] "" Vector__XXX
 SG_ TRCM_a553_AlgoWake_RCM_WAKE_RIGHT m9 : 16|1@1+ (1,0) [0|0] "" Vector__XXX
 SG_ TRCM_a613_loop12AsicStartupDiagnosticFailure m10 : 16|1@1+ (1,0) [0|0] "" Vector__XXX
 SG_ TRCM_a014_asm3TemperatureOutsideSignalRange m0 : 17|1@1+ (1,0) [0|0] "" Vector__XXX
 SG_ TRCM_a074_ais2120SelfTestXPositiveFailed m1 : 17|1@1+ (1,0) [0|0] "" Vector__XXX
 SG_ TRCM_a314_seatbeltShoulderPretensionerFrontLeftSuppressed m5 : 17|1@1+ (1,0) [0|0] "" Vector__XXX
 SG_ TRCM_a374_safingEngine10NoValidData m6 : 17|1@1+ (1,0) [0|0] "" Vector__XXX
 SG_ TRCM_a434_driverAirbagStage2ConfigError m7 : 17|1@1+ (1,0) [0|0] "" Vector__XXX
 SG_ TRCM_a554_AlgoWake_PAS_LH_PLAUSI_FRONT m9 : 17|1@1+ (1,0) [0|0] "" Vector__XXX
 SG_ TRCM_a614_loop13AsicStartupDiagnosticFailure m10 : 17|1@1+ (1,0) [0|0] "" Vector__XXX
 SG_ TRCM_a015_NVMMError m0 : 18|1@1+ (1,0) [0|0] "" Vector__XXX
 SG_ TRCM_a075_ais2120SelfTestXNegativeFailed m1 : 18|1@1+ (1,0) [0|0] "" Vector__XXX
 SG_ TRCM_a135_asm5StatusError m2 : 18|1@1+ (1,0) [0|0] "" Vector__XXX
 SG_ TRCM_a315_seatbeltShoulderPretensionerFrontRightSuppressed m5 : 18|1@1+ (1,0) [0|0] "" Vector__XXX
 SG_ TRCM_a375_safingEngine11NoValidData m6 : 18|1@1+ (1,0) [0|0] "" Vector__XXX
 SG_ TRCM_a435_driverAirbagActiveVentConfigError m7 : 18|1@1+ (1,0) [0|0] "" Vector__XXX
 SG_ TRCM_a555_AlgoWake_PAS_LH_PLAUSI_REAR m9 : 18|1@1+ (1,0) [0|0] "" Vector__XXX
 SG_ TRCM_a615_loop14AsicStartupDiagnosticFailure m10 : 18|1@1+ (1,0) [0|0] "" Vector__XXX
 SG_ TRCM_a016_NVMMRecordError m0 : 19|1@1+ (1,0) [0|0] "" Vector__XXX
 SG_ TRCM_a076_ais2120SelfTestYPositiveFailed m1 : 19|1@1+ (1,0) [0|0] "" Vector__XXX
 SG_ TRCM_a136_asm5DeviceFaulted m2 : 19|1@1+ (1,0) [0|0] "" Vector__XXX
 SG_ TRCM_a316_seatbeltLapPretensionerFrontLeftSuppressed m5 : 19|1@1+ (1,0) [0|0] "" Vector__XXX
 SG_ TRCM_a376_safingEngine12NoValidData m6 : 19|1@1+ (1,0) [0|0] "" Vector__XXX
 SG_ TRCM_a436_passengerAirbagStage2ConfigError m7 : 19|1@1+ (1,0) [0|0] "" Vector__XXX
 SG_ TRCM_a556_AlgoWake_PAS_LH_PLAUSI m9 : 19|1@1+ (1,0) [0|0] "" Vector__XXX
 SG_ TRCM_a616_loop15AsicStartupDiagnosticFailure m10 : 19|1@1+ (1,0) [0|0] "" Vector__XXX
 SG_ TRCM_a017_asm5TemperatureOutsideOperatingRange m0 : 20|1@1+ (1,0) [0|0] "" Vector__XXX
 SG_ TRCM_a077_ais2120SelfTestYNegativeFailed m1 : 20|1@1+ (1,0) [0|0] "" Vector__XXX
 SG_ TRCM_a137_ext1AsicSnoopTestFailed m2 : 20|1@1+ (1,0) [0|0] "" Vector__XXX
 SG_ TRCM_a317_seatbeltLapPretensionerFrontRightSuppressed m5 : 20|1@1+ (1,0) [0|0] "" Vector__XXX
 SG_ TRCM_a377_safingEngine13NoValidData m6 : 20|1@1+ (1,0) [0|0] "" Vector__XXX
 SG_ TRCM_a437_passengerAirbagActiveVentConfigError m7 : 20|1@1+ (1,0) [0|0] "" Vector__XXX
 SG_ TRCM_a557_AlgoWake_PAS_RH_PLAUSI_FRONT m9 : 20|1@1+ (1,0) [0|0] "" Vector__XXX
 SG_ TRCM_a617_loop16AsicStartupDiagnosticFailure m10 : 20|1@1+ (1,0) [0|0] "" Vector__XXX
 SG_ TRCM_a018_asm3TemperatureOutsideOperatingRange m0 : 21|1@1+ (1,0) [0|0] "" Vector__XXX
 SG_ TRCM_a078_imuSensorSignalMonitor m1 : 21|1@1+ (1,0) [0|0] "" Vector__XXX
 SG_ TRCM_a138_ext2AsicSnoopTestFailed m2 : 21|1@1+ (1,0) [0|0] "" Vector__XXX
 SG_ TRCM_a318_outboardSeatAirbagLeftSuppressed m5 : 21|1@1+ (1,0) [0|0] "" Vector__XXX
 SG_ TRCM_a378_safingEngine14NoValidData m6 : 21|1@1+ (1,0) [0|0] "" Vector__XXX
 SG_ TRCM_a558_AlgoWake_PAS_RH_PLAUSI_REAR m9 : 21|1@1+ (1,0) [0|0] "" Vector__XXX
 SG_ TRCM_a618_loop17AsicStartupDiagnosticFailure m10 : 21|1@1+ (1,0) [0|0] "" Vector__XXX
 SG_ TRCM_a019_Task500usError m0 : 22|1@1+ (1,0) [0|0] "" Vector__XXX
 SG_ TRCM_a319_outboardSeatAirbagRightSuppressed m5 : 22|1@1+ (1,0) [0|0] "" Vector__XXX
 SG_ TRCM_a379_safingEngine15NoValidData m6 : 22|1@1+ (1,0) [0|0] "" Vector__XXX
 SG_ TRCM_a559_AlgoWake_PAS_RH_PLAUSI m9 : 22|1@1+ (1,0) [0|0] "" Vector__XXX
 SG_ TRCM_a619_loop18AsicStartupDiagnosticFailure m10 : 22|1@1+ (1,0) [0|0] "" Vector__XXX
 SG_ TRCM_a020_asm3ComStatusError m0 : 23|1@1+ (1,0) [0|0] "" Vector__XXX
 SG_ TRCM_a200_rightBPillarAccelReportedError m3 : 23|1@1+ (1,0) [0|0] "" Vector__XXX
 SG_ TRCM_a320_hoodLifterLeftSuppressed m5 : 23|1@1+ (1,0) [0|0] "" Vector__XXX
 SG_ TRCM_a380_safingEngine16NoValidData m6 : 23|1@1+ (1,0) [0|0] "" Vector__XXX
 SG_ TRCM_a440_kneeAirbagLeftConfigError m7 : 23|1@1+ (1,0) [0|0] "" Vector__XXX
 SG_ TRCM_a560_AlgoWake_RCM_WAKE_ROLL_LEFT m9 : 23|1@1+ (1,0) [0|0] "" Vector__XXX
 SG_ TRCM_a620_loop19AsicStartupDiagnosticFailure m10 : 23|1@1+ (1,0) [0|0] "" Vector__XXX
 SG_ TRCM_a021_TaskSchedulerError m0 : 24|1@1+ (1,0) [0|0] "" Vector__XXX
 SG_ TRCM_a081_powerLossDetected m1 : 24|1@1+ (1,0) [0|0] "" Vector__XXX
 SG_ TRCM_a201_rightBPillarAccelGeneralIssue m3 : 24|1@1+ (1,0) [0|0] "" Vector__XXX
 SG_ TRCM_a321_hoodLifterRightSuppressed m5 : 24|1@1+ (1,0) [0|0] "" Vector__XXX
 SG_ TRCM_a381_safingEngine17NoValidData m6 : 24|1@1+ (1,0) [0|0] "" Vector__XXX
 SG_ TRCM_a441_kneeAirbagRightConfigError m7 : 24|1@1+ (1,0) [0|0] "" Vector__XXX
 SG_ TRCM_a561_AlgoWake_RCM_WAKE_ROLL_RIGHT m9 : 24|1@1+ (1,0) [0|0] "" Vector__XXX
 SG_ TRCM_a621_loop20AsicStartupDiagnosticFailure m10 : 24|1@1+ (1,0) [0|0] "" Vector__XXX
 SG_ TRCM_a022_TaskInitError m0 : 25|1@1+ (1,0) [0|0] "" Vector__XXX
 SG_ TRCM_a082_VCRIGHT_IPC_MIA m1 : 25|1@1+ (1,0) [0|0] "" Vector__XXX
 SG_ TRCM_a202_rightBPillarAccelElectricalIssue m3 : 25|1@1+ (1,0) [0|0] "" Vector__XXX
 SG_ TRCM_a322_seatbeltShoulderPretensionerRearLeftSuppressed m5 : 25|1@1+ (1,0) [0|0] "" Vector__XXX
 SG_ TRCM_a382_safingEngine18NoValidData m6 : 25|1@1+ (1,0) [0|0] "" Vector__XXX
 SG_ TRCM_a442_curtainAirbagLeftConfigError m7 : 25|1@1+ (1,0) [0|0] "" Vector__XXX
 SG_ TRCM_a562_AlgoWake_RCM_AWAKE_FRONT m9 : 25|1@1+ (1,0) [0|0] "" Vector__XXX
 SG_ TRCM_a622_loop21AsicStartupDiagnosticFailure m10 : 25|1@1+ (1,0) [0|0] "" Vector__XXX
 SG_ TRCM_a023_asm3ArsStatusXError m0 : 26|1@1+ (1,0) [0|0] "" Vector__XXX
 SG_ TRCM_a083_VCLEFT_IPC_MIA m1 : 26|1@1+ (1,0) [0|0] "" Vector__XXX
 SG_ TRCM_a203_rightBPillarAccelConfigError m3 : 26|1@1+ (1,0) [0|0] "" Vector__XXX
 SG_ TRCM_a323_seatbeltShoulderPretensionerRearRightSuppressed m5 : 26|1@1+ (1,0) [0|0] "" Vector__XXX
 SG_ TRCM_a383_safingEngine19NoValidData m6 : 26|1@1+ (1,0) [0|0] "" Vector__XXX
 SG_ TRCM_a443_curtainAirbagRightConfigError m7 : 26|1@1+ (1,0) [0|0] "" Vector__XXX
 SG_ TRCM_a563_AlgoWake_RCM_AWAKE_REAR m9 : 26|1@1+ (1,0) [0|0] "" Vector__XXX
 SG_ TRCM_a623_loop22AsicStartupDiagnosticFailure m10 : 26|1@1+ (1,0) [0|0] "" Vector__XXX
 SG_ TRCM_a024_asm3AccStatusError m0 : 27|1@1+ (1,0) [0|0] "" Vector__XXX
 SG_ TRCM_a084_TPMS_MIA m1 : 27|1@1+ (1,0) [0|0] "" Vector__XXX
 SG_ TRCM_a204_rightBPillarAccelSignalMonitor m3 : 27|1@1+ (1,0) [0|0] "" Vector__XXX
 SG_ TRCM_a384_safingEngine20NoValidData m6 : 27|1@1+ (1,0) [0|0] "" Vector__XXX
 SG_ TRCM_a444_seatbeltLoadLimiterFrontLeftConfigError m7 : 27|1@1+ (1,0) [0|0] "" Vector__XXX
 SG_ TRCM_a564_AlgoWake_RCM_AWAKE_LEFT m9 : 27|1@1+ (1,0) [0|0] "" Vector__XXX
 SG_ TRCM_a624_loop23AsicStartupDiagnosticFailure m10 : 27|1@1+ (1,0) [0|0] "" Vector__XXX
 SG_ TRCM_a025_CHCANBusFaults m0 : 28|1@1+ (1,0) [0|0] "" Vector__XXX
 SG_ TRCM_a085_CCCM_MIA m1 : 28|1@1+ (1,0) [0|0] "" Vector__XXX
 SG_ TRCM_a145_frontCenterAccelReportedError m2 : 28|1@1+ (1,0) [0|0] "" Vector__XXX
 SG_ TRCM_a205_rightCPillarAccelReportedError m3 : 28|1@1+ (1,0) [0|0] "" Vector__XXX
 SG_ TRCM_a385_safingEngine21NoValidData m6 : 28|1@1+ (1,0) [0|0] "" Vector__XXX
 SG_ TRCM_a445_seatbeltLoadLimiterFrontRightConfigError m7 : 28|1@1+ (1,0) [0|0] "" Vector__XXX
 SG_ TRCM_a565_AlgoWake_RCM_AWAKE_RIGHT m9 : 28|1@1+ (1,0) [0|0] "" Vector__XXX
 SG_ TRCM_a625_loop24AsicStartupDiagnosticFailure m10 : 28|1@1+ (1,0) [0|0] "" Vector__XXX
 SG_ TRCM_a026_airbagAsicDiagnosticFault m0 : 29|1@1+ (1,0) [0|0] "" Vector__XXX
 SG_ TRCM_a086_VCBATT_MIA m1 : 29|1@1+ (1,0) [0|0] "" Vector__XXX
 SG_ TRCM_a146_frontCenterAccelGeneralIssue m2 : 29|1@1+ (1,0) [0|0] "" Vector__XXX
 SG_ TRCM_a206_rightCPillarAccelGeneralIssue m3 : 29|1@1+ (1,0) [0|0] "" Vector__XXX
 SG_ TRCM_a446_seatbeltShoulderPretensionerFrontLeftConfigError m7 : 29|1@1+ (1,0) [0|0] "" Vector__XXX
 SG_ TRCM_a566_AlgoWake_RCM_AWAKE_ROLL m9 : 29|1@1+ (1,0) [0|0] "" Vector__XXX
 SG_ TRCM_a626_loop25AsicStartupDiagnosticFailure m10 : 29|1@1+ (1,0) [0|0] "" Vector__XXX
 SG_ TRCM_a027_airbagAsicDeploymentDiagnosticFault m0 : 30|1@1+ (1,0) [0|0] "" Vector__XXX
 SG_ TRCM_a087_DIREL_MIA m1 : 30|1@1+ (1,0) [0|0] "" Vector__XXX
 SG_ TRCM_a147_frontCenterAccelElectricalIssue m2 : 30|1@1+ (1,0) [0|0] "" Vector__XXX
 SG_ TRCM_a207_rightCPillarAccelElectricalIssue m3 : 30|1@1+ (1,0) [0|0] "" Vector__XXX
 SG_ TRCM_a387_primaryAsicResetSource m6 : 30|1@1+ (1,0) [0|0] "" Vector__XXX
 SG_ TRCM_a447_seatbeltShoulderPretensionerFrontRightConfigError m7 : 30|1@1+ (1,0) [0|0] "" Vector__XXX
 SG_ TRCM_a567_AlgoWake_RCM_AWAKE_X m9 : 30|1@1+ (1,0) [0|0] "" Vector__XXX
 SG_ TRCM_a627_loop26AsicStartupDiagnosticFailure m10 : 30|1@1+ (1,0) [0|0] "" Vector__XXX
 SG_ TRCM_a088_DIRER_MIA m1 : 31|1@1+ (1,0) [0|0] "" Vector__XXX
 SG_ TRCM_a148_frontCenterAccelConfigError m2 : 31|1@1+ (1,0) [0|0] "" Vector__XXX
 SG_ TRCM_a208_rightCPillarAccelConfigError m3 : 31|1@1+ (1,0) [0|0] "" Vector__XXX
 SG_ TRCM_a388_cpuLoadHigh m6 : 31|1@1+ (1,0) [0|0] "" Vector__XXX
 SG_ TRCM_a448_seatbeltLapPretensionerFrontLeftConfigError m7 : 31|1@1+ (1,0) [0|0] "" Vector__XXX
 SG_ TRCM_a568_AlgoWake_RCM_AWAKE_Y m9 : 31|1@1+ (1,0) [0|0] "" Vector__XXX
 SG_ TRCM_a628_loop27AsicStartupDiagnosticFailure m10 : 31|1@1+ (1,0) [0|0] "" Vector__XXX
 SG_ TRCM_a089_IBST_MIA m1 : 32|1@1+ (1,0) [0|0] "" Vector__XXX
 SG_ TRCM_a149_frontCenterAccelSignalMonitor m2 : 32|1@1+ (1,0) [0|0] "" Vector__XXX
 SG_ TRCM_a209_rightCPillarAccelSignalMonitor m3 : 32|1@1+ (1,0) [0|0] "" Vector__XXX
 SG_ TRCM_a389_asicPwrStatusError m6 : 32|1@1+ (1,0) [0|0] "" Vector__XXX
 SG_ TRCM_a449_seatbeltLapPretensionerFrontRightConfigError m7 : 32|1@1+ (1,0) [0|0] "" Vector__XXX
 SG_ TRCM_a569_AlgoWake_PAS_WAKE_LEFT m9 : 32|1@1+ (1,0) [0|0] "" Vector__XXX
 SG_ TRCM_a629_loop28AsicStartupDiagnosticFailure m10 : 32|1@1+ (1,0) [0|0] "" Vector__XXX
 SG_ TRCM_a030_ECULogUploadRequest m0 : 33|1@1+ (1,0) [0|0] "" Vector__XXX
 SG_ TRCM_a090_APS_MIA m1 : 33|1@1+ (1,0) [0|0] "" Vector__XXX
 SG_ TRCM_a150_frontLeftAccelReportedError m2 : 33|1@1+ (1,0) [0|0] "" Vector__XXX
 SG_ TRCM_a390_systemAsicClockOrOperatingStateError m6 : 33|1@1+ (1,0) [0|0] "" Vector__XXX
 SG_ TRCM_a450_outboardSeatAirbagLeftConfigError m7 : 33|1@1+ (1,0) [0|0] "" Vector__XXX
 SG_ TRCM_a570_AlgoWake_PAS_WAKE_RIGHT m9 : 33|1@1+ (1,0) [0|0] "" Vector__XXX
 SG_ TRCM_a630_loop29AsicStartupDiagnosticFailure m10 : 33|1@1+ (1,0) [0|0] "" Vector__XXX
 SG_ TRCM_a031_UDSActive m0 : 34|1@1+ (1,0) [0|0] "" Vector__XXX
 SG_ TRCM_a091_CMPD_MIA m1 : 34|1@1+ (1,0) [0|0] "" Vector__XXX
 SG_ TRCM_a151_frontLeftAccelGeneralIssue m2 : 34|1@1+ (1,0) [0|0] "" Vector__XXX
 SG_ TRCM_a391_extAsic1ClockOrOperatingStateError m6 : 34|1@1+ (1,0) [0|0] "" Vector__XXX
 SG_ TRCM_a451_outboardSeatAirbagRightConfigError m7 : 34|1@1+ (1,0) [0|0] "" Vector__XXX
 SG_ TRCM_a631_loop30AsicStartupDiagnosticFailure m10 : 34|1@1+ (1,0) [0|0] "" Vector__XXX
 SG_ TRCM_a032_ScrollCreated m0 : 35|1@1+ (1,0) [0|0] "" Vector__XXX
 SG_ TRCM_a092_VCSEATD_MIA m1 : 35|1@1+ (1,0) [0|0] "" Vector__XXX
 SG_ TRCM_a152_frontLeftAccelElectricalIssue m2 : 35|1@1+ (1,0) [0|0] "" Vector__XXX
 SG_ TRCM_a272_asm5ComStatusError m4 : 35|1@1+ (1,0) [0|0] "" Vector__XXX
 SG_ TRCM_a332_driverAirbagStage1Deployed m5 : 35|1@1+ (1,0) [0|0] "" Vector__XXX
 SG_ TRCM_a392_extAsic2ClockOrOperatingStateError m6 : 35|1@1+ (1,0) [0|0] "" Vector__XXX
 SG_ TRCM_a452_hoodLifterLeftConfigError m7 : 35|1@1+ (1,0) [0|0] "" Vector__XXX
 SG_ TRCM_a632_loop31AsicStartupDiagnosticFailure m10 : 35|1@1+ (1,0) [0|0] "" Vector__XXX
 SG_ TRCM_a033_HercLogCreated m0 : 36|1@1+ (1,0) [0|0] "" Vector__XXX
 SG_ TRCM_a093_VCSEATP_MIA m1 : 36|1@1+ (1,0) [0|0] "" Vector__XXX
 SG_ TRCM_a153_frontLeftAccelConfigError m2 : 36|1@1+ (1,0) [0|0] "" Vector__XXX
 SG_ TRCM_a273_asm5ArsStatusXError m4 : 36|1@1+ (1,0) [0|0] "" Vector__XXX
 SG_ TRCM_a333_passengerAirbagStage1Deployed m5 : 36|1@1+ (1,0) [0|0] "" Vector__XXX
 SG_ TRCM_a393_depAdcConvertRatioError m6 : 36|1@1+ (1,0) [0|0] "" Vector__XXX
 SG_ TRCM_a453_hoodLifterRightConfigError m7 : 36|1@1+ (1,0) [0|0] "" Vector__XXX
 SG_ TRCM_a633_glacierInitialStatusFailure m10 : 36|1@1+ (1,0) [0|0] "" Vector__XXX
 SG_ TRCM_a034_apClipTrigger m0 : 37|1@1+ (1,0) [0|0] "" Vector__XXX
 SG_ TRCM_a094_EPAS3P_MIA m1 : 37|1@1+ (1,0) [0|0] "" Vector__XXX
 SG_ TRCM_a154_frontLeftAccelSignalMonitor m2 : 37|1@1+ (1,0) [0|0] "" Vector__XXX
 SG_ TRCM_a274_asm5ArsStatusZError m4 : 37|1@1+ (1,0) [0|0] "" Vector__XXX
 SG_ TRCM_a334_driverAirbagStage2Deployed m5 : 37|1@1+ (1,0) [0|0] "" Vector__XXX
 SG_ TRCM_a394_gspiGlobalStatusWordError m6 : 37|1@1+ (1,0) [0|0] "" Vector__XXX
 SG_ TRCM_a454_seatbeltShoulderPretensionerRearLeftConfigError m7 : 37|1@1+ (1,0) [0|0] "" Vector__XXX
 SG_ TRCM_a634_glacierTraceabilityReadoutA0A0Failure m10 : 37|1@1+ (1,0) [0|0] "" Vector__XXX
 SG_ TRCM_a035_hvDisconnectCommanded m0 : 38|1@1+ (1,0) [0|0] "" Vector__XXX
 SG_ TRCM_a095_CHG_MIA m1 : 38|1@1+ (1,0) [0|0] "" Vector__XXX
 SG_ TRCM_a155_frontLeftDoorPressureReportedError m2 : 38|1@1+ (1,0) [0|0] "" Vector__XXX
 SG_ TRCM_a275_asm5AccStatusError m4 : 38|1@1+ (1,0) [0|0] "" Vector__XXX
 SG_ TRCM_a335_driverAirbagActiveVentDeployed m5 : 38|1@1+ (1,0) [0|0] "" Vector__XXX
 SG_ TRCM_a395_imuUncalibrated m6 : 38|1@1+ (1,0) [0|0] "" Vector__XXX
 SG_ TRCM_a455_seatbeltShoulderPretensionerRearRightConfigError m7 : 38|1@1+ (1,0) [0|0] "" Vector__XXX
 SG_ TRCM_a635_glacierTraceabilityReadoutB0B0Failure m10 : 38|1@1+ (1,0) [0|0] "" Vector__XXX
 SG_ TRCM_a036_crashDetected m0 : 39|1@1+ (1,0) [0|0] "" Vector__XXX
 SG_ TRCM_a096_OCS1P_MIA m1 : 39|1@1+ (1,0) [0|0] "" Vector__XXX
 SG_ TRCM_a156_frontLeftDoorPressureGeneralIssue m2 : 39|1@1+ (1,0) [0|0] "" Vector__XXX
 SG_ TRCM_a276_watchdogStatus m4 : 39|1@1+ (1,0) [0|0] "" Vector__XXX
 SG_ TRCM_a336_passengerAirbagStage2Deployed m5 : 39|1@1+ (1,0) [0|0] "" Vector__XXX
 SG_ TRCM_a396_spiCommunicationProgramError m6 : 39|1@1+ (1,0) [0|0] "" Vector__XXX
 SG_ TRCM_a576_AlgoWake_IMPACT_FINISH_X m9 : 39|1@1+ (1,0) [0|0] "" Vector__XXX
 SG_ TRCM_a636_glacierRegisterPatternWriteFailure m10 : 39|1@1+ (1,0) [0|0] "" Vector__XXX
 SG_ TRCM_a037_nearDeploy m0 : 40|1@1+ (1,0) [0|0] "" Vector__XXX
 SG_ TRCM_a097_CMP_MIA m1 : 40|1@1+ (1,0) [0|0] "" Vector__XXX
 SG_ TRCM_a157_frontLeftDoorPressureElectricalIssue m2 : 40|1@1+ (1,0) [0|0] "" Vector__XXX
 SG_ TRCM_a337_passengerAirbagActiveVentDeployed m5 : 40|1@1+ (1,0) [0|0] "" Vector__XXX
 SG_ TRCM_a397_safingMonitorError m6 : 40|1@1+ (1,0) [0|0] "" Vector__XXX
 SG_ TRCM_a577_AlgoWake_IMPACT_FINISH_Y m9 : 40|1@1+ (1,0) [0|0] "" Vector__XXX
 SG_ TRCM_a637_glacierFixedPatternSelfTestFailure m10 : 40|1@1+ (1,0) [0|0] "" Vector__XXX
 SG_ TRCM_a038_ens1Degraded m0 : 41|1@1+ (1,0) [0|0] "" Vector__XXX
 SG_ TRCM_a098_DIR_MIA m1 : 41|1@1+ (1,0) [0|0] "" Vector__XXX
 SG_ TRCM_a158_frontLeftDoorPressureConfigError m2 : 41|1@1+ (1,0) [0|0] "" Vector__XXX
 SG_ TRCM_a278_safingEngine0Armed m4 : 41|1@1+ (1,0) [0|0] "" Vector__XXX
 SG_ TRCM_a398_asicNvmReprogrammed m6 : 41|1@1+ (1,0) [0|0] "" Vector__XXX
 SG_ TRCM_a578_AlgoWake_IMPACT_FINISH_ROLL m9 : 41|1@1+ (1,0) [0|0] "" Vector__XXX
 SG_ TRCM_a638_glacierSelfTestEFailure m10 : 41|1@1+ (1,0) [0|0] "" Vector__XXX
 SG_ TRCM_a039_ens2Degraded m0 : 42|1@1+ (1,0) [0|0] "" Vector__XXX
 SG_ TRCM_a099_PARK_MIA m1 : 42|1@1+ (1,0) [0|0] "" Vector__XXX
 SG_ TRCM_a159_frontLeftDoorPressureSignalMonitor m2 : 42|1@1+ (1,0) [0|0] "" Vector__XXX
 SG_ TRCM_a279_safingEngine1Armed m4 : 42|1@1+ (1,0) [0|0] "" Vector__XXX
 SG_ TRCM_a579_AlgoWake_RCM_ENABLED_X m9 : 42|1@1+ (1,0) [0|0] "" Vector__XXX
 SG_ TRCM_a639_glacierSelfTestFFailure m10 : 42|1@1+ (1,0) [0|0] "" Vector__XXX
 SG_ TRCM_a040_task500usOverrunDebug m0 : 43|1@1+ (1,0) [0|0] "" Vector__XXX
 SG_ TRCM_a100_CANbus_MIA m1 : 43|1@1+ (1,0) [0|0] "" Vector__XXX
 SG_ TRCM_a160_frontRightAccelReportedError m2 : 43|1@1+ (1,0) [0|0] "" Vector__XXX
 SG_ TRCM_a280_safingEngine2Armed m4 : 43|1@1+ (1,0) [0|0] "" Vector__XXX
 SG_ TRCM_a340_kneeAirbagLeftDeployed m5 : 43|1@1+ (1,0) [0|0] "" Vector__XXX
 SG_ TRCM_a400_driverAirbagStage1Issue m6 : 43|1@1+ (1,0) [0|0] "" Vector__XXX
 SG_ TRCM_a580_AlgoWake_RCM_ENABLED_Y m9 : 43|1@1+ (1,0) [0|0] "" Vector__XXX
 SG_ TRCM_a640_glacierAnalogSelfTestFailure m10 : 43|1@1+ (1,0) [0|0] "" Vector__XXX
 SG_ TRCM_a041_HighCPULoad m0 : 44|1@1+ (1,0) [0|0] "" Vector__XXX
 SG_ TRCM_a101_PM_MIA m1 : 44|1@1+ (1,0) [0|0] "" Vector__XXX
 SG_ TRCM_a161_frontRightAccelGeneralIssue m2 : 44|1@1+ (1,0) [0|0] "" Vector__XXX
 SG_ TRCM_a281_safingEngine3Armed m4 : 44|1@1+ (1,0) [0|0] "" Vector__XXX
 SG_ TRCM_a341_kneeAirbagRightDeployed m5 : 44|1@1+ (1,0) [0|0] "" Vector__XXX
 SG_ TRCM_a401_passengerAirbagStage1Issue m6 : 44|1@1+ (1,0) [0|0] "" Vector__XXX
 SG_ TRCM_a581_AlgoWake_RCM_ENABLED_ROLL m9 : 44|1@1+ (1,0) [0|0] "" Vector__XXX
 SG_ TRCM_a641_glacierOscillatorVerificationFailure m10 : 44|1@1+ (1,0) [0|0] "" Vector__XXX
 SG_ TRCM_a042_HighStackUsage m0 : 45|1@1+ (1,0) [0|0] "" Vector__XXX
 SG_ TRCM_a102_PTC_MIA m1 : 45|1@1+ (1,0) [0|0] "" Vector__XXX
 SG_ TRCM_a162_frontRightAccelElectricalIssue m2 : 45|1@1+ (1,0) [0|0] "" Vector__XXX
 SG_ TRCM_a282_safingEngine4Armed m4 : 45|1@1+ (1,0) [0|0] "" Vector__XXX
 SG_ TRCM_a342_curtainAirbagLeftDeployed m5 : 45|1@1+ (1,0) [0|0] "" Vector__XXX
 SG_ TRCM_a402_driverAirbagStage2Issue m6 : 45|1@1+ (1,0) [0|0] "" Vector__XXX
 SG_ TRCM_a582_AlgoWake_RCM_AWAKE m9 : 45|1@1+ (1,0) [0|0] "" Vector__XXX
 SG_ TRCM_a642_glacierFinalStatusFailure m10 : 45|1@1+ (1,0) [0|0] "" Vector__XXX
 SG_ TRCM_a043_Task1msError m0 : 46|1@1+ (1,0) [0|0] "" Vector__XXX
 SG_ TRCM_a103_CP_MIA m1 : 46|1@1+ (1,0) [0|0] "" Vector__XXX
 SG_ TRCM_a163_frontRightAccelConfigError m2 : 46|1@1+ (1,0) [0|0] "" Vector__XXX
 SG_ TRCM_a283_safingEngine5Armed m4 : 46|1@1+ (1,0) [0|0] "" Vector__XXX
 SG_ TRCM_a343_curtainAirbagRightDeployed m5 : 46|1@1+ (1,0) [0|0] "" Vector__XXX
 SG_ TRCM_a403_driverAirbagActiveVentIssue m6 : 46|1@1+ (1,0) [0|0] "" Vector__XXX
 SG_ TRCM_a643_glacierOffsetVerificationFailure m10 : 46|1@1+ (1,0) [0|0] "" Vector__XXX
 SG_ TRCM_a044_Task10msError m0 : 47|1@1+ (1,0) [0|0] "" Vector__XXX
 SG_ TRCM_a104_DAS_MIA m1 : 47|1@1+ (1,0) [0|0] "" Vector__XXX
 SG_ TRCM_a164_frontRightAccelSignalMonitor m2 : 47|1@1+ (1,0) [0|0] "" Vector__XXX
 SG_ TRCM_a284_safingEngine6Armed m4 : 47|1@1+ (1,0) [0|0] "" Vector__XXX
 SG_ TRCM_a344_seatbeltLoadLimiterFrontLeftDeployed m5 : 47|1@1+ (1,0) [0|0] "" Vector__XXX
 SG_ TRCM_a404_passengerAirbagStage2Issue m6 : 47|1@1+ (1,0) [0|0] "" Vector__XXX
 SG_ TRCM_a644_glacierNormalOperationFailure m10 : 47|1@1+ (1,0) [0|0] "" Vector__XXX
 SG_ TRCM_a045_Task100msError m0 : 48|1@1+ (1,0) [0|0] "" Vector__XXX
 SG_ TRCM_a105_TAS_MIA m1 : 48|1@1+ (1,0) [0|0] "" Vector__XXX
 SG_ TRCM_a165_frontRightDoorPressureReportedError m2 : 48|1@1+ (1,0) [0|0] "" Vector__XXX
 SG_ TRCM_a285_safingEngine7Armed m4 : 48|1@1+ (1,0) [0|0] "" Vector__XXX
 SG_ TRCM_a345_seatbeltLoadLimiterFrontRightDeployed m5 : 48|1@1+ (1,0) [0|0] "" Vector__XXX
 SG_ TRCM_a405_passengerAirbagActiveVentIssue m6 : 48|1@1+ (1,0) [0|0] "" Vector__XXX
 SG_ TRCM_a645_glacierDeviceReset m10 : 48|1@1+ (1,0) [0|0] "" Vector__XXX
 SG_ TRCM_a046_Task1000msError m0 : 49|1@1+ (1,0) [0|0] "" Vector__XXX
 SG_ TRCM_a106_PCS_MIA m1 : 49|1@1+ (1,0) [0|0] "" Vector__XXX
 SG_ TRCM_a166_frontRightDoorPressureGeneralIssue m2 : 49|1@1+ (1,0) [0|0] "" Vector__XXX
 SG_ TRCM_a286_safingEngine8Armed m4 : 49|1@1+ (1,0) [0|0] "" Vector__XXX
 SG_ TRCM_a346_seatbeltShoulderPretensionerFrontLeftDeployed m5 : 49|1@1+ (1,0) [0|0] "" Vector__XXX
 SG_ TRCM_a646_glacierDeviceFaulted m10 : 49|1@1+ (1,0) [0|0] "" Vector__XXX
 SG_ TRCM_a047_vinNotLearned m0 : 50|1@1+ (1,0) [0|0] "" Vector__XXX
 SG_ TRCM_a107_BMS_MIA m1 : 50|1@1+ (1,0) [0|0] "" Vector__XXX
 SG_ TRCM_a167_frontRightDoorPressureElectricalIssue m2 : 50|1@1+ (1,0) [0|0] "" Vector__XXX
 SG_ TRCM_a287_safingEngine9Armed m4 : 50|1@1+ (1,0) [0|0] "" Vector__XXX
 SG_ TRCM_a347_seatbeltShoulderPretensionerFrontRightDeployed m5 : 50|1@1+ (1,0) [0|0] "" Vector__XXX
 SG_ TRCM_a048_vinMismatch m0 : 51|1@1+ (1,0) [0|0] "" Vector__XXX
 SG_ TRCM_a108_DIF_MIA m1 : 51|1@1+ (1,0) [0|0] "" Vector__XXX
 SG_ TRCM_a168_frontRightDoorPressureConfigError m2 : 51|1@1+ (1,0) [0|0] "" Vector__XXX
 SG_ TRCM_a288_safingEngine10Armed m4 : 51|1@1+ (1,0) [0|0] "" Vector__XXX
 SG_ TRCM_a348_seatbeltLapPretensionerFrontLeftDeployed m5 : 51|1@1+ (1,0) [0|0] "" Vector__XXX
 SG_ TRCM_a408_kneeAirbagLeftIssue m6 : 51|1@1+ (1,0) [0|0] "" Vector__XXX
 SG_ TRCM_a588_yawRateOffsetPosLimit m9 : 51|1@1+ (1,0) [0|0] "" Vector__XXX
 SG_ TRCM_a049_nvmDebugInfo m0 : 52|1@1+ (1,0) [0|0] "" Vector__XXX
 SG_ TRCM_a109_RCM_MIA m1 : 52|1@1+ (1,0) [0|0] "" Vector__XXX
 SG_ TRCM_a169_frontRightDoorPressureSignalMonitor m2 : 52|1@1+ (1,0) [0|0] "" Vector__XXX
 SG_ TRCM_a289_safingEngine11Armed m4 : 52|1@1+ (1,0) [0|0] "" Vector__XXX
 SG_ TRCM_a349_seatbeltLapPretensionerFrontRightDeployed m5 : 52|1@1+ (1,0) [0|0] "" Vector__XXX
 SG_ TRCM_a409_kneeAirbagRightIssue m6 : 52|1@1+ (1,0) [0|0] "" Vector__XXX
 SG_ TRCM_a589_yawRateOffsetNegLimit m9 : 52|1@1+ (1,0) [0|0] "" Vector__XXX
 SG_ TRCM_a110_GTW_MIA m1 : 53|1@1+ (1,0) [0|0] "" Vector__XXX
 SG_ TRCM_a170_leftBPillarAccelReportedError m2 : 53|1@1+ (1,0) [0|0] "" Vector__XXX
 SG_ TRCM_a290_safingEngine12Armed m4 : 53|1@1+ (1,0) [0|0] "" Vector__XXX
 SG_ TRCM_a350_outboardSeatAirbagLeftDeployed m5 : 53|1@1+ (1,0) [0|0] "" Vector__XXX
 SG_ TRCM_a410_curtainAirbagLeftIssue m6 : 53|1@1+ (1,0) [0|0] "" Vector__XXX
 SG_ TRCM_a590_pitchRateOffsetPosLimit m9 : 53|1@1+ (1,0) [0|0] "" Vector__XXX
 SG_ TRCM_a051_systemSelfTestTimeout m0 : 54|1@1+ (1,0) [0|0] "" Vector__XXX
 SG_ TRCM_a111_EPBR_MIA m1 : 54|1@1+ (1,0) [0|0] "" Vector__XXX
 SG_ TRCM_a171_leftBPillarAccelGeneralIssue m2 : 54|1@1+ (1,0) [0|0] "" Vector__XXX
 SG_ TRCM_a291_safingEngine13Armed m4 : 54|1@1+ (1,0) [0|0] "" Vector__XXX
 SG_ TRCM_a351_outboardSeatAirbagRightDeployed m5 : 54|1@1+ (1,0) [0|0] "" Vector__XXX
 SG_ TRCM_a411_curtainAirbagRightIssue m6 : 54|1@1+ (1,0) [0|0] "" Vector__XXX
 SG_ TRCM_a591_pitchRateOffsetNegLimit m9 : 54|1@1+ (1,0) [0|0] "" Vector__XXX
 SG_ TRCM_a112_EPBL_MIA m1 : 55|1@1+ (1,0) [0|0] "" Vector__XXX
 SG_ TRCM_a172_leftBPillarAccelElectricalIssue m2 : 55|1@1+ (1,0) [0|0] "" Vector__XXX
 SG_ TRCM_a292_safingEngine14Armed m4 : 55|1@1+ (1,0) [0|0] "" Vector__XXX
 SG_ TRCM_a352_hoodLifterLeftDeployed m5 : 55|1@1+ (1,0) [0|0] "" Vector__XXX
 SG_ TRCM_a412_seatbeltLoadLimiterFrontLeftIssue m6 : 55|1@1+ (1,0) [0|0] "" Vector__XXX
 SG_ TRCM_a592_rollRateOffsetPosLimit m9 : 55|1@1+ (1,0) [0|0] "" Vector__XXX
 SG_ TRCM_a113_UI_MIA m1 : 56|1@1+ (1,0) [0|0] "" Vector__XXX
 SG_ TRCM_a173_leftBPillarAccelConfigError m2 : 56|1@1+ (1,0) [0|0] "" Vector__XXX
 SG_ TRCM_a293_safingEngine15Armed m4 : 56|1@1+ (1,0) [0|0] "" Vector__XXX
 SG_ TRCM_a353_hoodLifterRightDeployed m5 : 56|1@1+ (1,0) [0|0] "" Vector__XXX
 SG_ TRCM_a413_seatbeltLoadLimiterFrontRightIssue m6 : 56|1@1+ (1,0) [0|0] "" Vector__XXX
 SG_ TRCM_a593_rollRateOffsetNegLimit m9 : 56|1@1+ (1,0) [0|0] "" Vector__XXX
 SG_ TRCM_a114_ESP_MIA m1 : 57|1@1+ (1,0) [0|0] "" Vector__XXX
 SG_ TRCM_a174_leftBPillarAccelSignalMonitor m2 : 57|1@1+ (1,0) [0|0] "" Vector__XXX
 SG_ TRCM_a294_safingEngine16Armed m4 : 57|1@1+ (1,0) [0|0] "" Vector__XXX
 SG_ TRCM_a354_seatbeltShoulderPretensionerRearLeftDeployed m5 : 57|1@1+ (1,0) [0|0] "" Vector__XXX
 SG_ TRCM_a414_seatbeltShoulderPretensionerFrontLeftIssue m6 : 57|1@1+ (1,0) [0|0] "" Vector__XXX
 SG_ TRCM_a594_longitudinalAccelOffsetPosLimit m9 : 57|1@1+ (1,0) [0|0] "" Vector__XXX
 SG_ TRCM_a115_VCSEC_MIA m1 : 58|1@1+ (1,0) [0|0] "" Vector__XXX
 SG_ TRCM_a175_leftCPillarAccelReportedError m2 : 58|1@1+ (1,0) [0|0] "" Vector__XXX
 SG_ TRCM_a295_safingEngine17Armed m4 : 58|1@1+ (1,0) [0|0] "" Vector__XXX
 SG_ TRCM_a355_seatbeltShoulderPretensionerRearRightDeployed m5 : 58|1@1+ (1,0) [0|0] "" Vector__XXX
 SG_ TRCM_a415_seatbeltShoulderPretensionerFrontRightIssue m6 : 58|1@1+ (1,0) [0|0] "" Vector__XXX
 SG_ TRCM_a595_longitudinalAccelOffsetNegLimit m9 : 58|1@1+ (1,0) [0|0] "" Vector__XXX
 SG_ TRCM_a116_VCRIGHT_MIA m1 : 59|1@1+ (1,0) [0|0] "" Vector__XXX
 SG_ TRCM_a176_leftCPillarAccelGeneralIssue m2 : 59|1@1+ (1,0) [0|0] "" Vector__XXX
 SG_ TRCM_a296_safingEngine18Armed m4 : 59|1@1+ (1,0) [0|0] "" Vector__XXX
 SG_ TRCM_a416_seatbeltLapPretensionerFrontLeftIssue m6 : 59|1@1+ (1,0) [0|0] "" Vector__XXX
 SG_ TRCM_a596_lateralAccelOffsetPosLimit m9 : 59|1@1+ (1,0) [0|0] "" Vector__XXX
 SG_ TRCM_a057_HVP_MIA m0 : 60|1@1+ (1,0) [0|0] "" Vector__XXX
 SG_ TRCM_a117_VCLEFT_MIA m1 : 60|1@1+ (1,0) [0|0] "" Vector__XXX
 SG_ TRCM_a177_leftCPillarAccelElectricalIssue m2 : 60|1@1+ (1,0) [0|0] "" Vector__XXX
 SG_ TRCM_a297_safingEngine19Armed m4 : 60|1@1+ (1,0) [0|0] "" Vector__XXX
 SG_ TRCM_a417_seatbeltLapPretensionerFrontRightIssue m6 : 60|1@1+ (1,0) [0|0] "" Vector__XXX
 SG_ TRCM_a597_lateralAccelOffsetNegLimit m9 : 60|1@1+ (1,0) [0|0] "" Vector__XXX
 SG_ TRCM_a058_inputRHighSyncDebug m0 : 61|1@1+ (1,0) [0|0] "" Vector__XXX
 SG_ TRCM_a118_VCFRONT_MIA m1 : 61|1@1+ (1,0) [0|0] "" Vector__XXX
 SG_ TRCM_a178_leftCPillarAccelConfigError m2 : 61|1@1+ (1,0) [0|0] "" Vector__XXX
 SG_ TRCM_a298_safingEngine20Armed m4 : 61|1@1+ (1,0) [0|0] "" Vector__XXX
 SG_ TRCM_a418_outboardSeatAirbagLeftIssue m6 : 61|1@1+ (1,0) [0|0] "" Vector__XXX
 SG_ TRCM_a598_verticalAccelOffsetPosLimit m9 : 61|1@1+ (1,0) [0|0] "" Vector__XXX
 SG_ TRCM_a059_inputResistanceHigh m0 : 62|1@1+ (1,0) [0|0] "" Vector__XXX
 SG_ TRCM_a119_SCCM_MIA m1 : 62|1@1+ (1,0) [0|0] "" Vector__XXX
 SG_ TRCM_a179_leftCPillarAccelSignalMonitor m2 : 62|1@1+ (1,0) [0|0] "" Vector__XXX
 SG_ TRCM_a299_safingEngine21Armed m4 : 62|1@1+ (1,0) [0|0] "" Vector__XXX
 SG_ TRCM_a419_outboardSeatAirbagRightIssue m6 : 62|1@1+ (1,0) [0|0] "" Vector__XXX
 SG_ TRCM_a599_verticalAccelOffsetNegLimit m9 : 62|1@1+ (1,0) [0|0] "" Vector__XXX
 SG_ TRCM_a060_engineeringBuild m0 : 63|1@1+ (1,0) [0|0] "" Vector__XXX
 SG_ TRCM_a120_DI_DRIVE_MIA m1 : 63|1@1+ (1,0) [0|0] "" Vector__XXX
 SG_ TRCM_a300_driverAirbagStage1Suppressed m4 : 63|1@1+ (1,0) [0|0] "" Vector__XXX
 SG_ TRCM_a420_hoodLifterLeftIssue m6 : 63|1@1+ (1,0) [0|0] "" Vector__XXX
 SG_ TRCM_a600_airbagAsicStartupFailure m9 : 63|1@1+ (1,0) [0|0] "" Vector__XXX

BO_ 890 DAS_telemetryPeriodic: 8 Vector__XXX
 SG_ DAS_TP_multiplexer M : 0|5@1+ (1,0) [0|0] "" Vector__XXX
 SG_ DAS_TP_bdlCounter m6 : 5|3@1+ (1,0) [0|0] "" Vector__XXX
 SG_ DAS_TP_bdrCounter m7 : 5|3@1+ (1,0) [0|0] "" Vector__XXX
 SG_ DAS_TP_counter m0 : 5|3@1+ (1,0) [0|0] "" Vector__XXX
 SG_ DAS_TP_hppCounter m3 : 5|3@1+ (1,0) [0|0] "" Vector__XXX
 SG_ DAS_TP_laneCounter m8 : 5|3@1+ (1,0) [0|0] "" Vector__XXX
 SG_ DAS_TP_llCounter m1 : 5|3@1+ (1,0) [0|0] "" Vector__XXX
 SG_ DAS_TP_llrCounter m9 : 5|3@1+ (1,0) [0|0] "" Vector__XXX
 SG_ DAS_TP_navCounter m4 : 5|3@1+ (1,0) [0|0] "" Vector__XXX
 SG_ DAS_TP_rlCounter m2 : 5|3@1+ (1,0) [0|0] "" Vector__XXX
 SG_ DAS_TP_vlCounter m5 : 5|3@1+ (1,0) [0|0] "" Vector__XXX
 SG_ DAS_TP_bdlC0 m6 : 8|10@1- (0.02,0) [0|0] "" Vector__XXX
 SG_ DAS_TP_bdrC0 m7 : 8|10@1- (0.02,0) [0|0] "" Vector__XXX
 SG_ DAS_TP_hppC0 m3 : 8|10@1- (0.02,0) [0|0] "" Vector__XXX
 SG_ DAS_TP_llC0 m1 : 8|10@1- (0.02,0) [0|0] "" Vector__XXX
 SG_ DAS_TP_llSegQ1 m8 : 8|4@1+ (10,0) [0|0] "" Vector__XXX
 SG_ DAS_TP_navC0 m4 : 8|10@1- (0.02,0) [0|0] "" Vector__XXX
 SG_ DAS_TP_numLanes m9 : 8|3@1+ (1,0) [0|0] "" Vector__XXX
 SG_ DAS_TP_rlC0 m2 : 8|10@1- (0.02,0) [0|0] "" Vector__XXX
 SG_ DAS_TP_vlC0 m5 : 8|10@1- (0.02,0) [0|0] "" Vector__XXX
 SG_ DAS_TP_vlWidth m0 : 8|8@1+ (0.05,0) [0|0] "" Vector__XXX
 SG_ DAS_TP_lane1LLR m9 : 11|6@1+ (0.3125,-10) [0|0] "" Vector__XXX
 SG_ DAS_TP_llSegQ2 m8 : 12|4@1+ (10,0) [0|0] "" Vector__XXX
 SG_ DAS_TP_hppError m0 : 16|6@1+ (0.05,0) [0|0] "" Vector__XXX
 SG_ DAS_TP_llSegQ3 m8 : 16|4@1+ (10,0) [0|0] "" Vector__XXX
 SG_ DAS_TP_lane2LLR m9 : 17|6@1+ (0.3125,-10) [0|0] "" Vector__XXX
 SG_ DAS_TP_bdlC1 m6 : 18|9@1- (0.001953125,0) [0|0] "" Vector__XXX
 SG_ DAS_TP_bdrC1 m7 : 18|9@1- (0.001953125,0) [0|0] "" Vector__XXX
 SG_ DAS_TP_hppC1 m3 : 18|9@1- (0.001953125,0) [0|0] "" Vector__XXX
 SG_ DAS_TP_llC1 m1 : 18|9@1- (0.001953125,0) [0|0] "" Vector__XXX
 SG_ DAS_TP_navC1 m4 : 18|9@1- (0.001953125,0) [0|0] "" Vector__XXX
 SG_ DAS_TP_rlC1 m2 : 18|9@1- (0.001953125,0) [0|0] "" Vector__XXX
 SG_ DAS_TP_vlC1 m5 : 18|9@1- (0.001953125,0) [0|0] "" Vector__XXX
 SG_ DAS_TP_llSegQ4 m8 : 20|4@1+ (10,0) [0|0] "" Vector__XXX
 SG_ DAS_TP_wipersActive m0 : 22|1@1+ (1,0) [0|0] "" Vector__XXX
 SG_ DAS_TP_handsOn m0 : 23|1@1+ (1,0) [0|0] "" Vector__XXX
 SG_ DAS_TP_lane3LLR m9 : 23|6@1+ (0.3125,-10) [0|0] "" Vector__XXX
 SG_ DAS_TP_rlSegQ1 m8 : 24|4@1+ (10,0) [0|0] "" Vector__XXX
 SG_ DAS_TP_sonicDistL m0 : 24|9@1+ (0.01,0) [0|0] "" Vector__XXX
 SG_ DAS_TP_bdlC2 m6 : 27|14@1- (4e-06,0) [0|0] "" Vector__XXX
 SG_ DAS_TP_bdrC2 m7 : 27|14@1- (4e-06,0) [0|0] "" Vector__XXX
 SG_ DAS_TP_hppC2 m3 : 27|14@1- (4e-06,0) [0|0] "" Vector__XXX
 SG_ DAS_TP_llC2 m1 : 27|14@1- (4e-06,0) [0|0] "" Vector__XXX
 SG_ DAS_TP_navC2 m4 : 27|14@1- (4e-06,0) [0|0] "" Vector__XXX
 SG_ DAS_TP_rlC2 m2 : 27|14@1- (4e-06,0) [0|0] "" Vector__XXX
 SG_ DAS_TP_vlC2 m5 : 27|14@1- (4e-06,0) [0|0] "" Vector__XXX
 SG_ DAS_TP_rlSegQ2 m8 : 28|4@1+ (10,0) [0|0] "" Vector__XXX
 SG_ DAS_TP_lane4LLR m9 : 29|6@1+ (0.3125,-10) [0|0] "" Vector__XXX
 SG_ DAS_TP_rlSegQ3 m8 : 32|4@1+ (10,0) [0|0] "" Vector__XXX
 SG_ DAS_TP_sonicDistR m0 : 33|9@1+ (0.01,0) [0|0] "" Vector__XXX
 SG_ DAS_TP_lane5LLR m9 : 35|6@1+ (0.3125,-10) [0|0] "" Vector__XXX
 SG_ DAS_TP_rlSegQ4 m8 : 36|4@1+ (10,0) [0|0] "" Vector__XXX
 SG_ DAS_TP_llExist m8 : 40|4@1+ (10,0) [0|0] "" Vector__XXX
 SG_ DAS_TP_bdlC3 m6 : 41|14@1- (1.6e-08,0) [0|0] "" Vector__XXX
 SG_ DAS_TP_bdrC3 m7 : 41|14@1- (1.6e-08,0) [0|0] "" Vector__XXX
 SG_ DAS_TP_hppC3 m3 : 41|14@1- (1.6e-08,0) [0|0] "" Vector__XXX
 SG_ DAS_TP_lane6LLR m9 : 41|6@1+ (0.3125,-10) [0|0] "" Vector__XXX
 SG_ DAS_TP_llC3 m1 : 41|14@1- (1.6e-08,0) [0|0] "" Vector__XXX
 SG_ DAS_TP_navC3 m4 : 41|14@1- (1.6e-08,0) [0|0] "" Vector__XXX
 SG_ DAS_TP_rlC3 m2 : 41|14@1- (1.6e-08,0) [0|0] "" Vector__XXX
 SG_ DAS_TP_vlC3 m5 : 41|14@1- (1.6e-08,0) [0|0] "" Vector__XXX
 SG_ DAS_TP_hppValid m0 : 42|1@1+ (1,0) [0|0] "" Vector__XXX
 SG_ DAS_TP_restrictedAccess m0 : 43|1@1+ (1,0) [0|0] "" Vector__XXX
 SG_ DAS_TP_rlExist m8 : 44|4@1+ (10,0) [0|0] "" Vector__XXX
 SG_ DAS_TP_vehFuse m0 : 44|1@1+ (1,0) [0|0] "" Vector__XXX
 SG_ DAS_TP_accRestricted m0 : 46|1@1+ (1,0) [0|0] "" Vector__XXX
 SG_ DAS_TP_lane7LLR m9 : 47|6@1+ (0.3125,-10) [0|0] "" Vector__XXX
 SG_ DAS_TP_laneChange m0 : 48|2@1+ (1,0) [0|0] "" Vector__XXX
 SG_ DAS_TP_nllProb m8 : 48|4@1+ (0.1,0) [0|0] "" Vector__XXX
 SG_ DAS_TP_llType m0 : 50|3@1+ (1,0) [0|0] "" Vector__XXX
 SG_ DAS_TP_nrlProb m8 : 52|4@1+ (0.1,0) [0|0] "" Vector__XXX
 SG_ DAS_TP_lane8LLR m9 : 53|6@1+ (0.3125,-10) [0|0] "" Vector__XXX
 SG_ DAS_TP_rlType m0 : 53|3@1+ (1,0) [0|0] "" Vector__XXX
 SG_ DAS_TP_bdlQlty m6 : 55|1@1+ (1,0) [0|0] "" Vector__XXX
 SG_ DAS_TP_bdrQlty m7 : 55|1@1+ (1,0) [0|0] "" Vector__XXX
 SG_ DAS_TP_hppQlty m3 : 55|1@1+ (1,0) [0|0] "" Vector__XXX
 SG_ DAS_TP_llQlty m1 : 55|1@1+ (1,0) [0|0] "" Vector__XXX
 SG_ DAS_TP_navQlty m4 : 55|1@1+ (1,0) [0|0] "" Vector__XXX
 SG_ DAS_TP_rlQlty m2 : 55|1@1+ (1,0) [0|0] "" Vector__XXX
 SG_ DAS_TP_vlQlty m5 : 55|1@1+ (1,0) [0|0] "" Vector__XXX
 SG_ DAS_TP_bdlRange m6 : 56|7@1+ (1,0) [0|0] "" Vector__XXX
 SG_ DAS_TP_bdrRange m7 : 56|7@1+ (1,0) [0|0] "" Vector__XXX
 SG_ DAS_TP_hppRange m3 : 56|7@1+ (1,0) [0|0] "" Vector__XXX
 SG_ DAS_TP_llQltyME m8 : 56|2@1+ (1,0) [0|0] "" Vector__XXX
 SG_ DAS_TP_llRange m1 : 56|7@1+ (1,0) [0|0] "" Vector__XXX
 SG_ DAS_TP_navRange m4 : 56|7@1+ (1,0) [0|0] "" Vector__XXX
 SG_ DAS_TP_plannerState m0 : 56|4@1+ (1,0) [0|0] "" Vector__XXX
 SG_ DAS_TP_rlRange m2 : 56|7@1+ (1,0) [0|0] "" Vector__XXX
 SG_ DAS_TP_vlRange m5 : 56|7@1+ (1,0) [0|0] "" Vector__XXX
 SG_ DAS_TP_rlQltyME m8 : 58|2@1+ (1,0) [0|0] "" Vector__XXX
 SG_ DAS_TP_egoLane m9 : 59|3@1+ (1,0) [0|0] "" Vector__XXX
 SG_ DAS_TP_bdlQltyME m8 : 60|2@1+ (1,0) [0|0] "" Vector__XXX
 SG_ DAS_TP_lcState m0 : 60|4@1+ (1,0) [0|0] "" Vector__XXX
 SG_ DAS_TP_bdrQltyME m8 : 62|2@1+ (1,0) [0|0] "" Vector__XXX
 SG_ DAS_TP_bdlFuse m6 : 63|1@1+ (1,0) [0|0] "" Vector__XXX
 SG_ DAS_TP_bdrFuse m7 : 63|1@1+ (1,0) [0|0] "" Vector__XXX
 SG_ DAS_TP_hppFuse m3 : 63|1@1+ (1,0) [0|0] "" Vector__XXX
 SG_ DAS_TP_llFuse m1 : 63|1@1+ (1,0) [0|0] "" Vector__XXX
 SG_ DAS_TP_navFuse m4 : 63|1@1+ (1,0) [0|0] "" Vector__XXX
 SG_ DAS_TP_rlFuse m2 : 63|1@1+ (1,0) [0|0] "" Vector__XXX
 SG_ DAS_TP_vlFuse m5 : 63|1@1+ (1,0) [0|0] "" Vector__XXX

BO_ 894 PARK_warningMatrix: 8 Vector__XXX
 SG_ PARK_matrixIndex M : 0|4@1+ (1,0) [0|0] "" Vector__XXX
 SG_ PARK_a001_s1_overTemp m0 : 4|1@1+ (1,0) [0|0] "" Vector__XXX
 SG_ PARK_a061_ecuUnderVoltage m1 : 4|1@1+ (1,0) [0|0] "" Vector__XXX
 SG_ PARK_a002_s1_internalFail m0 : 5|1@1+ (1,0) [0|0] "" Vector__XXX
 SG_ PARK_a062_ecuOverVoltage m1 : 5|1@1+ (1,0) [0|0] "" Vector__XXX
 SG_ PARK_a003_s1_linCommError m0 : 6|1@1+ (1,0) [0|0] "" Vector__XXX
 SG_ PARK_a063_sensorVoltage m1 : 6|1@1+ (1,0) [0|0] "" Vector__XXX
 SG_ PARK_a004_s1_blocked m0 : 7|1@1+ (1,0) [0|0] "" Vector__XXX
 SG_ PARK_a064_ecuFault m1 : 7|1@1+ (1,0) [0|0] "" Vector__XXX
 SG_ PARK_a005_s1_crossTalk m0 : 8|1@1+ (1,0) [0|0] "" Vector__XXX
 SG_ PARK_a065_crcFault m1 : 8|1@1+ (1,0) [0|0] "" Vector__XXX
 SG_ PARK_a006_s2_overTemp m0 : 9|1@1+ (1,0) [0|0] "" Vector__XXX
 SG_ PARK_a066_calibrationMissing m1 : 9|1@1+ (1,0) [0|0] "" Vector__XXX
 SG_ PARK_a007_s2_internalFail m0 : 10|1@1+ (1,0) [0|0] "" Vector__XXX
 SG_ PARK_a067_privateCANBusOff m1 : 10|1@1+ (1,0) [0|0] "" Vector__XXX
 SG_ PARK_a008_s2_linCommError m0 : 11|1@1+ (1,0) [0|0] "" Vector__XXX
 SG_ PARK_a068_hardwareWatchDog m1 : 11|1@1+ (1,0) [0|0] "" Vector__XXX
 SG_ PARK_a009_s2_blocked m0 : 12|1@1+ (1,0) [0|0] "" Vector__XXX
 SG_ PARK_a069_dasMia m1 : 12|1@1+ (1,0) [0|0] "" Vector__XXX
 SG_ PARK_a010_s2_crossTalk m0 : 13|1@1+ (1,0) [0|0] "" Vector__XXX
 SG_ PARK_a070_sccmMia m1 : 13|1@1+ (1,0) [0|0] "" Vector__XXX
 SG_ PARK_a011_s3_overTemp m0 : 14|1@1+ (1,0) [0|0] "" Vector__XXX
 SG_ PARK_a071_diMia m1 : 14|1@1+ (1,0) [0|0] "" Vector__XXX
 SG_ PARK_a012_s3_internalFail m0 : 15|1@1+ (1,0) [0|0] "" Vector__XXX
 SG_ PARK_a072_epasMia m1 : 15|1@1+ (1,0) [0|0] "" Vector__XXX
 SG_ PARK_a013_s3_linCommError m0 : 16|1@1+ (1,0) [0|0] "" Vector__XXX
 SG_ PARK_a073_epbMia m1 : 16|1@1+ (1,0) [0|0] "" Vector__XXX
 SG_ PARK_a014_s3_blocked m0 : 17|1@1+ (1,0) [0|0] "" Vector__XXX
 SG_ PARK_a074_espMia m1 : 17|1@1+ (1,0) [0|0] "" Vector__XXX
 SG_ PARK_a015_s3_crossTalk m0 : 18|1@1+ (1,0) [0|0] "" Vector__XXX
 SG_ PARK_a075_rcmMia m1 : 18|1@1+ (1,0) [0|0] "" Vector__XXX
 SG_ PARK_a016_s4_overTemp m0 : 19|1@1+ (1,0) [0|0] "" Vector__XXX
 SG_ PARK_a076_vcFrontMia m1 : 19|1@1+ (1,0) [0|0] "" Vector__XXX
 SG_ PARK_a017_s4_internalFail m0 : 20|1@1+ (1,0) [0|0] "" Vector__XXX
 SG_ PARK_a077_dasError m1 : 20|1@1+ (1,0) [0|0] "" Vector__XXX
 SG_ PARK_a018_s4_linCommError m0 : 21|1@1+ (1,0) [0|0] "" Vector__XXX
 SG_ PARK_a078_diError m1 : 21|1@1+ (1,0) [0|0] "" Vector__XXX
 SG_ PARK_a019_s4_blocked m0 : 22|1@1+ (1,0) [0|0] "" Vector__XXX
 SG_ PARK_a079_epasError m1 : 22|1@1+ (1,0) [0|0] "" Vector__XXX
 SG_ PARK_a020_s4_crossTalk m0 : 23|1@1+ (1,0) [0|0] "" Vector__XXX
 SG_ PARK_a080_epbError m1 : 23|1@1+ (1,0) [0|0] "" Vector__XXX
 SG_ PARK_a021_s5_overTemp m0 : 24|1@1+ (1,0) [0|0] "" Vector__XXX
 SG_ PARK_a081_espError m1 : 24|1@1+ (1,0) [0|0] "" Vector__XXX
 SG_ PARK_a022_s5_internalFail m0 : 25|1@1+ (1,0) [0|0] "" Vector__XXX
 SG_ PARK_a082_rcmError m1 : 25|1@1+ (1,0) [0|0] "" Vector__XXX
 SG_ PARK_a023_s5_linCommError m0 : 26|1@1+ (1,0) [0|0] "" Vector__XXX
 SG_ PARK_a083_vcFrontError m1 : 26|1@1+ (1,0) [0|0] "" Vector__XXX
 SG_ PARK_a024_s5_blocked m0 : 27|1@1+ (1,0) [0|0] "" Vector__XXX
 SG_ PARK_a084_sccmError m1 : 27|1@1+ (1,0) [0|0] "" Vector__XXX
 SG_ PARK_a025_s5_crossTalk m0 : 28|1@1+ (1,0) [0|0] "" Vector__XXX
 SG_ PARK_a085_watchdogReset m1 : 28|1@1+ (1,0) [0|0] "" Vector__XXX
 SG_ PARK_a026_s6_overTemp m0 : 29|1@1+ (1,0) [0|0] "" Vector__XXX
 SG_ PARK_a086_nvmFault m1 : 29|1@1+ (1,0) [0|0] "" Vector__XXX
 SG_ PARK_a027_s6_internalFail m0 : 30|1@1+ (1,0) [0|0] "" Vector__XXX
 SG_ PARK_a087_sensorMismatchError m1 : 30|1@1+ (1,0) [0|0] "" Vector__XXX
 SG_ PARK_a028_s6_linCommError m0 : 31|1@1+ (1,0) [0|0] "" Vector__XXX
 SG_ PARK_a029_s6_blocked m0 : 32|1@1+ (1,0) [0|0] "" Vector__XXX
 SG_ PARK_a030_s6_crossTalk m0 : 33|1@1+ (1,0) [0|0] "" Vector__XXX
 SG_ PARK_a031_s7_overTemp m0 : 34|1@1+ (1,0) [0|0] "" Vector__XXX
 SG_ PARK_a032_s7_internalFail m0 : 35|1@1+ (1,0) [0|0] "" Vector__XXX
 SG_ PARK_a033_s7_linCommError m0 : 36|1@1+ (1,0) [0|0] "" Vector__XXX
 SG_ PARK_a034_s7_blocked m0 : 37|1@1+ (1,0) [0|0] "" Vector__XXX
 SG_ PARK_a035_s7_crossTalk m0 : 38|1@1+ (1,0) [0|0] "" Vector__XXX
 SG_ PARK_a036_s8_overTemp m0 : 39|1@1+ (1,0) [0|0] "" Vector__XXX
 SG_ PARK_a037_s8_internalFail m0 : 40|1@1+ (1,0) [0|0] "" Vector__XXX
 SG_ PARK_a038_s8_linCommError m0 : 41|1@1+ (1,0) [0|0] "" Vector__XXX
 SG_ PARK_a039_s8_blocked m0 : 42|1@1+ (1,0) [0|0] "" Vector__XXX
 SG_ PARK_a040_s8_crossTalk m0 : 43|1@1+ (1,0) [0|0] "" Vector__XXX
 SG_ PARK_a041_s9_overTemp m0 : 44|1@1+ (1,0) [0|0] "" Vector__XXX
 SG_ PARK_a042_s9_internalFail m0 : 45|1@1+ (1,0) [0|0] "" Vector__XXX
 SG_ PARK_a043_s9_linCommError m0 : 46|1@1+ (1,0) [0|0] "" Vector__XXX
 SG_ PARK_a044_s9_blocked m0 : 47|1@1+ (1,0) [0|0] "" Vector__XXX
 SG_ PARK_a045_s9_crossTalk m0 : 48|1@1+ (1,0) [0|0] "" Vector__XXX
 SG_ PARK_a046_s10_overTemp m0 : 49|1@1+ (1,0) [0|0] "" Vector__XXX
 SG_ PARK_a047_s10_internalFail m0 : 50|1@1+ (1,0) [0|0] "" Vector__XXX
 SG_ PARK_a048_s10_linCommError m0 : 51|1@1+ (1,0) [0|0] "" Vector__XXX
 SG_ PARK_a049_s10_blocked m0 : 52|1@1+ (1,0) [0|0] "" Vector__XXX
 SG_ PARK_a050_s10_crossTalk m0 : 53|1@1+ (1,0) [0|0] "" Vector__XXX
 SG_ PARK_a051_s11_overTemp m0 : 54|1@1+ (1,0) [0|0] "" Vector__XXX
 SG_ PARK_a052_s11_internalFail m0 : 55|1@1+ (1,0) [0|0] "" Vector__XXX
 SG_ PARK_a053_s11_linCommError m0 : 56|1@1+ (1,0) [0|0] "" Vector__XXX
 SG_ PARK_a054_s11_blocked m0 : 57|1@1+ (1,0) [0|0] "" Vector__XXX
 SG_ PARK_a055_s11_crossTalk m0 : 58|1@1+ (1,0) [0|0] "" Vector__XXX
 SG_ PARK_a056_s12_overTemp m0 : 59|1@1+ (1,0) [0|0] "" Vector__XXX
 SG_ PARK_a057_s12_internalFail m0 : 60|1@1+ (1,0) [0|0] "" Vector__XXX
 SG_ PARK_a058_s12_linCommError m0 : 61|1@1+ (1,0) [0|0] "" Vector__XXX
 SG_ PARK_a059_s12_blocked m0 : 62|1@1+ (1,0) [0|0] "" Vector__XXX
 SG_ PARK_a060_s12_crossTalk m0 : 63|1@1+ (1,0) [0|0] "" Vector__XXX

BO_ 895 TPMS_debugC: 8 Vector__XXX
 SG_ TPMS_debugResponse : 0|64@1+ (1,0) [0|0] "" Vector__XXX

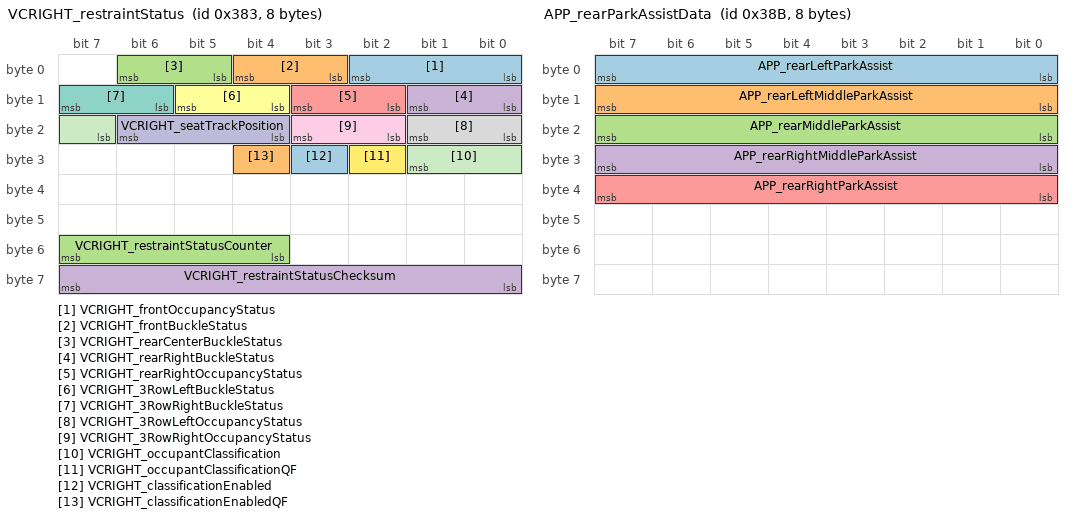
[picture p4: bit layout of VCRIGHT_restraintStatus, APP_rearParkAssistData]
BO_ 899 VCRIGHT_restraintStatus: 8 Vector__XXX
 SG_ VCRIGHT_frontOccupancyStatus : 0|3@1+ (1,0) [0|0] "" Vector__XXX
 SG_ VCRIGHT_frontBuckleStatus : 3|2@1+ (1,0) [0|0] "" Vector__XXX
 SG_ VCRIGHT_rearCenterBuckleStatus : 5|2@1+ (1,0) [0|0] "" Vector__XXX
 SG_ VCRIGHT_rearRightBuckleStatus : 8|2@1+ (1,0) [0|0] "" Vector__XXX
 SG_ VCRIGHT_rearRightOccupancyStatus : 10|2@1+ (1,0) [0|0] "" Vector__XXX
 SG_ VCRIGHT_3RowLeftBuckleStatus : 12|2@1+ (1,0) [0|0] "" Vector__XXX
 SG_ VCRIGHT_3RowRightBuckleStatus : 14|2@1+ (1,0) [0|0] "" Vector__XXX
 SG_ VCRIGHT_3RowLeftOccupancyStatus : 16|2@1+ (1,0) [0|0] "" Vector__XXX
 SG_ VCRIGHT_3RowRightOccupancyStatus : 18|2@1+ (1,0) [0|0] "" Vector__XXX
 SG_ VCRIGHT_seatTrackPosition : 20|3@1+ (1,0) [0|0] "" Vector__XXX
 SG_ VCRIGHT_occupantClassification : 23|3@1+ (1,0) [0|0] "" Vector__XXX
 SG_ VCRIGHT_occupantClassificationQF : 26|1@1+ (1,0) [0|0] "" Vector__XXX
 SG_ VCRIGHT_classificationEnabled : 27|1@1+ (1,0) [0|0] "" Vector__XXX
 SG_ VCRIGHT_classificationEnabledQF : 28|1@1+ (1,0) [0|0] "" Vector__XXX
 SG_ VCRIGHT_restraintStatusCounter : 52|4@1+ (1,0) [0|0] "" Vector__XXX
 SG_ VCRIGHT_restraintStatusChecksum : 56|8@1+ (1,0) [0|0] "" Vector__XXX

BO_ 905 DAS_status2: 8 Vector__XXX
 SG_ DAS_accSpeedLimit : 0|9@1+ (0.4,0) [0|0] "" Vector__XXX
 SG_ DAS_versionIdentifier : 9|1@1+ (1,0) [0|0] "" Vector__XXX
 SG_ DAS_pmmObstacleSeverity : 10|3@1+ (1,0) [0|0] "" Vector__XXX
 SG_ DAS_pmmLoggingRequest : 13|1@1+ (1,0) [0|0] "" Vector__XXX
 SG_ DAS_activationFailureStatus : 14|2@1+ (1,0) [0|0] "" Vector__XXX
 SG_ DAS_pmmUltrasonicsFaultReason : 16|3@1+ (1,0) [0|0] "" Vector__XXX
 SG_ DAS_pmmRadarFaultReason : 19|2@1+ (1,0) [0|0] "" Vector__XXX
 SG_ DAS_pmmSysFaultReason : 21|3@1+ (1,0) [0|0] "" Vector__XXX
 SG_ DAS_pmmCameraFaultReason : 24|2@1+ (1,0) [0|0] "" Vector__XXX
 SG_ DAS_ACC_report : 26|5@1+ (1,0) [0|0] "" Vector__XXX
 SG_ DAS_relaxCruiseLimits : 31|1@1+ (1,0) [0|0] "" Vector__XXX
 SG_ DAS_csaState : 32|2@1+ (1,0) [0|0] "" Vector__XXX
 SG_ DAS_radarTelemetry : 34|2@1+ (1,0) [0|0] "" Vector__XXX
 SG_ DAS_robState : 36|2@1+ (1,0) [0|0] "" Vector__XXX
 SG_ DAS_driverInteractionLevel : 38|2@1+ (1,0) [0|0] "" Vector__XXX
 SG_ DAS_ppOffsetDesiredRamp : 40|8@1+ (0.01,-1.28) [0|0] "" Vector__XXX
 SG_ DAS_longCollisionWarning : 48|4@1+ (1,0) [0|0] "" Vector__XXX
 SG_ DAS_status2Counter : 52|4@1+ (1,0) [0|0] "" Vector__XXX
 SG_ DAS_status2Checksum : 56|8@1+ (1,0) [0|0] "" Vector__XXX

BO_ 907 APP_rearParkAssistData: 8 Vector__XXX
 SG_ APP_rearLeftParkAssist : 0|8@1+ (1,0) [0|0] "" Vector__XXX
 SG_ APP_rearLeftMiddleParkAssist : 8|8@1+ (1,0) [0|0] "" Vector__XXX
 SG_ APP_rearMiddleParkAssist : 16|8@1+ (1,0) [0|0] "" Vector__XXX
 SG_ APP_rearRightMiddleParkAssist : 24|8@1+ (1,0) [0|0] "" Vector__XXX
 SG_ APP_rearRightParkAssist : 32|8@1+ (1,0) [0|0] "" Vector__XXX

BO_ 913 EPAS3S_alertMatrix: 8 Vector__XXX
 SG_ EPAS3S_matrixIndex M : 0|4@1+ (1,0) [0|0] "" Vector__XXX
 SG_ EPAS3S_a001_sent1Mia m0 : 4|1@1+ (1,0) [0|0] "" Vector__XXX
 SG_ EPAS3S_a061_bridgeUv m1 : 4|1@1+ (1,0) [0|0] "" Vector__XXX
 SG_ EPAS3S_a121_pvtEcuStatCrcError m2 : 4|1@1+ (1,0) [0|0] "" Vector__XXX
 SG_ EPAS3S_a002_sent1Error m0 : 5|1@1+ (1,0) [0|0] "" Vector__XXX
 SG_ EPAS3S_a062_assistCorrError m1 : 5|1@1+ (1,0) [0|0] "" Vector__XXX
 SG_ EPAS3S_a122_olpActive m2 : 5|1@1+ (1,0) [0|0] "" Vector__XXX
 SG_ EPAS3S_a003_trqSens1Supply m0 : 6|1@1+ (1,0) [0|0] "" Vector__XXX
 SG_ EPAS3S_a063_dampCorrError m1 : 6|1@1+ (1,0) [0|0] "" Vector__XXX
 SG_ EPAS3S_a123_combEcu2StatFail m2 : 6|1@1+ (1,0) [0|0] "" Vector__XXX
 SG_ EPAS3S_a004_trqSens1Eeprom m0 : 7|1@1+ (1,0) [0|0] "" Vector__XXX
 SG_ EPAS3S_a064_phaseCompCorrError m1 : 7|1@1+ (1,0) [0|0] "" Vector__XXX
 SG_ EPAS3S_a124_tempSensStuckInRange m2 : 7|1@1+ (1,0) [0|0] "" Vector__XXX
 SG_ EPAS3S_a005_sent2Mia m0 : 8|1@1+ (1,0) [0|0] "" Vector__XXX
 SG_ EPAS3S_a065_trqTarCorrError m1 : 8|1@1+ (1,0) [0|0] "" Vector__XXX
 SG_ EPAS3S_a125_trqSensTrimOutRange m2 : 8|1@1+ (1,0) [0|0] "" Vector__XXX
 SG_ EPAS3S_a006_sent2Error m0 : 9|1@1+ (1,0) [0|0] "" Vector__XXX
 SG_ EPAS3S_a066_returnCorrError m1 : 9|1@1+ (1,0) [0|0] "" Vector__XXX
 SG_ EPAS3S_a126_apsMia m2 : 9|1@1+ (1,0) [0|0] "" Vector__XXX
 SG_ EPAS3S_a007_trqSens2Supply m0 : 10|1@1+ (1,0) [0|0] "" Vector__XXX
 SG_ EPAS3S_a067_yawDampCorrError m1 : 10|1@1+ (1,0) [0|0] "" Vector__XXX
 SG_ EPAS3S_a127_apsCntError m2 : 10|1@1+ (1,0) [0|0] "" Vector__XXX
 SG_ EPAS3S_a008_trqSens2Eeprom m0 : 11|1@1+ (1,0) [0|0] "" Vector__XXX
 SG_ EPAS3S_a068_hystCorrError m1 : 11|1@1+ (1,0) [0|0] "" Vector__XXX
 SG_ EPAS3S_a128_apsCsError m2 : 11|1@1+ (1,0) [0|0] "" Vector__XXX
 SG_ EPAS3S_a009_sentDiff m0 : 12|1@1+ (1,0) [0|0] "" Vector__XXX
 SG_ EPAS3S_a069_eacCorrError m1 : 12|1@1+ (1,0) [0|0] "" Vector__XXX
 SG_ EPAS3S_a129_combEcu1StatFail m2 : 12|1@1+ (1,0) [0|0] "" Vector__XXX
 SG_ EPAS3S_a010_trqSensCalError m0 : 13|1@1+ (1,0) [0|0] "" Vector__XXX
 SG_ EPAS3S_a070_hodCorrError m1 : 13|1@1+ (1,0) [0|0] "" Vector__XXX
 SG_ EPAS3S_a130_sasOffsetNotCal m2 : 13|1@1+ (1,0) [0|0] "" Vector__XXX
 SG_ EPAS3S_a011_currentSensError m0 : 14|1@1+ (1,0) [0|0] "" Vector__XXX
 SG_ EPAS3S_a071_vehSpdCorrError m1 : 14|1@1+ (1,0) [0|0] "" Vector__XXX
 SG_ EPAS3S_a131_phaseFeedbackError m2 : 14|1@1+ (1,0) [0|0] "" Vector__XXX
 SG_ EPAS3S_a012_currentSensCalError m0 : 15|1@1+ (1,0) [0|0] "" Vector__XXX
 SG_ EPAS3S_a072_motFeedFwdError m1 : 15|1@1+ (1,0) [0|0] "" Vector__XXX
 SG_ EPAS3S_a132_motFeedFwdCounter25 m2 : 15|1@1+ (1,0) [0|0] "" Vector__XXX
 SG_ EPAS3S_a013_gateDriveError m0 : 16|1@1+ (1,0) [0|0] "" Vector__XXX
 SG_ EPAS3S_a073_motParEstError m1 : 16|1@1+ (1,0) [0|0] "" Vector__XXX
 SG_ EPAS3S_a133_motFeedFwdCounter50 m2 : 16|1@1+ (1,0) [0|0] "" Vector__XXX
 SG_ EPAS3S_a014_gateDriveTxError m0 : 17|1@1+ (1,0) [0|0] "" Vector__XXX
 SG_ EPAS3S_a074_overHeatProtect m1 : 17|1@1+ (1,0) [0|0] "" Vector__XXX
 SG_ EPAS3S_a134_motFeedFwdCounter85 m2 : 17|1@1+ (1,0) [0|0] "" Vector__XXX
 SG_ EPAS3S_a015_gateDriveEeprom m0 : 18|1@1+ (1,0) [0|0] "" Vector__XXX
 SG_ EPAS3S_a075_fspPwrCut m1 : 18|1@1+ (1,0) [0|0] "" Vector__XXX
 SG_ EPAS3S_a135_piCtrlCounter25 m2 : 18|1@1+ (1,0) [0|0] "" Vector__XXX
 SG_ EPAS3S_a016_phaseUhighUv m0 : 19|1@1+ (1,0) [0|0] "" Vector__XXX
 SG_ EPAS3S_a076_tempSensOutofRange m1 : 19|1@1+ (1,0) [0|0] "" Vector__XXX
 SG_ EPAS3S_a136_piCtrlCounter50 m2 : 19|1@1+ (1,0) [0|0] "" Vector__XXX
 SG_ EPAS3S_a017_phaseUlowUv m0 : 20|1@1+ (1,0) [0|0] "" Vector__XXX
 SG_ EPAS3S_a077_highSideFetError m1 : 20|1@1+ (1,0) [0|0] "" Vector__XXX
 SG_ EPAS3S_a137_piCtrlCounter85 m2 : 20|1@1+ (1,0) [0|0] "" Vector__XXX
 SG_ EPAS3S_a018_phaseVhighUv m0 : 21|1@1+ (1,0) [0|0] "" Vector__XXX
 SG_ EPAS3S_a078_phaseDisconnectError m1 : 21|1@1+ (1,0) [0|0] "" Vector__XXX
 SG_ EPAS3S_a144_diSpdMia m2 : 21|1@1+ (1,0) [0|0] "" Vector__XXX
 SG_ EPAS3S_a019_phaseVlowUv m0 : 22|1@1+ (1,0) [0|0] "" Vector__XXX
 SG_ EPAS3S_a079_backupCurrentPlaus m1 : 22|1@1+ (1,0) [0|0] "" Vector__XXX
 SG_ EPAS3S_a145_diSpdCntError m2 : 22|1@1+ (1,0) [0|0] "" Vector__XXX
 SG_ EPAS3S_a020_phaseWhighUv m0 : 23|1@1+ (1,0) [0|0] "" Vector__XXX
 SG_ EPAS3S_a080_ecuInitArbError m1 : 23|1@1+ (1,0) [0|0] "" Vector__XXX
 SG_ EPAS3S_a146_diSpdCsError m2 : 23|1@1+ (1,0) [0|0] "" Vector__XXX
 SG_ EPAS3S_a021_phaseWlowUv m0 : 24|1@1+ (1,0) [0|0] "" Vector__XXX
 SG_ EPAS3S_a081_coggCompError m1 : 24|1@1+ (1,0) [0|0] "" Vector__XXX
 SG_ EPAS3S_a147_backupVehSpeed m2 : 24|1@1+ (1,0) [0|0] "" Vector__XXX
 SG_ EPAS3S_a022_phaseUhighOv m0 : 25|1@1+ (1,0) [0|0] "" Vector__XXX
 SG_ EPAS3S_a082_polarityCalError m1 : 25|1@1+ (1,0) [0|0] "" Vector__XXX
 SG_ EPAS3S_a148_vMaxAssist m2 : 25|1@1+ (1,0) [0|0] "" Vector__XXX
 SG_ EPAS3S_a023_phaseUlowOv m0 : 26|1@1+ (1,0) [0|0] "" Vector__XXX
 SG_ EPAS3S_a083_crcMismatch m1 : 26|1@1+ (1,0) [0|0] "" Vector__XXX
 SG_ EPAS3S_a149_currentSensPathSwitch m2 : 26|1@1+ (1,0) [0|0] "" Vector__XXX
 SG_ EPAS3S_a024_phaseVhighOv m0 : 27|1@1+ (1,0) [0|0] "" Vector__XXX
 SG_ EPAS3S_a084_eacCancelled m1 : 27|1@1+ (1,0) [0|0] "" Vector__XXX
 SG_ EPAS3S_a150_currentSensOffsetDetect m2 : 27|1@1+ (1,0) [0|0] "" Vector__XXX
 SG_ EPAS3S_a025_phaseVlowOv m0 : 28|1@1+ (1,0) [0|0] "" Vector__XXX
 SG_ EPAS3S_a085_canBusOff m1 : 28|1@1+ (1,0) [0|0] "" Vector__XXX
 SG_ EPAS3S_a151_dcsCboot m2 : 28|1@1+ (1,0) [0|0] "" Vector__XXX
 SG_ EPAS3S_a026_phaseWhighOv m0 : 29|1@1+ (1,0) [0|0] "" Vector__XXX
 SG_ EPAS3S_a086_dasMia m1 : 29|1@1+ (1,0) [0|0] "" Vector__XXX
 SG_ EPAS3S_a152_dcsDiagReg m2 : 29|1@1+ (1,0) [0|0] "" Vector__XXX
 SG_ EPAS3S_a027_phaseWlowOv m0 : 30|1@1+ (1,0) [0|0] "" Vector__XXX
 SG_ EPAS3S_a087_dasCntError m1 : 30|1@1+ (1,0) [0|0] "" Vector__XXX
 SG_ EPAS3S_a153_dcsInitOffset m2 : 30|1@1+ (1,0) [0|0] "" Vector__XXX
 SG_ EPAS3S_a028_phaseUbootUv m0 : 31|1@1+ (1,0) [0|0] "" Vector__XXX
 SG_ EPAS3S_a088_dasCsError m1 : 31|1@1+ (1,0) [0|0] "" Vector__XXX
 SG_ EPAS3S_a154_assistTorqueDisabled m2 : 31|1@1+ (1,0) [0|0] "" Vector__XXX
 SG_ EPAS3S_a029_phaseVbootUv m0 : 32|1@1+ (1,0) [0|0] "" Vector__XXX
 SG_ EPAS3S_a089_espWsMia m1 : 32|1@1+ (1,0) [0|0] "" Vector__XXX
 SG_ EPAS3S_a155_backupEacActive m2 : 32|1@1+ (1,0) [0|0] "" Vector__XXX
 SG_ EPAS3S_a030_phaseWbootUv m0 : 33|1@1+ (1,0) [0|0] "" Vector__XXX
 SG_ EPAS3S_a090_espWsCntError m1 : 33|1@1+ (1,0) [0|0] "" Vector__XXX
 SG_ EPAS3S_a156_angleSensorDivergence m2 : 33|1@1+ (1,0) [0|0] "" Vector__XXX
 SG_ EPAS3S_a031_abnormalShutdown m0 : 34|1@1+ (1,0) [0|0] "" Vector__XXX
 SG_ EPAS3S_a091_espWsCsError m1 : 34|1@1+ (1,0) [0|0] "" Vector__XXX
 SG_ EPAS3S_a157_pmState2Mia m2 : 34|1@1+ (1,0) [0|0] "" Vector__XXX
 SG_ EPAS3S_a032_vRegOutputUv m0 : 35|1@1+ (1,0) [0|0] "" Vector__XXX
 SG_ EPAS3S_a092_espWrMia m1 : 35|1@1+ (1,0) [0|0] "" Vector__XXX
 SG_ EPAS3S_a158_pmState2CntError m2 : 35|1@1+ (1,0) [0|0] "" Vector__XXX
 SG_ EPAS3S_a033_vRegOutputOv m0 : 36|1@1+ (1,0) [0|0] "" Vector__XXX
 SG_ EPAS3S_a093_espWrCntError m1 : 36|1@1+ (1,0) [0|0] "" Vector__XXX
 SG_ EPAS3S_a159_pmState2CsError m2 : 36|1@1+ (1,0) [0|0] "" Vector__XXX
 SG_ EPAS3S_a034_vRegError m0 : 37|1@1+ (1,0) [0|0] "" Vector__XXX
 SG_ EPAS3S_a094_espWrCsError m1 : 37|1@1+ (1,0) [0|0] "" Vector__XXX
 SG_ EPAS3S_a160_latentFaultTestResult m2 : 37|1@1+ (1,0) [0|0] "" Vector__XXX
 SG_ EPAS3S_a035_vbbSupplyUv m0 : 38|1@1+ (1,0) [0|0] "" Vector__XXX
 SG_ EPAS3S_a095_espWsStatus m1 : 38|1@1+ (1,0) [0|0] "" Vector__XXX
 SG_ EPAS3S_a161_initTestPhaDisconnInfo m2 : 38|1@1+ (1,0) [0|0] "" Vector__XXX
 SG_ EPAS3S_a036_vbbSupplyOv m0 : 39|1@1+ (1,0) [0|0] "" Vector__XXX
 SG_ EPAS3S_a096_rcmMia m1 : 39|1@1+ (1,0) [0|0] "" Vector__XXX
 SG_ EPAS3S_a162_initTestHSDFetInfo m2 : 39|1@1+ (1,0) [0|0] "" Vector__XXX
 SG_ EPAS3S_a037_motPos1ParityError m0 : 40|1@1+ (1,0) [0|0] "" Vector__XXX
 SG_ EPAS3S_a097_rcmCntError m1 : 40|1@1+ (1,0) [0|0] "" Vector__XXX
 SG_ EPAS3S_a163_initTestGateDrvrInfo m2 : 40|1@1+ (1,0) [0|0] "" Vector__XXX
 SG_ EPAS3S_a038_motPos1Uv m0 : 41|1@1+ (1,0) [0|0] "" Vector__XXX
 SG_ EPAS3S_a098_rcmCsError m1 : 41|1@1+ (1,0) [0|0] "" Vector__XXX
 SG_ EPAS3S_a164_initTestDCSInfo m2 : 41|1@1+ (1,0) [0|0] "" Vector__XXX
 SG_ EPAS3S_a039_motPos1MagnetMia m0 : 42|1@1+ (1,0) [0|0] "" Vector__XXX
 SG_ EPAS3S_a099_yawRateStatus m1 : 42|1@1+ (1,0) [0|0] "" Vector__XXX
 SG_ EPAS3S_a165_epbStatusMia m2 : 42|1@1+ (1,0) [0|0] "" Vector__XXX
 SG_ EPAS3S_a040_motPos1LogicError m0 : 43|1@1+ (1,0) [0|0] "" Vector__XXX
 SG_ EPAS3S_a100_diMia m1 : 43|1@1+ (1,0) [0|0] "" Vector__XXX
 SG_ EPAS3S_a166_epbStatusCntError m2 : 43|1@1+ (1,0) [0|0] "" Vector__XXX
 SG_ EPAS3S_a041_motPos1tempError m0 : 44|1@1+ (1,0) [0|0] "" Vector__XXX
 SG_ EPAS3S_a101_diCntError m1 : 44|1@1+ (1,0) [0|0] "" Vector__XXX
 SG_ EPAS3S_a167_epbStatusCsError m2 : 44|1@1+ (1,0) [0|0] "" Vector__XXX
 SG_ EPAS3S_a042_motPos2ParityError m0 : 45|1@1+ (1,0) [0|0] "" Vector__XXX
 SG_ EPAS3S_a102_diCsError m1 : 45|1@1+ (1,0) [0|0] "" Vector__XXX
 SG_ EPAS3S_a168_torsionBarTorqueQfDegraded m2 : 45|1@1+ (1,0) [0|0] "" Vector__XXX
 SG_ EPAS3S_a043_motPos2Uv m0 : 46|1@1+ (1,0) [0|0] "" Vector__XXX
 SG_ EPAS3S_a103_vcFrontMia m1 : 46|1@1+ (1,0) [0|0] "" Vector__XXX
 SG_ EPAS3S_a044_motPos2MagnetMia m0 : 47|1@1+ (1,0) [0|0] "" Vector__XXX
 SG_ EPAS3S_a104_vcFrontCntError m1 : 47|1@1+ (1,0) [0|0] "" Vector__XXX
 SG_ EPAS3S_a045_motPos2LogicError m0 : 48|1@1+ (1,0) [0|0] "" Vector__XXX
 SG_ EPAS3S_a105_vcFrontCsError m1 : 48|1@1+ (1,0) [0|0] "" Vector__XXX
 SG_ EPAS3S_a046_motPos2tempError m0 : 49|1@1+ (1,0) [0|0] "" Vector__XXX
 SG_ EPAS3S_a106_vcFrontTempMia m1 : 49|1@1+ (1,0) [0|0] "" Vector__XXX
 SG_ EPAS3S_a047_motPosCorrError m0 : 50|1@1+ (1,0) [0|0] "" Vector__XXX
 SG_ EPAS3S_a107_uiTuneReqMia m1 : 50|1@1+ (1,0) [0|0] "" Vector__XXX
 SG_ EPAS3S_a048_motPosCalError m0 : 51|1@1+ (1,0) [0|0] "" Vector__XXX
 SG_ EPAS3S_a108_uiTuneReqCntError m1 : 51|1@1+ (1,0) [0|0] "" Vector__XXX
 SG_ EPAS3S_a049_piCtrlError m0 : 52|1@1+ (1,0) [0|0] "" Vector__XXX
 SG_ EPAS3S_a109_uiTuneReqCsError m1 : 52|1@1+ (1,0) [0|0] "" Vector__XXX
 SG_ EPAS3S_a050_mcuSmuError m0 : 53|1@1+ (1,0) [0|0] "" Vector__XXX
 SG_ EPAS3S_a110_sasMia m1 : 53|1@1+ (1,0) [0|0] "" Vector__XXX
 SG_ EPAS3S_a051_mcuSupError m0 : 54|1@1+ (1,0) [0|0] "" Vector__XXX
 SG_ EPAS3S_a111_sasCntError m1 : 54|1@1+ (1,0) [0|0] "" Vector__XXX
 SG_ EPAS3S_a052_intWatchdogError m0 : 55|1@1+ (1,0) [0|0] "" Vector__XXX
 SG_ EPAS3S_a112_sasCsError m1 : 55|1@1+ (1,0) [0|0] "" Vector__XXX
 SG_ EPAS3S_a053_extWatchdogError m0 : 56|1@1+ (1,0) [0|0] "" Vector__XXX
 SG_ EPAS3S_a113_sasStatusError m1 : 56|1@1+ (1,0) [0|0] "" Vector__XXX
 SG_ EPAS3S_a054_memoryProtectError m0 : 57|1@1+ (1,0) [0|0] "" Vector__XXX
 SG_ EPAS3S_a114_gtwConfigMia m1 : 57|1@1+ (1,0) [0|0] "" Vector__XXX
 SG_ EPAS3S_a055_floatPointError m0 : 58|1@1+ (1,0) [0|0] "" Vector__XXX
 SG_ EPAS3S_a115_ecuStatMia m1 : 58|1@1+ (1,0) [0|0] "" Vector__XXX
 SG_ EPAS3S_a056_battUv m0 : 59|1@1+ (1,0) [0|0] "" Vector__XXX
 SG_ EPAS3S_a116_ecuStatCntError m1 : 59|1@1+ (1,0) [0|0] "" Vector__XXX
 SG_ EPAS3S_a057_battUvReduced m0 : 60|1@1+ (1,0) [0|0] "" Vector__XXX
 SG_ EPAS3S_a117_ecuStatCrcError m1 : 60|1@1+ (1,0) [0|0] "" Vector__XXX
 SG_ EPAS3S_a058_battOv m0 : 61|1@1+ (1,0) [0|0] "" Vector__XXX
 SG_ EPAS3S_a118_privateBusOff m1 : 61|1@1+ (1,0) [0|0] "" Vector__XXX
 SG_ EPAS3S_a059_battOvReduced m0 : 62|1@1+ (1,0) [0|0] "" Vector__XXX
 SG_ EPAS3S_a119_pvtEcuStatMia m1 : 62|1@1+ (1,0) [0|0] "" Vector__XXX
 SG_ EPAS3S_a060_battBridgeDiff m0 : 63|1@1+ (1,0) [0|0] "" Vector__XXX
 SG_ EPAS3S_a120_pvtEcuStatCntError m1 : 63|1@1+ (1,0) [0|0] "" Vector__XXX

BO_ 917 OCS1P_alertMatrix: 8 Vector__XXX
 SG_ OCS1P_matrixIndex M : 0|4@1+ (1,0) [0|0] "" Vector__XXX
 SG_ OCS1P_w121_sandwichOpen m2 : 4|1@1+ (1,0) [0|0] "" Vector__XXX
 SG_ OCS1P_w122_sandwichLow m2 : 5|1@1+ (1,0) [0|0] "" Vector__XXX
 SG_ OCS1P_w123_sandwichShort m2 : 6|1@1+ (1,0) [0|0] "" Vector__XXX
 SG_ OCS1P_w124_cushionSelfOpen m2 : 7|1@1+ (1,0) [0|0] "" Vector__XXX
 SG_ OCS1P_w125_cushionSelfLow m2 : 8|1@1+ (1,0) [0|0] "" Vector__XXX
 SG_ OCS1P_w126_cushionSelfShort m2 : 9|1@1+ (1,0) [0|0] "" Vector__XXX
 SG_ OCS1P_w127_seatbackSelfOpen m2 : 10|1@1+ (1,0) [0|0] "" Vector__XXX
 SG_ OCS1P_w128_seatbackSelfLow m2 : 11|1@1+ (1,0) [0|0] "" Vector__XXX
 SG_ OCS1P_w129_seatbackSelfShort m2 : 12|1@1+ (1,0) [0|0] "" Vector__XXX
 SG_ OCS1P_w130_sandwichNoCalib m2 : 13|1@1+ (1,0) [0|0] "" Vector__XXX
 SG_ OCS1P_w131_cushionSelfNoCalib m2 : 14|1@1+ (1,0) [0|0] "" Vector__XXX
 SG_ OCS1P_w132_seatbackSelfNoCalib m2 : 15|1@1+ (1,0) [0|0] "" Vector__XXX
 SG_ OCS1P_w133_sandwichBadCalib m2 : 16|1@1+ (1,0) [0|0] "" Vector__XXX
 SG_ OCS1P_w134_uninitializedCalib m2 : 17|1@1+ (1,0) [0|0] "" Vector__XXX
 SG_ OCS1P_w015_NVMMAlert m0 : 18|1@1+ (1,0) [0|0] "" Vector__XXX
 SG_ OCS1P_w135_tempNoCalib m2 : 18|1@1+ (1,0) [0|0] "" Vector__XXX
 SG_ OCS1P_w136_cushionSelfDutyLow m2 : 19|1@1+ (1,0) [0|0] "" Vector__XXX
 SG_ OCS1P_w137_cushionSelfDutyHigh m2 : 20|1@1+ (1,0) [0|0] "" Vector__XXX
 SG_ OCS1P_w138_seatbackSelfDutyLow m2 : 21|1@1+ (1,0) [0|0] "" Vector__XXX
 SG_ OCS1P_w139_seatbackSelfDutyHigh m2 : 22|1@1+ (1,0) [0|0] "" Vector__XXX
 SG_ OCS1P_w140_tempInvalidCalib m2 : 23|1@1+ (1,0) [0|0] "" Vector__XXX
 SG_ OCS1P_w141_humidityInvalidCalib m2 : 24|1@1+ (1,0) [0|0] "" Vector__XXX
 SG_ OCS1P_w142_tempHumidityInvalid m2 : 25|1@1+ (1,0) [0|0] "" Vector__XXX
 SG_ OCS1P_w143_mismatchPassAirbag m2 : 26|1@1+ (1,0) [0|0] "" Vector__XXX
 SG_ OCS1P_w144_mismatchCarRegion m2 : 27|1@1+ (1,0) [0|0] "" Vector__XXX
 SG_ OCS1P_w145_rebaselineTriggered m2 : 28|1@1+ (1,0) [0|0] "" Vector__XXX
 SG_ OCS1P_w148_classificationMismatch m2 : 31|1@1+ (1,0) [0|0] "" Vector__XXX
 SG_ OCS1P_w150_rbEntryTriggered m2 : 33|1@1+ (1,0) [0|0] "" Vector__XXX
 SG_ OCS1P_w151_rbEntryExited m2 : 34|1@1+ (1,0) [0|0] "" Vector__XXX
 SG_ OCS1P_w152_rbExit1Triggered m2 : 35|1@1+ (1,0) [0|0] "" Vector__XXX
 SG_ OCS1P_w153_rbExit1Exited m2 : 36|1@1+ (1,0) [0|0] "" Vector__XXX
 SG_ OCS1P_w154_rbExit2Exited1 m2 : 37|1@1+ (1,0) [0|0] "" Vector__XXX
 SG_ OCS1P_w155_rbExit2Exited2 m2 : 38|1@1+ (1,0) [0|0] "" Vector__XXX
 SG_ OCS1P_w156_seatbeltReminderUnavailable m2 : 39|1@1+ (1,0) [0|0] "" Vector__XXX

BO_ 921 DAS_status: 8 Vector__XXX
 SG_ DAS_autopilotState : 0|4@1+ (1,0) [0|0] "" Vector__XXX
 SG_ DAS_blindSpotRearLeft : 4|2@1+ (1,0) [0|0] "" Vector__XXX
 SG_ DAS_blindSpotRearRight : 6|2@1+ (1,0) [0|0] "" Vector__XXX
 SG_ DAS_fusedSpeedLimit : 8|5@1+ (5,0) [0|0] "" Vector__XXX
 SG_ DAS_suppressSpeedWarning : 13|1@1+ (1,0) [0|0] "" Vector__XXX
 SG_ DAS_summonObstacle : 14|1@1+ (1,0) [0|0] "" Vector__XXX
 SG_ DAS_summonClearedGate : 15|1@1+ (1,0) [0|0] "" Vector__XXX
 SG_ DAS_visionOnlySpeedLimit : 16|5@1+ (5,0) [0|0] "" Vector__XXX
 SG_ DAS_heaterState : 21|1@1+ (1,0) [0|0] "" Vector__XXX
 SG_ DAS_forwardCollisionWarning : 22|2@1+ (1,0) [0|0] "" Vector__XXX
 SG_ DAS_autoparkReady : 24|1@1+ (1,0) [0|0] "" Vector__XXX
 SG_ DAS_autoParked : 25|1@1+ (1,0) [0|0] "" Vector__XXX
 SG_ DAS_autoparkActive : 26|1@1+ (1,0) [0|0] "" Vector__XXX
 SG_ DAS_summonFwdLeashReached : 27|1@1+ (1,0) [0|0] "" Vector__XXX
 SG_ DAS_summonRvsLeashReached : 28|1@1+ (1,0) [0|0] "" Vector__XXX
 SG_ DAS_lssState : 29|3@1+ (1,0) [0|0] "" Vector__XXX
 SG_ DAS_sideCollisionAvoid : 32|2@1+ (1,0) [0|0] "" Vector__XXX
 SG_ DAS_sideCollisionWarning : 34|2@1+ (1,0) [0|0] "" Vector__XXX
 SG_ DAS_sideCollisionInhibit : 36|1@1+ (1,0) [0|0] "" Vector__XXX
 SG_ DAS_laneDepartureWarning : 37|3@1+ (1,0) [0|0] "" Vector__XXX
 SG_ DAS_fleetSpeedState : 40|2@1+ (1,0) [0|0] "" Vector__XXX
 SG_ DAS_autopilotHandsOnState : 42|4@1+ (1,0) [0|0] "" Vector__XXX
 SG_ DAS_autoLaneChangeState : 46|5@1+ (1,0) [0|0] "" Vector__XXX
 SG_ DAS_summonAvailable : 51|1@1+ (1,0) [0|0] "" Vector__XXX
 SG_ DAS_statusCounter : 52|4@1+ (1,0) [0|0] "" Vector__XXX
 SG_ DAS_statusChecksum : 56|8@1+ (1,0) [0|0] "" Vector__XXX

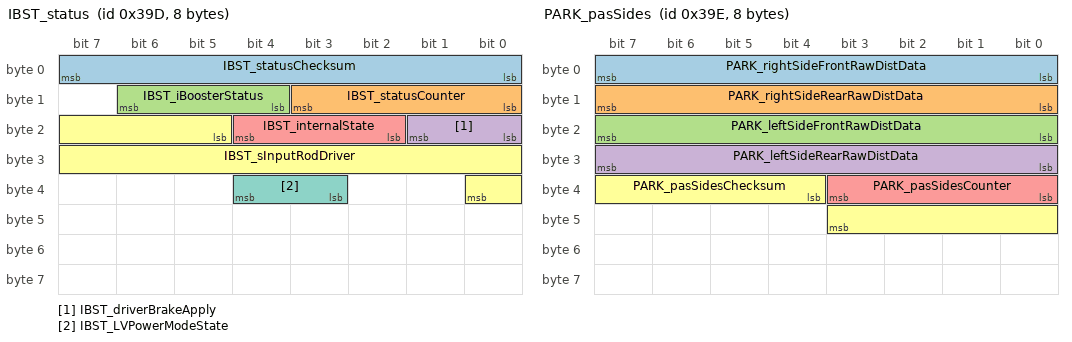
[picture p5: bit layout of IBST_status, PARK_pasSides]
BO_ 925 IBST_status: 8 Vector__XXX
 SG_ IBST_statusChecksum : 0|8@1+ (1,0) [0|0] "" Vector__XXX
 SG_ IBST_statusCounter : 8|4@1+ (1,0) [0|0] "" Vector__XXX
 SG_ IBST_iBoosterStatus : 12|3@1+ (1,0) [0|0] "" Vector__XXX
 SG_ IBST_driverBrakeApply : 16|2@1+ (1,0) [0|0] "" Vector__XXX
 SG_ IBST_internalState : 18|3@1+ (1,0) [0|0] "" Vector__XXX
 SG_ IBST_sInputRodDriver : 21|12@1+ (0.015625,-5) [0|0] "" Vector__XXX
 SG_ IBST_LVPowerModeState : 35|2@1+ (1,0) [0|0] "" Vector__XXX

BO_ 926 PARK_pasSides: 8 Vector__XXX
 SG_ PARK_rightSideFrontRawDistData : 0|8@1+ (1,0) [0|0] "" Vector__XXX
 SG_ PARK_rightSideRearRawDistData : 8|8@1+ (1,0) [0|0] "" Vector__XXX
 SG_ PARK_leftSideFrontRawDistData : 16|8@1+ (1,0) [0|0] "" Vector__XXX
 SG_ PARK_leftSideRearRawDistData : 24|8@1+ (1,0) [0|0] "" Vector__XXX
 SG_ PARK_pasSidesCounter : 32|4@1+ (1,0) [0|0] "" Vector__XXX
 SG_ PARK_pasSidesChecksum : 36|8@1+ (1,0) [0|0] "" Vector__XXX

BO_ 937 DAS_telemetry: 8 Vector__XXX
 SG_ DAS_telemetryMultiplexer M : 0|8@1+ (1,0) [0|0] "" Vector__XXX
 SG_ DAS_MCPObserved m1 : 8|1@1+ (1,0) [0|0] "" Vector__XXX
 SG_ DAS_assPrevSetSpeed m9 : 8|8@1+ (0.25,0) [0|0] "" Vector__XXX
 SG_ DAS_soCamCipvStatus m8 : 8|2@1+ (1,0) [0|0] "" Vector__XXX
 SG_ DAS_stopSignLongitudinalDist m2 : 8|10@1+ (0.1,0) [0|0] "" Vector__XXX
 SG_ DAS_telLeftLaneType m0 : 8|3@1+ (1,0) [0|0] "" Vector__XXX
 SG_ DAS_accReengaged m1 : 9|1@1+ (1,0) [0|0] "" Vector__XXX
 SG_ DAS_csaOverride m7 : 10|1@1+ (1,0) [0|0] "" Vector__XXX
 SG_ DAS_pedestrianInFOVBeforeIntr m1 : 10|1@1+ (1,0) [0|0] "" Vector__XXX
 SG_ DAS_soRad5Status m8 : 10|2@1+ (1,0) [0|0] "" Vector__XXX
 SG_ DAS_csaIntState m7 : 11|3@1+ (1,0) [0|0] "" Vector__XXX
 SG_ DAS_pedestrianInFOVAfterIntr m1 : 11|1@1+ (1,0) [0|0] "" Vector__XXX
 SG_ DAS_telRightLaneType m0 : 11|3@1+ (1,0) [0|0] "" Vector__XXX
 SG_ DAS_camFreeSpaceBeforeIntr m1 : 12|1@1+ (1,0) [0|0] "" Vector__XXX
 SG_ DAS_soRad1Status m8 : 12|2@1+ (1,0) [0|0] "" Vector__XXX
 SG_ DAS_camFreeSpaceAfterIntr m1 : 13|1@1+ (1,0) [0|0] "" Vector__XXX
 SG_ DAS_csaEnableSpeed m7 : 14|12@1+ (0.05,-25) [0|0] "" Vector__XXX
 SG_ DAS_soCamCipvDx m8 : 14|6@1+ (2,0) [0|0] "" Vector__XXX
 SG_ DAS_telLeftMarkerQuality m0 : 14|2@1+ (1,0) [0|0] "" Vector__XXX
 SG_ DAS_timeOfIntervention m1 : 14|6@1+ (0.25,0) [0|0] "" Vector__XXX
 SG_ DAS_assNewSetSpeed m9 : 16|8@1+ (0.25,0) [0|0] "" Vector__XXX
 SG_ DAS_telRightMarkerQuality m0 : 16|2@1+ (1,0) [0|0] "" Vector__XXX
 SG_ DAS_stopSignLateralDist m2 : 18|8@1+ (0.25,-32) [0|0] "" Vector__XXX
 SG_ DAS_telLeftMarkerColor m0 : 18|2@1+ (1,0) [0|0] "" Vector__XXX
 SG_ DAS_soRad1Dx m8 : 20|6@1+ (2,0) [0|0] "" Vector__XXX
 SG_ DAS_telRightMarkerColor m0 : 20|2@1+ (1,0) [0|0] "" Vector__XXX
 SG_ DAS_timeOfFirstPedestrian m1 : 20|6@1+ (0.25,0) [0|0] "" Vector__XXX
 SG_ DAS_telLeftLaneCrossing m0 : 22|1@1+ (1,0) [0|0] "" Vector__XXX
 SG_ DAS_telRightLaneCrossing m0 : 23|1@1+ (1,0) [0|0] "" Vector__XXX
 SG_ DAS_assFusedSpeedLimit m9 : 24|6@1+ (1,0) [0|0] "" Vector__XXX
 SG_ DAS_csaDisableSpeed m7 : 26|12@1+ (0.05,-25) [0|0] "" Vector__XXX
 SG_ DAS_soRad5Dx m8 : 26|6@1+ (2,0) [0|0] "" Vector__XXX
 SG_ DAS_stopSignHeight m2 : 26|6@1+ (0.1,0) [0|0] "" Vector__XXX
 SG_ DAS_timeOfACCReengaging m1 : 26|6@1+ (0.25,0) [0|0] "" Vector__XXX
 SG_ DAS_assAutosteerActive m9 : 30|1@1+ (1,0) [0|0] "" Vector__XXX
 SG_ DAS_assSmartSpeedActive m9 : 31|1@1+ (1,0) [0|0] "" Vector__XXX
 SG_ DAS_durationOfPrevACCStandstill m1 : 32|6@1+ (0.5,0) [0|0] "" Vector__XXX
 SG_ DAS_soCamCipvDy m8 : 32|5@1+ (0.4,-6.4) [0|0] "" Vector__XXX
 SG_ DAS_stopSignStopLineDistance m2 : 32|10@1+ (0.1,-20) [0|0] "" Vector__XXX
 SG_ DAS_soRad5Dy m8 : 37|5@1+ (0.4,-6.4) [0|0] "" Vector__XXX
 SG_ DAS_maxAbsSteeringWheelAngle m1 : 38|7@1+ (2,0) [0|0] "" Vector__XXX
 SG_ DAS_csaFiltCurv m7 : 40|16@1- (1e-06,0) [0|0] "" Vector__XXX
 SG_ DAS_soCamCipvVx m8 : 42|5@1+ (1,0) [0|0] "" Vector__XXX
 SG_ DAS_stopSignCIPVDistance m2 : 42|6@1+ (0.5,0) [0|0] "" Vector__XXX
 SG_ DAS_targetRelvelAtIntervention m1 : 45|6@1+ (0.25,-2) [0|0] "" Vector__XXX
 SG_ DAS_soRad5ObstProb m8 : 47|4@1+ (0.0625,0) [0|0] "" Vector__XXX
 SG_ DAS_stopSignHostAccel m2 : 48|10@1+ (0.01,-5) [0|0] "" Vector__XXX
 SG_ DAS_soRad5Dz m8 : 51|6@1+ (0.25,-5) [0|0] "" Vector__XXX
 SG_ DAS_targetDistAtIntervention m1 : 51|6@1+ (0.5,0) [0|0] "" Vector__XXX
 SG_ DAS_csaMeasLatAccel m7 : 56|8@1+ (0.08,-10.24) [0|0] "" Vector__XXX
 SG_ DAS_egoSpeedAtIntervention m1 : 57|6@1+ (0.5,0) [0|0] "" Vector__XXX
 SG_ DAS_soRad5powerdB m8 : 57|7@1+ (2,0) [0|0] "" Vector__XXX
 SG_ DAS_stopSignCrossingWarning m2 : 58|1@1+ (1,0) [0|0] "" Vector__XXX
 SG_ DAS_stopSignIndex m2 : 59|4@1+ (1,0) [0|0] "" Vector__XXX

BO_ 939 APP_driverMonitorStatus: 8 Vector__XXX
 SG_ APP_cabinCamTelemetryOn : 0|1@1+ (1,0) [0|0] "" Vector__XXX
 SG_ APP_attnMonitorVersion : 1|3@1+ (1,0) [0|0] "" Vector__XXX
 SG_ APP_attnBasedDriverMonitorOn : 4|1@1+ (1,0) [0|0] "" Vector__XXX
 SG_ APP_handsOnDetected : 5|1@1+ (1,0) [0|0] "" Vector__XXX
 SG_ APP_handsOnDetectedSource : 8|3@1+ (1,0) [0|0] "" Vector__XXX
 SG_ APP_cabinCamBlinded : 11|1@1+ (1,0) [0|0] "" Vector__XXX
 SG_ APP_cabinCamDark : 12|1@1+ (1,0) [0|0] "" Vector__XXX
 SG_ APP_driverStateUnknown : 13|1@1+ (1,0) [0|0] "" Vector__XXX
 SG_ APP_driverNotLively : 14|1@1+ (1,0) [0|0] "" Vector__XXX
 SG_ APP_driverStateUnknownHyst : 15|1@1+ (1,0) [0|0] "" Vector__XXX
 SG_ APP_driverLowNominal : 16|1@1+ (1,0) [0|0] "" Vector__XXX
 SG_ APP_driverHeadCappedHyst : 17|1@1+ (1,0) [0|0] "" Vector__XXX
 SG_ APP_driverSunglassesUseHyst : 18|1@1+ (1,0) [0|0] "" Vector__XXX
 SG_ APP_cabinLowLux : 19|1@1+ (1,0) [0|0] "" Vector__XXX
 SG_ APP_cabinCamInconsistent : 20|1@1+ (1,0) [0|0] "" Vector__XXX
 SG_ APP_driverLeaningBack : 21|1@1+ (1,0) [0|0] "" Vector__XXX
 SG_ APP_driverLowEyeVisibility : 22|1@1+ (1,0) [0|0] "" Vector__XXX
 SG_ APP_driverHandsNotReady : 23|1@1+ (1,0) [0|0] "" Vector__XXX
 SG_ APP_driverSeatUnoccupied : 24|1@1+ (1,0) [0|0] "" Vector__XXX
 SG_ APP_handsOnInputRequired : 25|1@1+ (1,0) [0|0] "" Vector__XXX
 SG_ APP_cabinCamDarkHyst : 26|1@1+ (1,0) [0|0] "" Vector__XXX
 SG_ APP_cabinLowLuxHyst : 27|1@1+ (1,0) [0|0] "" Vector__XXX
 SG_ APP_ADDWSystemStatus : 28|2@1+ (1,0) [0|0] "" Vector__XXX

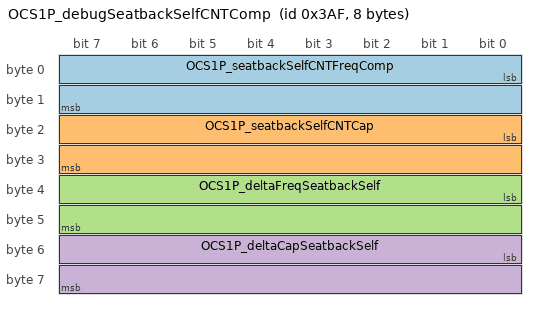
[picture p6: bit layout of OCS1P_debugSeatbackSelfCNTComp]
BO_ 943 OCS1P_debugSeatbackSelfCNTComp: 8 Vector__XXX
 SG_ OCS1P_seatbackSelfCNTFreqComp : 0|16@1+ (1,0) [0|0] "" Vector__XXX
 SG_ OCS1P_seatbackSelfCNTCap : 16|16@1+ (0.005,0) [0|0] "" Vector__XXX
 SG_ OCS1P_deltaFreqSeatbackSelf : 32|16@1- (1,0) [0|0] "" Vector__XXX
 SG_ OCS1P_deltaCapSeatbackSelf : 48|16@1- (0.0025,0) [0|0] "" Vector__XXX

VAL_ 832 VCFRONT_matrixIndex 0 "AlertMatrix0" 1 "AlertMatrix1" 2 "AlertMatrix2" 3 "AlertMatrix3" 4 "AlertMatrix4" 5 "AlertMatrix5" 6 "AlertMatrix6" 7 "AlertMatrix7" 8 "AlertMatrix8" 9 "AlertMatrix9" ;
VAL_ 838 GTW_autopilotOverrideState 0 "BASE" 1 "SUBSCRIPTION" 2 "TRIAL" ;
VAL_ 840 GTW_vehicleVersionMatchStatus 0 "NOT_CALCULATED_YET" 1 "MISMATCHED" 2 "MATCHED" ;
VAL_ 840 GTW_hwtype 0 "SNA" 1 "MPC57" 2 "SPC58" ;
VAL_ 840 GTW_sentryModeState 0 "OFF" 1 "IDLE" 2 "ARMED" 3 "AWARE" 4 "PANIC" 5 "QUIET" 6 "SNA" ;
VAL_ 846 PARK_frontLeftMiddleRawDistData 255 "SNA" ;
VAL_ 846 PARK_frontMiddleRawDistData 255 "SNA" ;
VAL_ 846 PARK_frontRightMiddleRawDistData 255 "SNA" ;
VAL_ 848 APS_w208_rackDetected 0 "UNKNOWN" 1 "NO_RACK" 2 "RACK_DETECTED" 3 "SNA" ;
VAL_ 849 RCM_infoIndex 0 "DEPRECATED_0" 1 "DEPRECATED_1" 2 "DEPRECATED_2" 3 "DEPRECATED_3" 4 "DEPRECATED_4" 5 "DEPRECATED_5" 6 "DEPRECATED_6" 7 "DEPRECATED_7" 8 "DEPRECATED_8" 9 "DEPRECATED_9" 10 "BUILD_HWID_COMPONENTID" 11 "PCBAID_ASSYID_USAGEID" 13 "APP_CRC" 14 "BOOTLOADER_SVN" 15 "BOOTLOADER_CRC" 16 "SUBCOMPONENT" 17 "APP_GITHASH" 18 "BOOTLOADER_GITHASH" 19 "VERSION_DEPRECATED" 20 "UDS_PROTOCOL_BOOTCRC" 22 "VARIANTCRC" 25 "PACKAGE_PN_1_7" 26 "PACKAGE_PN_8_14" 27 "PACKAGE_PN_15_20" 29 "PACKAGE_SN_1_7" 30 "PACKAGE_SN_8_14" 31 "SUBCOMPONENT_GITHASH" 255 "END" ;
VAL_ 849 RCM_infoBuildType 0 "UNKNOWN_BUILD" 1 "PLATFORM_BUILD" 2 "LOCAL_BUILD" 3 "TRACEABLE_CI_BUILD" 4 "MFG_BUILD" ;
VAL_ 850 TRCM_infoIndex 0 "DEPRECATED_0" 1 "DEPRECATED_1" 2 "DEPRECATED_2" 3 "DEPRECATED_3" 4 "DEPRECATED_4" 5 "DEPRECATED_5" 6 "DEPRECATED_6" 7 "DEPRECATED_7" 8 "DEPRECATED_8" 9 "DEPRECATED_9" 10 "BUILD_HWID_COMPONENTID" 11 "PCBAID_ASSYID_USAGEID" 13 "APP_CRC" 14 "BOOTLOADER_SVN" 15 "BOOTLOADER_CRC" 16 "SUBCOMPONENT" 17 "APP_GITHASH" 18 "BOOTLOADER_GITHASH" 19 "VERSION_DEPRECATED" 20 "UDS_PROTOCOL_BOOTCRC" 22 "VARIANTCRC" 25 "PACKAGE_PN_1_7" 26 "PACKAGE_PN_8_14" 27 "PACKAGE_PN_15_20" 29 "PACKAGE_SN_1_7" 30 "PACKAGE_SN_8_14" 31 "SUBCOMPONENT_GITHASH" 255 "END" ;
VAL_ 850 TRCM_infoBuildType 0 "UNKNOWN_BUILD" 1 "PLATFORM_BUILD" 2 "LOCAL_BUILD" 3 "TRACEABLE_CI_BUILD" 4 "MFG_BUILD" ;
VAL_ 850 TRCM_infoAssemblyId 1 "ASSEMBLY1" 255 "ASSEMBLY_SNA" ;
VAL_ 851 UI_autopilotTrial 0 "NONE" 1 "START" 2 "STOP" 3 "ACTIVE" ;
VAL_ 851 UI_factoryReset 0 "NONE_SNA" 1 "DEVELOPER" 2 "DIAGNOSTIC" 3 "CUSTOMER" ;
VAL_ 851 UI_cellNetworkTechnology 0 "NONE" 1 "GPRS" 2 "EDGE" 3 "UMTS" 4 "HSDPA" 5 "HSUPA" 6 "HSPA" 7 "LTE" 8 "GSM" 9 "CDMA" 10 "WCDMA" 15 "SNA" ;
VAL_ 851 UI_cellSignalBars 0 "ZERO" 1 "ONE" 2 "TWO" 3 "THREE" 4 "FOUR" 5 "FIVE" 7 "SNA" ;
VAL_ 851 UI_trailerModeTelltale 0 "OFF" 1 "BLUE" 2 "YELLOW" 3 "RED" ;
VAL_ 856 UI_TPMSMode 0 "UNUSED_MODE" 1 "NORMAL_MODE" 2 "PERFORMANCE_MODE" ;
VAL_ 856 UI_TPMSLearnIDMode 0 "NO_ID_LEARN_FUNCTION" 1 "AUTO_LEARN_ACTIVE_BY_MANUAL" 2 "AUTO_LOCATION_ACTIVE_BY_MANUAL" 3 "AUTO_LEARN_ACTIVE_AFTER_PWR" 4 "AUTO_LOCATION_ACTIVE_AFTER_PWR" ;
VAL_ 856 UI_sizeOfWheelSelect 0 "UNUSED" 1 "18_INCH_WHEEL" 2 "19_INCH_WHEEL" ;
VAL_ 861 IBST_matrixIndex 0 "AlertMatrix0" 1 "AlertMatrix1" 2 "AlertMatrix2" 3 "AlertMatrix3" ;
VAL_ 862 PARK_rearLeftMiddleRawDistData 255 "SNA" ;
VAL_ 862 PARK_rearMiddleRawDistData 255 "SNA" ;
VAL_ 862 PARK_rearRightMiddleRawDistData 255 "SNA" ;
VAL_ 879 TPMS_WA_version 254 "LOCAL_BUILD" 255 "SNA" ;
VAL_ 879 TPMS_learningStatus 0 "FAILED" 1 "ONGOING" 2 "STOPPED" 3 "PASSED" ;
VAL_ 879 TPMS_localisationStatus 0 "FAILED" 1 "ONGOING" 2 "STOPPED" 3 "PASSED" ;
VAL_ 880 EPAS3S_steeringRackForce 1022 "NOT_IN_SPEC" 1023 "SNA" ;
VAL_ 880 EPAS3S_steeringFault 0 "NO_FAULT" 1 "FAULT" ;
VAL_ 880 EPAS3S_steeringReduced 0 "NORMAL_ASSIST" 1 "REDUCED_ASSIST" ;
VAL_ 880 EPAS3S_internalSASQF 0 "UNDEFINABLE_ACCURACY" 1 "IN_SPEC" ;
VAL_ 880 EPAS3S_currentTuneMode 0 "DM_COMFORT" 1 "DM_STANDARD" 2 "DM_SPORT" 3 "RWD_COMFORT" 4 "RWD_STANDARD" 5 "RWD_SPORT" ;
VAL_ 880 EPAS3S_torsionBarTorque 4094 "UNDEFINABLE_DATA" 4095 "SNA" ;
VAL_ 880 EPAS3S_eacErrorCode 0 "EAC_ERROR_IDLE" 1 "EAC_ERROR_MIN_SPEED" 2 "EAC_ERROR_MAX_SPEED" 3 "EAC_ERROR_HANDS_ON" 4 "EAC_ERROR_TMP_FAULT" 5 "EAR_ERROR_MAX_STEER_DELTA" 6 "EAC_ERROR_HIGH_ANGLE_REQ" 7 "EAC_ERROR_HIGH_ANGLE_RATE_REQ" 8 "EAC_ERROR_HIGH_ANGLE_SAFETY" 9 "EAC_ERROR_HIGH_ANGLE_RATE_SAFETY" 10 "EAC_ERROR_HIGH_MMOT_SAFETY" 11 "EAC_ERROR_HIGH_TORSION_SAFETY" 12 "EAC_ERROR_LOW_ASSIST" 13 "EAC_ERROR_PINION_VEL_DIFF" 14 "EAC_EXTERNAL_MONITOR_INHIBIT" 15 "SNA" ;
VAL_ 880 EPAS3S_handsOnLevel 0 "0" 1 "1" 2 "2" 3 "3" ;
VAL_ 880 EPAS3S_eacStatus 0 "INHIBITED" 1 "AVAILABLE" 2 "ACTIVE" 3 "FAULT" 4 "LKA_ELK_AVAILABLE" 5 "LKA_ACTIVE" 6 "ELK_AVAILABLE" 7 "ELK_ACTIVE" ;
VAL_ 881 RCM_matrixIndex 0 "AlertMatrix0" 1 "AlertMatrix1" ;
VAL_ 881 RCM_a108_crashAlgoWakeup 0 "INACTIVE" 1 "ACTIVE" 3 "SNA" ;
VAL_ 881 RCM_a110_factoryMode 0 "DISABLED" 1 "ENABLED" ;
VAL_ 882 TRCM_matrixIndex 0 "AlertMatrix0" 1 "AlertMatrix1" 2 "AlertMatrix2" ;
VAL_ 890 DAS_TP_multiplexer 0 "START" 1 "LEFT_LANE" 2 "RIGHT_LANE" 3 "HPP" 4 "NAV" 5 "VIRTUAL_LANE" 6 "LEFT_BOTTS_DOTS" 7 "RIGHT_BOTTS_DOTS" 8 "LANE_INFO" 9 "END" ;
VAL_ 890 DAS_TP_llType 0 "UNDECIDED" 1 "SOLID" 2 "ROAD_EDGE" 3 "DASHED" 4 "DOUBLE_LANE" 5 "BOTTS_DOTS" 6 "BARRIER" 7 "INVALID" ;
VAL_ 890 DAS_TP_rlType 0 "UNDECIDED" 1 "SOLID" 2 "ROAD_EDGE" 3 "DASHED" 4 "DOUBLE_LANE" 5 "BOTTS_DOTS" 6 "BARRIER" 7 "INVALID" ;
VAL_ 890 DAS_TP_plannerState 0 "DISABLED" 1 "VL" 2 "FOLLOW" 3 "LANECHANGE_REQUESTED" 4 "LANECHANGE_IN_PROGRESS" 5 "LANECHANGE_WAIT_FOR_SIDE_OBSTACLE" 6 "LANECHANGE_WAIT_FOR_FWD_OBSTACLE" 7 "LANECHANGE_ABORT" ;
VAL_ 894 PARK_matrixIndex 0 "AlertMatrix0" 1 "AlertMatrix1" ;
VAL_ 899 VCRIGHT_frontOccupancyStatus 0 "UNOCCUPIED" 1 "OCCUPIED" 2 "OCCUPANCY_FAULTED" 3 "NOT_CONFIGURED" 7 "OCCUPANCY_SNA" ;
VAL_ 899 VCRIGHT_frontBuckleStatus 0 "UNLATCHED" 1 "LATCHED" 2 "FAULTED" 3 "SNA" ;
VAL_ 899 VCRIGHT_rearCenterBuckleStatus 0 "UNLATCHED" 1 "LATCHED" 2 "FAULTED" 3 "SNA" ;
VAL_ 899 VCRIGHT_rearRightBuckleStatus 0 "UNLATCHED" 1 "LATCHED" 2 "FAULTED" 3 "SNA" ;
VAL_ 899 VCRIGHT_rearRightOccupancyStatus 0 "UNOCCUPIED" 1 "OCCUPIED" 2 "OCCUPANCY_FAULTED" 3 "OCCUPANCY_SNA" ;
VAL_ 899 VCRIGHT_3RowLeftBuckleStatus 0 "UNLATCHED" 1 "LATCHED" 2 "FAULTED" 3 "SNA" ;
VAL_ 899 VCRIGHT_3RowRightBuckleStatus 0 "UNLATCHED" 1 "LATCHED" 2 "FAULTED" 3 "SNA" ;
VAL_ 899 VCRIGHT_3RowLeftOccupancyStatus 0 "UNOCCUPIED" 1 "OCCUPIED" 2 "OCCUPANCY_FAULTED" 3 "OCCUPANCY_SNA" ;
VAL_ 899 VCRIGHT_3RowRightOccupancyStatus 0 "UNOCCUPIED" 1 "OCCUPIED" 2 "OCCUPANCY_FAULTED" 3 "OCCUPANCY_SNA" ;
VAL_ 899 VCRIGHT_seatTrackPosition 0 "FORWARD" 1 "REARWARD" 2 "NOT_CONFIGURED" 3 "FAULTED" 7 "SNA" ;
VAL_ 899 VCRIGHT_occupantClassification 0 "EMPTY" 1 "INHIBIT" 2 "SMALL" 3 "LARGE" 4 "INIT" 5 "NOT_CONFIGURED" 7 "SNA" ;
VAL_ 899 VCRIGHT_occupantClassificationQF 0 "FAULTED" 1 "NOT_FAULTED" ;
VAL_ 905 DAS_accSpeedLimit 0 "NONE" 1023 "SNA" ;
VAL_ 905 DAS_pmmObstacleSeverity 0 "NONE" 1 "IMMINENT_REAR" 2 "IMMINENT_FRONT" 3 "BRAKE_REQUEST" 4 "CRASH_REAR" 5 "CRASH_FRONT" 6 "ACCEL_LIMIT" 7 "SNA" ;
VAL_ 905 DAS_pmmLoggingRequest 0 "FALSE" 1 "TRUE" ;
VAL_ 905 DAS_activationFailureStatus 0 "IDLE" 1 "FAILED_1" 2 "FAILED_2" ;
VAL_ 905 DAS_pmmUltrasonicsFaultReason 0 "NO_FAULT" 1 "BLOCKED_FRONT" 2 "BLOCKED_REAR" 3 "BLOCKED_BOTH" 4 "INVALID_MIA" ;
VAL_ 905 DAS_pmmRadarFaultReason 0 "NO_FAULT" 1 "BLOCKED_FRONT" 2 "INVALID_MIA" ;
VAL_ 905 DAS_pmmSysFaultReason 0 "NONE" 1 "DAS_DISABLED" 2 "SPEED" 3 "DI_FAULT" 4 "STEERING_ANGLE_RATE" 5 "DISABLED_BY_USER" 6 "ROAD_TYPE" 7 "BRAKE_PEDAL_INHIBIT" ;
VAL_ 905 DAS_pmmCameraFaultReason 0 "NO_FAULT" 1 "BLOCKED_FRONT" 2 "INVALID_MIA" ;
VAL_ 905 DAS_ACC_report 0 "TARGET_NONE" 1 "TARGET_CIPV" 2 "TARGET_IN_FRONT_OF_CIPV" 3 "TARGET_MCVL" 4 "TARGET_MCVR" 5 "TARGET_CUTIN" 6 "TARGET_TYPE_STOP_SIGN" 7 "TARGET_TYPE_TRAFFIC_LIGHT" 8 "TARGET_TYPE_IPSO" 9 "TARGET_TYPE_FAULT" 10 "CSA" 11 "LC_HANDS_ON_REQD_STRUCK_OUT" 12 "LC_EXTERNAL_STATE_ABORTING" 13 "LC_EXTERNAL_STATE_ABORTED" 14 "LC_EXTERNAL_STATE_ACTIVE_RESTRICTED" 15 "RADAR_OBJ_ONE" 16 "RADAR_OBJ_TWO" 17 "TARGET_MCP" 18 "FLEET_SPEEDS" 19 "MCVLR_DPP" 20 "MCVLR_IN_PATH" 21 "CIPV_CUTTING_OUT" 22 "RADAR_OBJ_FIVE" 23 "CAMERA_ONLY" 24 "BEHAVIOR_REPORT" ;
VAL_ 905 DAS_csaState 0 "UNAVAILABLE" 1 "AVAILABLE" 2 "ENABLE" 3 "HOLD" ;
VAL_ 905 DAS_radarTelemetry 0 "IDLE" 1 "NORMAL" 2 "URGENT" ;
VAL_ 905 DAS_robState 0 "INHIBITED" 1 "MEASURE" 2 "ACTIVE" 3 "MAPLESS" ;
VAL_ 905 DAS_driverInteractionLevel 0 "DRIVER_INTERACTING" 1 "DRIVER_NOT_INTERACTING" 2 "CONTINUED_DRIVER_NOT_INTERACTING" ;
VAL_ 905 DAS_ppOffsetDesiredRamp 128 "PP_NO_OFFSET" ;
VAL_ 905 DAS_longCollisionWarning 0 "NONE" 1 "VEHICLE_UNKNOWN" 2 "PEDESTRIAN" 3 "IPSO" 4 "STOPSIGN_STOPLINE" 5 "TFL_STOPLINE" 6 "VEHICLE_CIPV" 7 "VEHICLE_CUTIN" 8 "VEHICLE_MCVL" 9 "VEHICLE_MCVL2" 10 "VEHICLE_MCVR" 11 "VEHICLE_MCVR2" 12 "VEHICLE_CIPV2" 15 "SNA" ;
VAL_ 913 EPAS3S_matrixIndex 0 "AlertMatrix0" 1 "AlertMatrix1" 2 "AlertMatrix2" ;
VAL_ 917 OCS1P_matrixIndex 2 "OCS1P_AlertMatrix2" ;
VAL_ 921 DAS_autopilotState 0 "DISABLED" 1 "UNAVAILABLE" 2 "AVAILABLE" 3 "ACTIVE_NOMINAL" 4 "ACTIVE_RESTRICTED" 5 "ACTIVE_NAV" 6 "ACTIVE_FSD" 8 "ABORTING" 9 "ABORTED" 14 "FAULT" 15 "SNA" ;
VAL_ 921 DAS_blindSpotRearLeft 0 "NO_WARNING" 1 "WARNING_LEVEL_1" 2 "WARNING_LEVEL_2" 3 "SNA" ;
VAL_ 921 DAS_blindSpotRearRight 0 "NO_WARNING" 1 "WARNING_LEVEL_1" 2 "WARNING_LEVEL_2" 3 "SNA" ;
VAL_ 921 DAS_fusedSpeedLimit 0 "UNKNOWN_SNA" 31 "NONE" ;
VAL_ 921 DAS_suppressSpeedWarning 0 "Do_Not_Suppress" 1 "Suppress_Speed_Warning" ;
VAL_ 921 DAS_visionOnlySpeedLimit 0 "UNKNOWN_SNA" 31 "NONE" ;
VAL_ 921 DAS_heaterState 0 "OFF_SNA" 1 "ON" ;
VAL_ 921 DAS_forwardCollisionWarning 0 "NONE" 1 "FORWARD_COLLISION_WARNING" 3 "SNA" ;
VAL_ 921 DAS_autoparkReady 0 "UNAVAILABLE" 1 "READY" ;
VAL_ 921 DAS_lssState 0 "FAULT" 1 "LDW" 2 "LKA" 3 "ELK" 4 "MONITOR" 5 "BLINDSPOT" 6 "ABORT" 7 "OFF" ;
VAL_ 921 DAS_sideCollisionAvoid 0 "NONE" 1 "AVOID_LEFT" 2 "AVOID_RIGHT" 3 "SNA" ;
VAL_ 921 DAS_sideCollisionWarning 0 "NONE" 1 "WARN_LEFT" 2 "WARN_RIGHT" 3 "WARN_LEFT_RIGHT" ;
VAL_ 921 DAS_sideCollisionInhibit 0 "NO_INHIBIT" 1 "INHIBIT" ;
VAL_ 921 DAS_laneDepartureWarning 0 "NONE" 1 "LEFT_WARNING" 2 "RIGHT_WARNING" 3 "LEFT_WARNING_SEVERE" 4 "RIGHT_WARNING_SEVERE" 5 "SNA" ;
VAL_ 921 DAS_fleetSpeedState 0 "UNAVAILABLE" 1 "AVAILABLE" 2 "ACTIVE" 3 "HOLD" ;
VAL_ 921 DAS_autopilotHandsOnState 0 "NOT_REQD" 1 "REQD_DETECTED" 2 "REQD_NOT_DETECTED" 3 "REQD_VISUAL" 4 "REQD_CHIME_1" 5 "REQD_CHIME_2" 6 "REQD_SLOWING" 7 "REQD_STRUCK_OUT" 8 "SUSPENDED" 9 "REQD_ESCALATED_CHIME_1" 10 "REQD_ESCALATED_CHIME_2" 15 "SNA" ;
VAL_ 921 DAS_autoLaneChangeState 0 "UNAVAILABLE_DISABLED" 1 "UNAVAILABLE_NO_LANES" 2 "UNAVAILABLE_SONICS_INVALID" 3 "UNAVAILABLE_TP_FOLLOW" 4 "UNAVAILABLE_EXITING_HIGHWAY" 5 "UNAVAILABLE_VEHICLE_SPEED" 6 "AVAILABLE_ONLY_L" 7 "AVAILABLE_ONLY_R" 8 "AVAILABLE_BOTH" 9 "IN_PROGRESS_L" 10 "IN_PROGRESS_R" 11 "WAITING_FOR_SIDE_OBST_TO_PASS_L" 12 "WAITING_FOR_SIDE_OBST_TO_PASS_R" 13 "WAITING_FOR_FWD_OBST_TO_PASS_L" 14 "WAITING_FOR_FWD_OBST_TO_PASS_R" 15 "ABORT_SIDE_OBSTACLE_PRESENT_L" 16 "ABORT_SIDE_OBSTACLE_PRESENT_R" 17 "ABORT_POOR_VIEW_RANGE" 18 "ABORT_LC_HEALTH_BAD" 19 "ABORT_BLINKER_TURNED_OFF" 20 "ABORT_OTHER_REASON" 21 "UNAVAILABLE_SOLID_LANE_LINE" 22 "BLOCKED_VEH_TTC_L" 23 "BLOCKED_VEH_TTC_AND_USS_L" 24 "BLOCKED_VEH_TTC_R" 25 "BLOCKED_VEH_TTC_AND_USS_R" 26 "BLOCKED_LANE_TYPE_L" 27 "BLOCKED_LANE_TYPE_R" 28 "WAITING_HANDS_ON" 29 "ABORT_TIMEOUT" 30 "ABORT_MISSION_PLAN_INVALID" 31 "SNA" ;
VAL_ 925 IBST_iBoosterStatus 0 "OFF" 1 "INIT" 2 "FAILURE" 3 "DIAGNOSTIC" 4 "ACTIVE_GOOD_CHECK" 5 "READY" 6 "ACTUATION" ;
VAL_ 925 IBST_driverBrakeApply 0 "NOT_INIT_OR_OFF" 1 "BRAKES_NOT_APPLIED" 2 "DRIVER_APPLYING_BRAKES" 3 "FAULT" ;
VAL_ 925 IBST_internalState 0 "NO_MODE_ACTIVE" 1 "PRE_DRIVE_CHECK" 2 "LOCAL_BRAKE_REQUEST" 3 "EXTERNAL_BRAKE_REQUEST" 4 "DIAGNOSTIC" 5 "TRANSITION_TO_IDLE" 6 "POST_DRIVE_CHECK" ;
VAL_ 926 PARK_rightSideFrontRawDistData 255 "SNA" ;
VAL_ 926 PARK_rightSideRearRawDistData 255 "SNA" ;
VAL_ 926 PARK_leftSideFrontRawDistData 255 "SNA" ;
VAL_ 926 PARK_leftSideRearRawDistData 255 "SNA" ;
VAL_ 937 DAS_telemetryMultiplexer 0 "ROAD_INFORMATION" 1 "ACC_DRIVER_MONITOR" 2 "TRAFFIC_SIGNS" 7 "CSA_EVENT" 8 "STATIONARY_OBST" 9 "CRUISE_STALK_INPUT" ;
VAL_ 937 DAS_soCamCipvStatus 0 "INVALID" 1 "UNFUSED" 2 "FUSED_W_OTHER_RAD_OBJ" 3 "FUSED_W_RAD5" ;
VAL_ 937 DAS_telLeftLaneType 0 "UNDECIDED" 1 "SOLID" 2 "ROAD_EDGE" 3 "DASHED" 4 "DOUBLE" 5 "BOTTS_DOTS" 6 "BARRIER" ;
VAL_ 937 DAS_soRad5Status 0 "INVALID" 1 "UNFUSED" 2 "FUSED_W_CIPV" 3 "FUSED_W_OTHER_CAMOBJ" ;
VAL_ 937 DAS_telRightLaneType 0 "UNDECIDED" 1 "SOLID" 2 "ROAD_EDGE" 3 "DASHED" 4 "DOUBLE" 5 "BOTTS_DOTS" 6 "BARRIER" ;
VAL_ 937 DAS_soRad1Status 0 "INVALID" 1 "UNFUSED" 2 "FUSED_W_CIPV" 3 "FUSED_W_OTHER_CAMOBJ" ;
VAL_ 937 DAS_telLeftMarkerQuality 0 "LOWEST" 1 "LOW" 2 "MEDIUM" 3 "HIGH" ;
VAL_ 937 DAS_telRightMarkerQuality 0 "LOWEST" 1 "LOW" 2 "MEDIUM" 3 "HIGH" ;
VAL_ 937 DAS_telLeftMarkerColor 0 "UNKNOWN" 1 "WHITE" 2 "YELLOW" 3 "BLUE" ;
VAL_ 937 DAS_telRightMarkerColor 0 "UNKNOWN" 1 "WHITE" 2 "YELLOW" 3 "BLUE" ;
VAL_ 937 DAS_telLeftLaneCrossing 0 "NOT_CROSSING" 1 "CROSSING" ;
VAL_ 937 DAS_telRightLaneCrossing 0 "NOT_CROSSING" 1 "CROSSING" ;
